VERSION ""

NS_ :

BS_:

BU_: FC

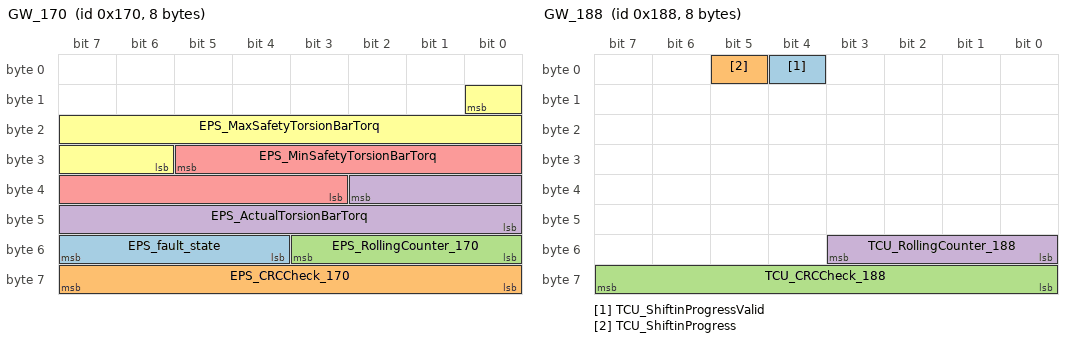
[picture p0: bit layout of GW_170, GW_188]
BO_ 368 GW_170: 8 Vector__XXX
 SG_ EPS_fault_state : 55|4@0+ (1,0) [0|15] ""  FC
 SG_ EPS_CRCCheck_170 : 63|8@0+ (1,0) [0|255] ""  FC
 SG_ EPS_RollingCounter_170 : 51|4@0+ (1,0) [0|15] ""  FC
 SG_ EPS_ActualTorsionBarTorq : 34|11@0+ (0.02,-20.48) [-20.48|20.44] "Nm"  FC
 SG_ EPS_MinSafetyTorsionBarTorq : 29|11@0+ (0.02,-20.48) [-20.48|20.44] "Nm"  FC
 SG_ EPS_MaxSafetyTorsionBarTorq : 8|11@0+ (0.02,-20.48) [-20.48|20.44] "Nm"  FC

BO_ 392 GW_188: 8 Vector__XXX
 SG_ TCU_ShiftinProgressValid : 4|1@0+ (1,0) [0|1] ""  FC
 SG_ TCU_ShiftinProgress : 5|1@0+ (1,0) [0|1] ""  FC
 SG_ TCU_CRCCheck_188 : 63|8@0+ (1,0) [0|255] ""  FC
 SG_ TCU_RollingCounter_188 : 51|4@0+ (1,0) [0|15] ""  FC

BO_ 580 FC_244: 64 FC
 SG_ ADS__RollingCounter_244 : 427|4@0+ (1,0) [0|15] "" Vector__XXX
 SG_ ADS_CRCCheck_244 : 439|16@0+ (1,0) [0|65535] "" Vector__XXX
 SG_ ADS_EOMTOReq : 155|2@0+ (1,0) [0|3] "" Vector__XXX
 SG_ ACC_HandsOnReq : 158|3@0+ (1,0) [0|7] "" Vector__XXX
 SG_ ACC_DynamicWarningLevel : 145|3@0+ (1,0) [0|7] "" Vector__XXX
 SG_ ACC_SafetyNotice : 136|7@0+ (1,0) [0|127] "" Vector__XXX
 SG_ ACC_LatTakeoverReq : 138|2@0+ (1,0) [0|3] "" Vector__XXX
 SG_ ACC_LngTakeOverReq : 140|2@0+ (1,0) [0|3] "" Vector__XXX
 SG_ ACC_TakeOverReq : 142|2@0+ (1,0) [0|3] "" Vector__XXX
 SG_ ACC_ADCNotice : 135|9@0+ (1,0) [0|511] "" Vector__XXX
 SG_ ACC_RWU_Parking_Request_Valid : 36|1@0+ (1,0) [0|1] "" Vector__XXX
 SG_ ACC_RWU_Parking_Request : 35|1@0+ (1,0) [0|1] "" Vector__XXX
 SG_ ACC_CDP_Parking_Request_Valid : 34|1@0+ (1,0) [0|1] "" Vector__XXX
 SG_ ACC_CDP_Parking_Request : 33|1@0+ (1,0) [0|1] "" Vector__XXX
 SG_ ACC_LDWShakeLevStatus : 21|2@0+ (1,0) [0|3] "" Vector__XXX
 SG_ ACC_TextInfoForDriver : 30|6@0+ (1,0) [0|63] "" Vector__XXX
 SG_ ADS_Authernticator_244 : 463|56@0+ (1,0) [0|0] "" Vector__XXX
 SG_ ADS_ResetFlag_244 : 449|2@0+ (1,0) [0|3] "" Vector__XXX
 SG_ ADS_MesssageCounter_244 : 455|6@0+ (1,0) [0|63] "" Vector__XXX
 SG_ ACC_CRCCheck_25E : 127|8@0+ (1,0) [0|255] "" Vector__XXX
 SG_ ACC_RollingCounter_25E : 115|4@0+ (1,0) [0|15] "" Vector__XXX
 SG_ ACC_AEBCtrlType : 104|4@0+ (1,0) [0|15] "" Vector__XXX
 SG_ ACC_FuelCutOffPrevention : 116|1@0+ (1,0) [0|1] "" Vector__XXX
 SG_ ACC_AccTrqReqActive : 106|1@0+ (1,0) [0|1] "" Vector__XXX
 SG_ ACC_AccTrqReq : 100|10@0+ (0.097847,0) [0|99.999634] "%" Vector__XXX
 SG_ ACC_AEBVehilceHoldReq : 90|1@0+ (1,0) [0|1] "" Vector__XXX
 SG_ ACC_FCWPreWarning : 91|1@0+ (1,0) [0|1] "" Vector__XXX
 SG_ ACC_FCWLatentWarning : 92|1@0+ (1,0) [0|1] "" Vector__XXX
 SG_ ACC_FCWActive : 93|1@0+ (1,0) [0|1] "" Vector__XXX
 SG_ ACC_PrefillActive : 94|1@0+ (1,0) [0|1] "" Vector__XXX
 SG_ ACC_AWBActive : 95|1@0+ (1,0) [0|1] "" Vector__XXX
 SG_ ACC_AWBlevel : 83|4@0+ (1,0) [0|15] "" Vector__XXX
 SG_ ACC_ABAActive : 84|1@0+ (1,0) [0|1] "" Vector__XXX
 SG_ ACC_ABAlevel : 86|2@0+ (1,0) [0|3] "" Vector__XXX
 SG_ ACC_AEBActive : 87|1@0+ (1,0) [0|1] "" Vector__XXX
 SG_ ACC_AEBTargetDeceleration : 71|16@0+ (0.0005,-16) [-16|16] "m/s2" Vector__XXX
 SG_ ACC_EmergencyDataRrdReq : 23|2@0+ (1,0) [0|3] "" Vector__XXX
 SG_ ACC_CRCCheck_24E : 63|8@0+ (1,0) [0|255] "" Vector__XXX
 SG_ ACC_RollingCounter_24E : 51|4@0+ (1,0) [0|15] "" Vector__XXX
 SG_ ACC_Driveoff_Request : 55|1@0+ (1,0) [0|1] "" Vector__XXX
 SG_ ACC_ACCMode : 54|3@0+ (1,0) [0|7] "" Vector__XXX
 SG_ ACC_CCMode : 47|3@0+ (1,0) [0|7] "" Vector__XXX
 SG_ ACC_CDDActive : 44|1@0+ (1,0) [0|1] "" Vector__XXX
 SG_ ACC_LimitSwitchArbitration : 43|2@0+ (1,0) [0|3] "" Vector__XXX
 SG_ ACC_EngineStartStopRequest : 41|2@0+ (1,0) [0|3] "" Vector__XXX
 SG_ ACC_DecToStop : 31|1@0+ (1,0) [0|1] "" Vector__XXX
 SG_ ACC_TCUCreepProhibition : 32|1@0+ (1,0) [0|1] "" Vector__XXX
 SG_ ACC_LKAStatus : 13|2@0+ (1,0) [0|3] "" Vector__XXX
 SG_ ACC_LDWVibrationWarningReq : 11|2@0+ (1,0) [0|3] "" Vector__XXX
 SG_ ACC_LDWStatus : 9|2@0+ (1,0) [0|3] "" Vector__XXX
 SG_ ACC_ACCTargetAcceleration : 7|8@0+ (0.05,-5) [-5|7.75] "m/s2" Vector__XXX

BO_ 583 APA_247: 32 Vector__XXX
 SG_ APA_APAOnOff : 6|1@0+ (1,0) [0|1] ""  FC

BO_ 664 GW_298: 8 Vector__XXX
 SG_ BCM_DriverDoorLockStatus : 44|2@0+ (1,0) [0|3] ""  FC
 SG_ BCM_LeftRearDoorStatus : 40|1@0+ (1,0) [0|1] ""  FC

BO_ 775 FC_307: 64 FC
 SG_ AD_LatDeviationDis : 55|3@0+ (1,0) [0|7] "" Vector__XXX
 SG_ AD_LatDeviationReason : 34|3@0+ (1,0) [0|7] "" Vector__XXX
 SG_ AD_IACCSuspendReason : 39|3@0+ (1,0) [0|7] "" Vector__XXX
 SG_ ACC_IACCProhibitionTime : 226|7@0+ (1,0) [0|127] "s" Vector__XXX
 SG_ ACC_Line_RR_Id : 479|8@0+ (1,0) [0|255] "" Vector__XXX
 SG_ ACC_Line_R_Id : 471|8@0+ (1,0) [0|255] "" Vector__XXX
 SG_ ACC_Line_LL_Id : 463|8@0+ (1,0) [0|255] "" Vector__XXX
 SG_ ACC_Line_L_Id : 455|8@0+ (1,0) [0|255] "" Vector__XXX
 SG_ ACC_RRLanecolor : 494|3@0+ (1,0) [0|7] "" Vector__XXX
 SG_ ACC_RLanecolor : 481|3@0+ (1,0) [0|7] "" Vector__XXX
 SG_ ACC_LLLanecolor : 484|3@0+ (1,0) [0|7] "" Vector__XXX
 SG_ ACC_LLanecolor : 487|3@0+ (1,0) [0|7] "" Vector__XXX
 SG_ ACC_VehicleStartRemindSts : 220|2@0+ (1,0) [0|3] "" Vector__XXX
 SG_ ADS_ResetSts : 218|3@0+ (1,0) [0|7] "" Vector__XXX
 SG_ ADS_IRLCEnable : 25|2@0+ (1,0) [0|3] "" Vector__XXX
 SG_ ADS_AutoDriveState : 10|3@0+ (1,0) [0|7] "-" Vector__XXX
 SG_ ACC_CRCCheck_35F : 255|8@0+ (1,0) [0|255] "" Vector__XXX
 SG_ ACC_RollingCounter_35F : 243|4@0+ (1,0) [0|15] "" Vector__XXX
 SG_ ACC_CSLAEnableStatus : 245|2@0+ (1,0) [0|3] "" Vector__XXX
 SG_ ACC_CSLSetReq : 227|1@0+ (1,0) [0|1] "" Vector__XXX
 SG_ ACC_HostPotentialTargetDirection : 231|3@0+ (1,0) [0|7] "" Vector__XXX
 SG_ ACC_HostPotentialTargetType : 199|4@0+ (1,0) [0|15] "" Vector__XXX
 SG_ ACC_HostPotentialTargetLatRange : 214|10@0+ (0.1,-50) [-50|50] "m" Vector__XXX
 SG_ ACC_HostPotentialTargetLngRange : 207|9@0+ (0.5,-70) [-70|180] "m" Vector__XXX
 SG_ ACC_HostPotentialTargetDetection : 194|3@0+ (1,0) [0|7] "" Vector__XXX
 SG_ ACC_CRCCheck_344 : 191|8@0+ (1,0) [0|255] "" Vector__XXX
 SG_ ACC_RollingCounter_344 : 179|4@0+ (1,0) [0|15] "" Vector__XXX
 SG_ ACC_FLTarget2Type : 183|4@0+ (1,0) [0|15] "" Vector__XXX
 SG_ ACC_FLTarget2LngRange : 160|9@0+ (0.5,-70) [-70|180] "m" Vector__XXX
 SG_ ACC_FLTarget2Detection : 164|3@0+ (1,0) [0|7] "" Vector__XXX
 SG_ ACC_FLTarget2Direction : 167|3@0+ (1,0) [0|7] "" Vector__XXX
 SG_ ACC_FLTarget1Direction : 158|3@0+ (1,0) [0|7] "" Vector__XXX
 SG_ ACC_FLTarget1Type : 146|4@0+ (1,0) [0|15] "" Vector__XXX
 SG_ ACC_FLTarget1LatRange : 140|10@0+ (0.1,-50) [-50|50] "m" Vector__XXX
 SG_ ACC_FLTarget1LngRange : 133|9@0+ (0.5,-70) [-70|180] "m" Vector__XXX
 SG_ ACC_FLTarget1Detection : 155|3@0+ (1,0) [0|7] "" Vector__XXX
 SG_ ACC_CRCCheck_322 : 127|8@0+ (1,0) [0|255] "" Vector__XXX
 SG_ ACC_RollingCounter_322 : 115|4@0+ (1,0) [0|15] "" Vector__XXX
 SG_ ACC_HostTargetDetection : 87|3@0+ (1,0) [0|7] "" Vector__XXX
 SG_ ACC_ACCTargetDirection : 104|3@0+ (1,0) [0|7] "" Vector__XXX
 SG_ ACC_ACCTargetLatRange : 99|10@0+ (0.1,-50) [-50|50] "m" Vector__XXX
 SG_ ACC_ACCTargetRelSpd : 92|9@0+ (1,-250) [-250|250] "km/h" Vector__XXX
 SG_ ACC_DistanceAlertLevel : 74|3@0+ (1,0) [0|7] "" Vector__XXX
 SG_ ACC_ACCTargetType : 78|4@0+ (1,0) [0|15] "" Vector__XXX
 SG_ ACC_FRadarCalibrationStatus : 94|2@0+ (1,0) [0|3] "" Vector__XXX
 SG_ ACC_ACCTargetLngRange : 71|9@0+ (0.5,-70) [-70|180] "m" Vector__XXX
 SG_ ACC_CRCCheck_35E : 63|8@0+ (1,0) [0|255] "" Vector__XXX
 SG_ ACC_RollingCounter_35E : 51|4@0+ (1,0) [0|15] "" Vector__XXX
 SG_ ACC_SaftyBeltVibrationReq : 42|1@0+ (1,0) [0|1] "" Vector__XXX
 SG_ ACC_SaftyBelt_Tightened : 41|2@0+ (1,0) [0|3] "" Vector__XXX
 SG_ ACC_CruiseSetStatus : 46|3@0+ (1,0) [0|7] "" Vector__XXX
 SG_ ACC_ACCObjSoundEnable : 36|2@0+ (1,0) [0|3] "" Vector__XXX
 SG_ ACC_FCWSettingStatus : 30|3@0+ (1,0) [0|7] "" Vector__XXX
 SG_ ACC_AEBEnable : 26|1@0+ (1,0) [0|1] "" Vector__XXX
 SG_ ACC_ACCEPBrequest : 23|1@0+ (1,0) [0|1] "" Vector__XXX
 SG_ ACC_ObjValid : 13|1@0+ (1,0) [0|1] "" Vector__XXX
 SG_ ACC_TimeGapSet : 18|3@0+ (1,0) [0|7] "" Vector__XXX
 SG_ ACC_DistanceLevel : 22|3@0+ (1,0) [0|7] "" Vector__XXX
 SG_ ACC_SetSpeed : 6|8@0+ (1,0) [0|254] "Km/h" Vector__XXX

BO_ 786 FC_312: 64 FC
 SG_ ACC_Selflearning_status : 13|2@0+ (1,0) [0|3] "" Vector__XXX
 SG_ ACC_Selflearning_angle : 238|11@0+ (0.01,-10.25) [-10.25|10.22] "degree" Vector__XXX
 SG_ ADS_ADSVoiceRequest : 102|9@0+ (1,0) [0|511] "" Vector__XXX
 SG_ ADS_ADSRoadVoiceEnableSts : 89|1@0+ (1,0) [0|1] "" Vector__XXX
 SG_ ADS_ADSLaneChangeVoiceEnableSts : 88|1@0+ (1,0) [0|1] "" Vector__XXX
 SG_ ADS_ADSSafeVoiceEnableSts : 103|1@0+ (1,0) [0|1] "" Vector__XXX
 SG_ ADS_NDANavEnableStatus : 108|1@0+ (1,0) [0|1] "" Vector__XXX
 SG_ ADS_NDAAudioWarEnableStatus : 107|1@0+ (1,0) [0|1] "" Vector__XXX
 SG_ ADS_NDAEnableStatus : 106|1@0+ (1,0) [0|1] "" Vector__XXX
 SG_ ADS_ALCDirection : 105|2@0+ (1,0) [0|3] "" Vector__XXX
 SG_ ADS_ALCTextInfoForDriver : 119|4@0+ (1,0) [0|15] "" Vector__XXX
 SG_ ADS_LaneChangeStyle : 90|1@0+ (1,0) [0|1] "" Vector__XXX
 SG_ ADS_UDLCVoiceRecStatus : 93|3@0+ (1,0) [0|7] "" Vector__XXX
 SG_ ADS_EOMStatus : 74|3@0+ (1,0) [0|7] "" Vector__XXX
 SG_ ADS_EOMSeatSteeringAdjustReq : 94|1@0+ (1,0) [0|1] "" Vector__XXX
 SG_ ADS_EOMDriverHeadPos : 77|3@0+ (1,0) [0|7] "" Vector__XXX
 SG_ ADS_EOMActiveReq : 95|1@0+ (1,0) [0|1] "" Vector__XXX
 SG_ ADS_SpdLimitedStatus : 79|2@0+ (1,0) [0|3] "" Vector__XXX
 SG_ ADS_CRCCheck_3D7 : 255|8@0+ (1,0) [0|255] "" Vector__XXX
 SG_ ADS_RollingCounter_3D7 : 243|4@0+ (1,0) [0|15] "" Vector__XXX
 SG_ ACC_SunroofControl : 231|8@0+ (1,0) [0|255] "" Vector__XXX
 SG_ ACC_RightRearWindowControl : 222|7@0+ (1,0) [0|100] "%" Vector__XXX
 SG_ ACC_LeftRearWindowControl : 214|7@0+ (1,0) [0|100] "%" Vector__XXX
 SG_ ACC_PassengerWindowControl : 206|7@0+ (1,0) [0|100] "%" Vector__XXX
 SG_ ACC_DriverWindowControl : 198|7@0+ (1,0) [0|100] "%" Vector__XXX
 SG_ ADS_UDLCTextInfoForDriver : 183|4@0+ (1,0) [0|15] "" Vector__XXX
 SG_ ADS_ToTargetLatDistance : 87|8@0+ (0.1,-10) [-10|10] "m" Vector__XXX
 SG_ ADS_AutoWiperShift_Rqe : 155|1@0+ (1,0) [0|1] "" Vector__XXX
 SG_ ACC_HornCommand : 159|2@0+ (1,0) [0|3] "" Vector__XXX
 SG_ ADS_AutoHeadlightshift_Req : 163|1@0+ (1,0) [0|1] "" Vector__XXX
 SG_ ADS_HighBeamLampOnRequest : 174|2@0+ (1,0) [0|3] "" Vector__XXX
 SG_ ADS_LowBeamLampOnRequest : 132|2@0+ (1,0) [0|3] "" Vector__XXX
 SG_ ADS_LightFrequencyRequest : 150|3@0+ (1,0) [0|7] "" Vector__XXX
 SG_ ADS_LightBrightRequest : 137|3@0+ (1,0) [0|7] "" Vector__XXX
 SG_ ADS_LightFlashRequest : 171|1@0+ (1,0) [0|1] "" Vector__XXX
 SG_ ADS_LightColorRequest : 170|3@0+ (1,0) [0|7] "" Vector__XXX
 SG_ ADS_LightingReq : 175|1@0+ (1,0) [0|1] "" Vector__XXX
 SG_ ADS_rescueReq : 65|2@0+ (1,0) [0|1] "" Vector__XXX
 SG_ ADS_SafeStopSts : 67|2@0+ (1,0) [0|3] "" Vector__XXX
 SG_ ADS_EyesOffWarningInhi : 68|1@0+ (1,0) [0|1] "" Vector__XXX
 SG_ ADS_EOMWarnning : 71|3@0+ (1,0) [0|7] "" Vector__XXX
 SG_ ADS_ESSEnable : 157|1@0+ (1,0) [0|1] "" Vector__XXX
 SG_ ADS_CRCCheck_358 : 191|8@0+ (1,0) [0|255] "" Vector__XXX
 SG_ ADS_RollingCounter_358 : 179|4@0+ (1,0) [0|15] "" Vector__XXX
 SG_ ADS_RLaneColor : 162|3@0+ (1,0) [0|7] "" Vector__XXX
 SG_ ADS_LLaneColor : 166|3@0+ (1,0) [0|7] "" Vector__XXX
 SG_ ADS_UDLCTurnRightRequest : 156|1@0+ (1,0) [0|1] "" Vector__XXX
 SG_ ADS_UDLCRightStatus : 147|4@0+ (1,0) [0|15] "" Vector__XXX
 SG_ ADS_UDLCTurnLeftRequest : 167|1@0+ (1,0) [0|1] "" Vector__XXX
 SG_ ADS_UDLCTurnLightReq : 154|3@0+ (1,0) [0|7] "" Vector__XXX
 SG_ ADS_UDLCLeftStatus : 141|4@0+ (1,0) [0|15] "" Vector__XXX
 SG_ ADS_UDLCStatus : 129|4@0+ (1,0) [0|15] "" Vector__XXX
 SG_ ADS_UDLCEnableStatus : 130|1@0+ (1,0) [0|1] "" Vector__XXX
 SG_ ADS_ESSMode : 135|3@0+ (1,0) [0|7] "" Vector__XXX
 SG_ ADS_CRCCheck_342 : 127|8@0+ (1,0) [0|255] "" Vector__XXX
 SG_ ADS_RollingCounter_342 : 115|4@0+ (1,0) [0|15] "" Vector__XXX
 SG_ ACC_CRCCheck_3E4 : 63|8@0+ (1,0) [0|255] "" Vector__XXX
 SG_ ACC_RollingCounter_3E4 : 51|4@0+ (1,0) [0|15] "" Vector__XXX
 SG_ ACC_AEBTargetDirection : 47|3@0+ (1,0) [0|7] "" Vector__XXX
 SG_ ACC_AEBTargetDetection : 44|1@0+ (1,0) [0|1] "" Vector__XXX
 SG_ ACC_AEBTargetType : 43|4@0+ (1,0) [0|15] "" Vector__XXX
 SG_ ACC_RLaneDistanceFusion : 38|7@0+ (0.05,-1) [-1|5] "m" Vector__XXX
 SG_ ACC_LLaneDistanceFusion : 30|7@0+ (0.05,-1) [-1|5] "m" Vector__XXX
 SG_ ACC_HostPotentialTargetID : 19|4@0+ (1,0) [0|15] "" Vector__XXX
 SG_ ACC_FRTarget2ID : 55|4@0+ (1,0) [0|15] "" Vector__XXX
 SG_ ACC_FRTarget1ID : 11|4@0+ (1,0) [0|15] "" Vector__XXX
 SG_ ACC_FLTarget2ID : 23|4@0+ (1,0) [0|15] "" Vector__XXX
 SG_ ACC_FLTarget1ID : 1|4@0+ (1,0) [0|15] "" Vector__XXX
 SG_ ACC_ACCTargetID : 6|4@0+ (1,0) [0|15] "" Vector__XXX

BO_ 832 IBCMR_340: 8 Vector__XXX
 SG_ AC_FrBlowType : 2|3@0+ (1,0) [0|7] ""  FC

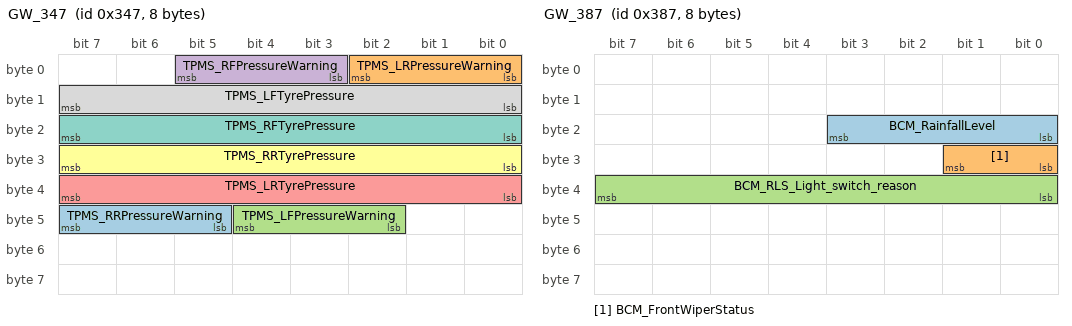
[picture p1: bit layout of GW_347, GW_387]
BO_ 839 GW_347: 8 Vector__XXX
 SG_ TPMS_RRPressureWarning : 47|3@0+ (1,0) [0|7] ""  FC
 SG_ TPMS_LRPressureWarning : 2|3@0+ (1,0) [0|7] ""  FC
 SG_ TPMS_LFPressureWarning : 44|3@0+ (1,0) [0|7] ""  FC
 SG_ TPMS_RFPressureWarning : 5|3@0+ (1,0) [0|7] ""  FC
 SG_ TPMS_LRTyrePressure : 39|8@0+ (1.373,0) [0|350] "KPa"  FC
 SG_ TPMS_RRTyrePressure : 31|8@0+ (1.373,0) [0|350] "KPa"  FC
 SG_ TPMS_RFTyrePressure : 23|8@0+ (1.373,0) [0|350] "KPa"  FC
 SG_ TPMS_LFTyrePressure : 15|8@0+ (1.373,0) [0|350] "KPa"  FC

BO_ 869 GW_365: 32 Vector__XXX
 SG_ IMS_RollingCounter_3A7 : 179|4@0+ (1,0) [0|15] ""  FC
 SG_ IMS_CRCCheck_3A7 : 191|8@0+ (1,0) [0|255] ""  FC
 SG_ IMS_RollingCounter_360 : 115|4@0+ (1,0) [0|15] ""  FC
 SG_ IMS_CRCCheck_360 : 127|8@0+ (1,0) [0|255] ""  FC
 SG_ IMS_HeadDetectSts_Yaw : 87|8@0+ (1,-75) [-75|75] "度"  FC
 SG_ IMS_HeadDetectSts_Roll : 79|8@0+ (1,-45) [-45|45] "度"  FC
 SG_ IMS_HeadDetectSts_Pitch : 71|8@0+ (1,-25) [-25|45] "度"  FC
 SG_ IMS_RollingCounter_356 : 51|4@0+ (1,0) [0|15] ""  FC
 SG_ IMS_CRCCheck_356 : 63|8@0+ (1,0) [0|255] ""  FC
 SG_ IMS_IMSStatus : 0|3@0+ (1,0) [0|7] ""  FC
 SG_ IMS_EyeGazeStatus : 21|8@0+ (1,-75) [-75|75] "度"  FC
 SG_ IMS_EyeDetectSatus : 13|8@0+ (1,0) [0|100] "%"  FC
 SG_ IMS_DrowsinessStatus : 3|3@0+ (1,0) [0|7] ""  FC
 SG_ IMS_DriverHeadDetect : 5|2@0+ (1,0) [0|3] ""  FC
 SG_ IMS_DistractionStatus : 7|2@0+ (1,0) [0|3] ""  FC

BO_ 870 IBCMR_366: 8 Vector__XXX
 SG_ AC_EnvironmentalTemp : 23|8@0+ (0.5,-40) [-40|87] "degreeC"  FC
 SG_ AC_EnvironmentalTempVD : 8|1@0+ (1,0) [0|1] ""  FC

BO_ 903 GW_387: 8 Vector__XXX
 SG_ BCM_RainfallLevel : 19|4@0+ (1,0) [0|15] ""  FC
 SG_ BCM_FrontWiperStatus : 25|2@0+ (1,0) [0|3] ""  FC
 SG_ BCM_RLS_Light_switch_reason : 39|8@0+ (1,0) [0|255] ""  FC

BO_ 912 GW_390: 8 Vector__XXX
 SG_ BCM_SOH_LifePercent : 15|8@0+ (1,0) [0|100] "%"  FC
 SG_ BCM_PMSLevel : 5|3@0+ (1,0) [0|7] ""  FC

BO_ 918 GW_396: 8 Vector__XXX
 SG_ BCM_SunroofStatus : 0|1@0+ (1,0) [0|1] ""  FC

BO_ 1287 GW_507: 64 Vector__XXX
 SG_ HU_NDAAudioWarEnable : 169|2@0+ (1,0) [0|3] ""  FC
 SG_ HU_TJPEnable : 49|2@0+ (1,0) [0|3] ""  FC
 SG_ HU_VC_CruiseSetSpeed : 151|8@0+ (1,0) [0|255] ""  FC
 SG_ HU_VC_CruiseSetDistance : 142|3@0+ (1,0) [0|7] ""  FC
 SG_ HU_VC_CruiseControl : 138|3@0+ (1,0) [0|7] ""  FC
 SG_ HU_FCWSetting : 165|3@0+ (1,0) [0|7] ""  FC
 SG_ HU_ACCObjEnable : 128|2@0+ (1,0) [0|3] ""  FC
 SG_ HU_CruiseControlSet : 135|3@0+ (1,0) [0|7] ""  FC
 SG_ HU_AutoBrakeEnable : 131|1@0+ (1,0) [0|1] ""  FC
 SG_ HU_IACCEnable : 29|2@0+ (1,0) [0|3] ""  FC
 SG_ HU_LDWShakeLev : 23|2@0+ (1,0) [0|3] ""  FC
 SG_ HU_RCTAEnable : 0|2@0+ (1,0) [0|3] ""  FC
 SG_ HU_HMAEnable : 12|1@0+ (1,0) [0|1] ""  FC
 SG_ HU_TSRSwitch : 11|1@0+ (1,0) [0|1] ""  FC
 SG_ HU_LASWarningModeSelection : 10|3@0+ (1,0) [0|7] ""  FC
 SG_ HU_LASModeSelection : 5|3@0+ (1,0) [0|7] ""  FC
 SG_ HU_OverspeedWarningOffset : 38|5@0+ (1,-10) [-10|10] ""  FC
 SG_ HU_OverspeedWarningEnable : 33|2@0+ (1,0) [0|3] ""  FC
 SG_ HU_OverspeedSoundWarEnable : 31|2@0+ (1,0) [0|3] ""  FC

BO_ 1302 GW_516: 32 Vector__XXX
 SG_ HU_LocalTimeSystem : 111|2@0+ (1,0) [0|3] ""  FC
 SG_ HU_LocalTimeSecond : 109|6@0+ (1,0) [0|59] "second"  FC
 SG_ HU_LocalTimeMinute : 101|6@0+ (1,0) [0|59] "minute"  FC
 SG_ HU_LocalTimeHour : 92|5@0+ (1,0) [0|23] "hour"  FC
 SG_ HU_LocalTimeDate : 84|5@0+ (1,0) [1|31] "day"  FC
 SG_ HU_LocalTimeYear : 119|8@0+ (1,2013) [2013|2268] "year"  FC
 SG_ HU_LocalTimeMonth : 75|4@0+ (1,0) [1|12] "month"  FC
 SG_ HU_LocalTimeValid : 71|1@0+ (1,0) [0|1] ""  FC
 SG_ HU_CurrentLocationLatitude : 35|28@0+ (1E-006,-134.217727) [-90|90] "degree"  FC
 SG_ HU_CurrentLocationLongitude : 4|29@0+ (1E-006,-268.435455) [-180|180] "degree"  FC
 SG_ HU_CurrentLocationValid : 7|1@0+ (1,0) [0|1] ""  FC

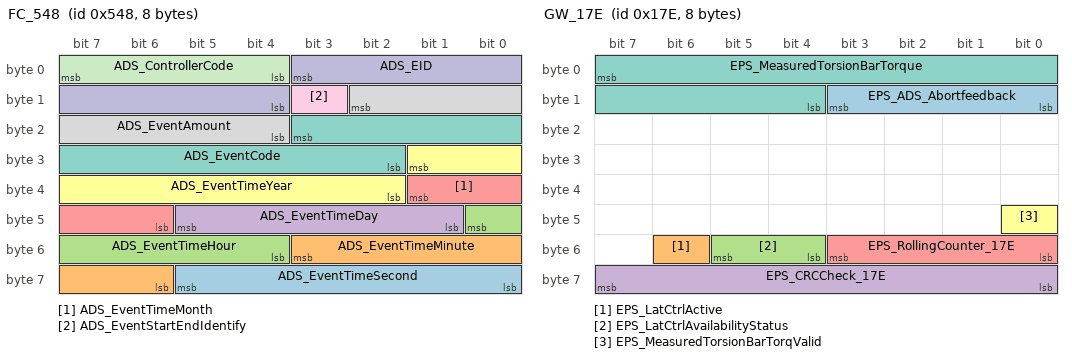
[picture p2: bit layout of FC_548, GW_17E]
BO_ 1352 FC_548: 8 FC
 SG_ ADS_EventTimeSecond : 61|6@0+ (1,0) [0|59] "秒" Vector__XXX
 SG_ ADS_EventTimeMinute : 51|6@0+ (1,0) [0|59] "分" Vector__XXX
 SG_ ADS_EventTimeHour : 40|5@0+ (1,0) [0|23] "时" Vector__XXX
 SG_ ADS_EventTimeDay : 45|5@0+ (1,0) [0|31] "日" Vector__XXX
 SG_ ADS_EventTimeMonth : 33|4@0+ (1,0) [0|15] "月" Vector__XXX
 SG_ ADS_EventTimeYear : 25|8@0+ (1,2013) [2013|2268] "年" Vector__XXX
 SG_ ADS_EventCode : 19|10@0+ (1,0) [0|1023] "" Vector__XXX
 SG_ ADS_EventAmount : 10|7@0+ (1,0) [0|127] "" Vector__XXX
 SG_ ADS_EventStartEndIdentify : 11|1@0+ (1,0) [0|1] "" Vector__XXX
 SG_ ADS_EID : 3|8@0+ (1,0) [0|255] "" Vector__XXX
 SG_ ADS_ControllerCode : 7|4@0+ (1,0) [0|15] "" Vector__XXX

BO_ 1554 APA_612: 8 Vector__XXX
 SG_ DVR_EmergencyRecordStatus : 29|2@0+ (1,0) [0|3] ""  FC
 SG_ DVR_Error : 15|1@0+ (1,0) [0|1] ""  FC

BO_ 382 GW_17E: 8 Vector__XXX
 SG_ EPS_ADS_Abortfeedback : 11|4@0+ (1,0) [0|15] ""  FC
 SG_ EPS_LatCtrlActive : 54|1@0+ (1,0) [0|1] ""  FC
 SG_ EPS_LatCtrlAvailabilityStatus : 53|2@0+ (1,0) [0|3] ""  FC
 SG_ EPS_CRCCheck_17E : 63|8@0+ (1,0) [0|255] ""  FC
 SG_ EPS_RollingCounter_17E : 51|4@0+ (1,0) [0|15] ""  FC
 SG_ EPS_MeasuredTorsionBarTorqValid : 40|1@0+ (1,0) [0|1] ""  FC
 SG_ EPS_MeasuredTorsionBarTorque : 7|12@0+ (0.01,-20.48) [-20.48|20.46] "Nm"  FC

BO_ 398 GW_18E: 32 Vector__XXX
 SG_ EMS_RollingCounter_18E : 235|4@0+ (1,0) [0|15] ""  FC
 SG_ EMS_CRCCheck_18E : 247|16@0+ (1,0) [0|65535] ""  FC
 SG_ EMS_CRCCheck_1A6 : 191|8@0+ (1,0) [0|255] ""  FC
 SG_ EMS_RollingCounter_1A6 : 179|4@0+ (1,0) [0|15] ""  FC
 SG_ EMS_EngineStatus : 183|2@0+ (1,0) [0|3] ""  FC
 SG_ EMS_MinIndicatedTorq : 167|8@0+ (0.392,0) [0|99.568] "%"  FC
 SG_ EMS_MaxIndicatedTorq : 159|8@0+ (0.392,0) [0|99.568] "%"  FC
 SG_ EMS_TorqueConstant : 151|8@0+ (10,0) [0|2540] "NM"  FC
 SG_ EMS_RollingCounter_196 : 115|4@0+ (1,0) [0|15] ""  FC
 SG_ EMS_CRCCheck_196 : 127|8@0+ (1,0) [0|255] ""  FC
 SG_ EMS_AccPedal : 111|8@0+ (0.392,0) [0|99.568] "%"  FC
 SG_ EMS_EngineSpeed : 87|16@0+ (0.25,0) [0|16383.5] "Rpm"  FC
 SG_ EMS_AccpedelError : 74|1@0+ (1,0) [0|1] ""  FC
 SG_ EMS_EngineSpeedError : 76|1@0+ (1,0) [0|1] ""  FC
 SG_ EMS_EngineFuelCutOff : 78|1@0+ (1,0) [0|1] ""  FC
 SG_ EMS_BrakePedalStatus : 119|2@0+ (1,0) [0|3] ""  FC
 SG_ EMS_RealAccPedal : 71|8@0+ (0.392,0) [0|99.568] "%"  FC
 SG_ EMS_RollingCounter_184 : 51|4@0+ (1,0) [0|15] ""  FC
 SG_ EMS_CRCCheck_184 : 63|8@0+ (1,0) [0|255] ""  FC
 SG_ EMS_IndicatedRealEngTorq : 39|16@0+ (0.001526,0) [0|99.99878] "%"  FC
 SG_ EMS_FrictionalTorq : 23|16@0+ (0.001526,0) [0|99.99878] "%"  FC
 SG_ EMS_IndicatedDriverReqTorq : 7|16@0+ (0.001526,0) [0|99.99878] "%"  FC
 SG_ EMS_TorqFailure : 53|1@0+ (1,0) [0|1] ""  FC

BO_ 442 FC_1BA: 32 FC
 SG_ ACC_LatAngReqActive : 35|1@0+ (1,0) [0|1] "" Vector__XXX
 SG_ ACC_LatAngReq : 17|14@0+ (0.1,-720) [-720|720] "degree" Vector__XXX
 SG_ ADS_Authernticator_1BA : 207|56@0+ (1,0) [0|0] "" Vector__XXX
 SG_ ADS_ResetFlag_1BA : 193|2@0+ (1,0) [0|3] "" Vector__XXX
 SG_ ADS_MesssageCounter_1BA : 199|6@0+ (1,0) [0|63] "" Vector__XXX
 SG_ ACC_CRCCheck_1BA_0 : 63|8@0+ (1,0) [0|255] "" Vector__XXX
 SG_ ACC_RollingCounter_1BA_0 : 51|4@0+ (1,0) [0|15] "" Vector__XXX
 SG_ ADS_ESSActive : 34|1@0+ (1,0) [0|1] "" Vector__XXX
 SG_ ACC_MotorTorqueMinLimitRequest : 12|11@0+ (0.02,-20.48) [-20.48|20.44] "Nm" Vector__XXX
 SG_ ACC_MotorTorqueMaxLimitRequest : 7|11@0+ (0.02,-20.48) [-20.48|20.44] "Nm" Vector__XXX

BO_ 588 GW_24C: 8 Vector__XXX
 SG_ TCU_RollingCounter_24C : 51|4@0+ (1,0) [0|15] ""  FC

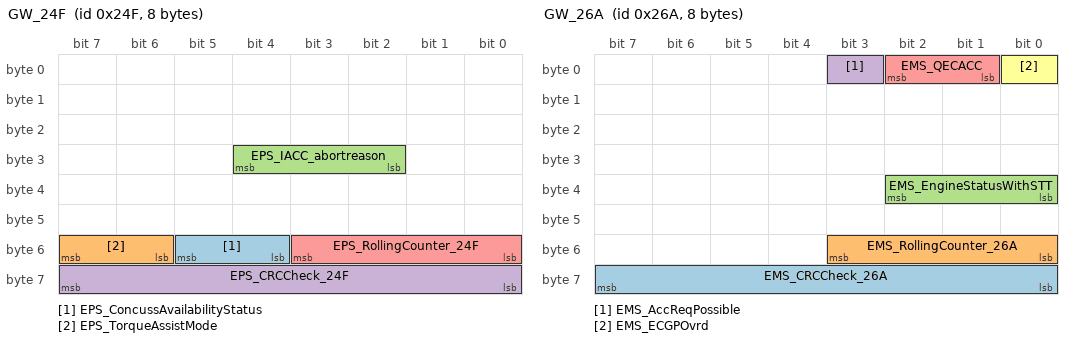
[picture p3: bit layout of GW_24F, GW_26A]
BO_ 591 GW_24F: 8 Vector__XXX
 SG_ EPS_ConcussAvailabilityStatus : 53|2@0+ (1,0) [0|3] ""  FC
 SG_ EPS_TorqueAssistMode : 55|2@0+ (1,0) [0|3] ""  FC
 SG_ EPS_IACC_abortreason : 28|3@0+ (1,0) [0|7] ""  FC
 SG_ EPS_CRCCheck_24F : 63|8@0+ (1,0) [0|255] ""  FC
 SG_ EPS_RollingCounter_24F : 51|4@0+ (1,0) [0|15] ""  FC

BO_ 618 GW_26A: 8 Vector__XXX
 SG_ EMS_CRCCheck_26A : 63|8@0+ (1,0) [0|255] ""  FC
 SG_ EMS_RollingCounter_26A : 51|4@0+ (1,0) [0|15] ""  FC
 SG_ EMS_EngineStatusWithSTT : 34|3@0+ (1,0) [0|7] ""  FC
 SG_ EMS_AccReqPossible : 3|1@0+ (1,0) [0|1] ""  FC
 SG_ EMS_QECACC : 2|2@0+ (1,0) [0|3] ""  FC
 SG_ EMS_ECGPOvrd : 0|1@0+ (1,0) [0|1] ""  FC

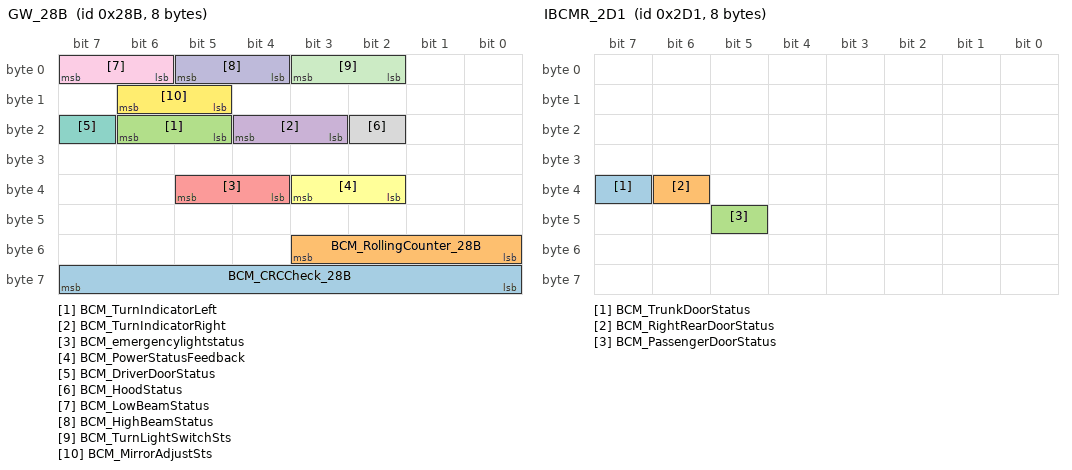
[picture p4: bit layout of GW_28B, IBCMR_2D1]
BO_ 651 GW_28B: 8 Vector__XXX
 SG_ BCM_CRCCheck_28B : 63|8@0+ (1,0) [0|255] ""  FC
 SG_ BCM_RollingCounter_28B : 51|4@0+ (1,0) [0|15] ""  FC
 SG_ BCM_TurnIndicatorLeft : 22|2@0+ (1,0) [0|3] ""  FC
 SG_ BCM_TurnIndicatorRight : 20|2@0+ (1,0) [0|3] ""  FC
 SG_ BCM_emergencylightstatus : 37|2@0+ (1,0) [0|3] ""  FC
 SG_ BCM_PowerStatusFeedback : 35|2@0+ (1,0) [0|3] ""  FC
 SG_ BCM_DriverDoorStatus : 23|1@0+ (1,0) [0|1] ""  FC
 SG_ BCM_HoodStatus : 18|1@0+ (1,0) [0|1] ""  FC
 SG_ BCM_LowBeamStatus : 7|2@0+ (1,0) [0|3] ""  FC
 SG_ BCM_HighBeamStatus : 5|2@0+ (1,0) [0|3] ""  FC
 SG_ BCM_TurnLightSwitchSts : 3|2@0+ (1,0) [0|3] ""  FC
 SG_ BCM_MirrorAdjustSts : 14|2@0+ (1,0) [0|3] ""  FC

BO_ 676 GW_2A4: 64 Vector__XXX
 SG_ RRC_RollingCounter_2A4 : 491|4@0+ (1,0) [0|15] ""  FC
 SG_ RRC_CRCCheck_2A4 : 503|16@0+ (1,0) [0|65535] ""  FC
 SG_ LCDAR_RCTBStatus : 17|2@0+ (1,0) [0|3] ""  FC
 SG_ LCDAR_CRCCheck_2AF : 63|8@0+ (1,0) [0|255] ""  FC
 SG_ LCDAR_RollingCounter_2AF : 51|4@0+ (1,0) [0|15] ""  FC
 SG_ LCDAR_ELK_oAlert : 25|2@0+ (1,0) [0|3] ""  FC
 SG_ LCDAR_ELK_oStatus : 27|2@0+ (1,0) [0|3] ""  FC
 SG_ LCDAR_Left_ELK_oAlert : 29|2@0+ (1,0) [0|3] ""  FC
 SG_ LCDAR_RCTBActive : 19|1@0+ (1,0) [0|1] ""  FC
 SG_ LCDAR_RCTBTargetDecel : 39|16@0+ (0.0005,-16) [-16|16] "m/s2"  FC
 SG_ LCDAR_RCTBEnable : 18|1@0+ (1,0) [0|1] ""  FC
 SG_ LCDAR_SystemStatus : 12|3@0+ (1,0) [0|7] ""  FC

BO_ 710 APA_2C6: 64 Vector__XXX
 SG_ APA_vehicleFrontdetect : 99|2@0+ (1,0) [0|3] ""  FC

BO_ 721 IBCMR_2D1: 8 Vector__XXX
 SG_ BCM_TrunkDoorStatus : 39|1@0+ (1,0) [0|1] ""  FC
 SG_ BCM_RightRearDoorStatus : 38|1@0+ (1,0) [0|1] ""  FC
 SG_ BCM_PassengerDoorStatus : 45|1@0+ (1,0) [0|1] ""  FC

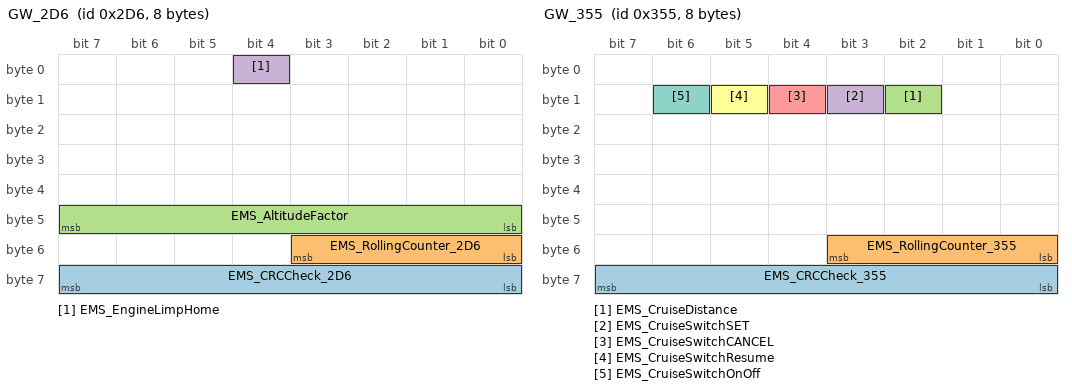
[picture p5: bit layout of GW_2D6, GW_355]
BO_ 726 GW_2D6: 8 Vector__XXX
 SG_ EMS_CRCCheck_2D6 : 63|8@0+ (1,0) [0|255] ""  FC
 SG_ EMS_RollingCounter_2D6 : 51|4@0+ (1,0) [0|15] ""  FC
 SG_ EMS_AltitudeFactor : 47|8@0+ (0.01575,0) [0|4] ""  FC
 SG_ EMS_EngineLimpHome : 4|1@0+ (1,0) [0|1] ""  FC

BO_ 794 FC_31A: 64 FC
 SG_ AD_HandsoffWarningExitReason : 42|3@0+ (1,0) [0|7] "" Vector__XXX
 SG_ ACC_LngTakeOverReqReason : 232|5@0+ (1,0) [0|31] "" Vector__XXX
 SG_ ACC_ELKAlert : 25|2@0+ (1,0) [0|3] "" Vector__XXX
 SG_ ADS_HWAEnableStatus : 180|1@0+ (1,0) [0|1] "" Vector__XXX
 SG_ ADS_IsInFence : 208|2@0+ (1,0) [0|3] "" Vector__XXX
 SG_ ADS_TJPEnableStatus : 67|1@0+ (1,0) [0|1] "" Vector__XXX
 SG_ ACC_CRCCheck_367 : 255|8@0+ (1,0) [0|255] "" Vector__XXX
 SG_ ACC_RollingCounter_367 : 243|4@0+ (1,0) [0|15] "" Vector__XXX
 SG_ ACC_LatPathHeadingAngle : 227|11@0- (0.1,0) [-90|90] "degree" Vector__XXX
 SG_ ACC_LatPathDY : 221|10@0- (0.01,0) [-5|5] "m" Vector__XXX
 SG_ ACC_ELKEnableStatus : 222|1@0+ (1,0) [0|1] "" Vector__XXX
 SG_ ACC_ELKInterventionMode : 210|2@0+ (1,0) [0|3] "" Vector__XXX
 SG_ ACC_ELKMode : 213|3@0+ (1,0) [0|7] "" Vector__XXX
 SG_ ACC_HostPedLatRange_1 : 205|8@0+ (0.2,-25) [-25|25] "m" Vector__XXX
 SG_ ACC_HostPedLngRange_1 : 195|6@0+ (1,0) [0|62] "m" Vector__XXX
 SG_ ACC_HostPedDetection_1 : 198|2@0+ (1,0) [0|3] "" Vector__XXX
 SG_ ACC_CRCCheck_30D : 191|8@0+ (1,0) [0|255] "" Vector__XXX
 SG_ ACC_RollingCounter_30D : 179|4@0+ (1,0) [0|15] "" Vector__XXX
 SG_ ACC_RRLaneDistance : 172|6@0+ (0.2,0) [0|12] "m" Vector__XXX
 SG_ ACC_RRLaneDetection : 174|2@0+ (1,0) [0|3] "" Vector__XXX
 SG_ ACC_LLLaneDistance : 165|6@0+ (0.2,0) [0|12] "m" Vector__XXX
 SG_ ACC_LLLaneDetection : 167|2@0+ (1,0) [0|3] "" Vector__XXX
 SG_ ACC_DoorCtrlReq : 145|2@0+ (1,0) [0|3] "" Vector__XXX
 SG_ ACC_HighBeamControl : 182|2@0+ (1,0) [0|3] "" Vector__XXX
 SG_ ACC_TargetBasedLateralControl : 150|2@0+ (1,0) [0|3] "" Vector__XXX
 SG_ ACC_IACCHWATextInfoForDriver : 143|5@0+ (1,0) [0|31] "" Vector__XXX
 SG_ ACC_EmergencyLightingRequest : 148|2@0+ (1,0) [0|3] "" Vector__XXX
 SG_ ACC_HandsoffFuncTextinfo : 158|4@0+ (1,0) [0|15] "" Vector__XXX
 SG_ ACC_HandsoffFuncStatus : 154|3@0+ (1,0) [0|7] "" Vector__XXX
 SG_ ACC_DriverHandsOffStatus : 137|2@0+ (1,0) [0|3] "" Vector__XXX
 SG_ ACC_IACCHWAMode : 135|3@0+ (1,0) [0|7] "" Vector__XXX
 SG_ ACC_CRCCheck_30A : 127|8@0+ (1,0) [0|255] "" Vector__XXX
 SG_ ACC_RollingCounter_30A : 115|4@0+ (1,0) [0|15] "" Vector__XXX
 SG_ ACC_LaneChangeStatus : 117|2@0+ (1,0) [0|3] "" Vector__XXX
 SG_ ACC_RoadCurvatureFar : 109|7@0+ (0.0005,-0.03) [-0.03|0.03] "1/m" Vector__XXX
 SG_ ACC_RoadCurvatureNear : 100|7@0+ (0.0005,-0.03) [-0.03|0.03] "1/m" Vector__XXX
 SG_ ACC_RoadCurvature : 91|7@0+ (0.0005,-0.03) [-0.03|0.03] "1/m" Vector__XXX
 SG_ ACC_IACCHWAEnable : 78|1@0+ (1,0) [0|1] "" Vector__XXX
 SG_ ACC_RLaneMarkerType : 70|3@0+ (1,0) [0|7] "" Vector__XXX
 SG_ ACC_LLaneMarkerType : 94|3@0+ (1,0) [0|7] "" Vector__XXX
 SG_ ACC_HostLaneRightStatus : 87|4@0+ (1,0) [0|15] "" Vector__XXX
 SG_ ACC_HostLaneLeftStatus : 83|4@0+ (1,0) [0|15] "" Vector__XXX
 SG_ ACC_LASWarningModeSelectionSts : 74|3@0+ (1,0) [0|7] "" Vector__XXX
 SG_ ACC_LASModeSelectionStatus : 66|3@0+ (1,0) [0|7] "" Vector__XXX
 SG_ ACC_CRCCheck_36D : 63|8@0+ (1,0) [0|255] "" Vector__XXX
 SG_ ACC_RollingCounter_36D : 51|4@0+ (1,0) [0|15] "" Vector__XXX
 SG_ ACC_FRadarFailureStatus : 53|2@0+ (1,0) [0|3] "" Vector__XXX
 SG_ ACC_AEBTargetLatRange : 21|10@0+ (0.1,-50) [-50|50] "m" Vector__XXX
 SG_ ACC_AEBTargetRelSpeed : 14|9@0+ (1,-250) [-250|250] "km/h" Vector__XXX
 SG_ ACC_AEBTargetLngRange : 7|9@0+ (0.5,-70) [-70|180] "m" Vector__XXX
 SG_ ACC_Voiceinfo : 47|5@0+ (1,0) [0|31] "" Vector__XXX
 SG_ ACC_AEBTargetmode : 33|2@0+ (1,0) [0|3] "" Vector__XXX
 SG_ ACC_AEBTextInfo : 37|4@0+ (1,0) [0|15] "" Vector__XXX
 SG_ ACC_AEBStatus : 39|2@0+ (1,0) [0|3] "" Vector__XXX

BO_ 879 FC_36F: 64 FC
 SG_ ACC_RollingCounter_36F : 491|4@0+ (1,0) [0|15] "" Vector__XXX
 SG_ ACC_CRCCheck_36F : 503|16@0+ (1,0) [0|65535] "" Vector__XXX
 SG_ ADS_PathShow_Sts : 292|3@0+ (1,0) [0|7] "" Vector__XXX
 SG_ ADS_NDAFenceTerminalDis : 289|10@0+ (10,0) [0|3000] "m" Vector__XXX
 SG_ ADS_NDATextInfo : 286|5@0+ (1,0) [0|31] "" Vector__XXX
 SG_ ADS_NDAStatus : 311|4@0+ (1,0) [0|15] "" Vector__XXX
 SG_ ACC_CRCCheck_3CD : 319|8@0+ (1,0) [0|255] "" Vector__XXX
 SG_ ACC_RollingCounter_3CD : 307|4@0+ (1,0) [0|15] "" Vector__XXX
 SG_ ACC_CRCCheck_3CB : 255|8@0+ (1,0) [0|255] "" Vector__XXX
 SG_ ACC_RollingCounter_3CB : 243|4@0+ (1,0) [0|15] "" Vector__XXX
 SG_ ACC_CRCCheck_3CA : 191|8@0+ (1,0) [0|255] "" Vector__XXX
 SG_ ACC_RollingCounter_3CA : 179|4@0+ (1,0) [0|15] "" Vector__XXX
 SG_ ACC_CRCCheck_3C8 : 127|8@0+ (1,0) [0|255] "" Vector__XXX
 SG_ ACC_RollingCounter_3C8 : 115|4@0+ (1,0) [0|15] "" Vector__XXX
 SG_ ACC_CRCCheck_374 : 63|8@0+ (1,0) [0|255] "" Vector__XXX
 SG_ ACC_RollingCounter_374 : 51|4@0+ (1,0) [0|15] "" Vector__XXX
 SG_ ADS_TunnelStatus : 265|2@0+ (1,0) [0|3] "" Vector__XXX
 SG_ ADS_TunnelDis : 279|9@0+ (1,0) [0|400] "m" Vector__XXX
 SG_ ADS_RampStatus : 268|3@0+ (1,0) [0|3] "" Vector__XXX
 SG_ ADS_PathThroughRamp : 270|2@0+ (1,0) [0|3] "" Vector__XXX
 SG_ ADS_RampSide : 246|2@0+ (1,0) [0|3] "" Vector__XXX
 SG_ ADS_DisToRamp : 263|9@0+ (1,0) [0|400] "m" Vector__XXX
 SG_ ADS_PathShowLngRange : 238|8@0+ (1,0) [0|200] "m" Vector__XXX
 SG_ ADS_RoadMergeLatRange : 218|12@0+ (0.01,-16) [-16|16] "m" Vector__XXX
 SG_ ADS_EOMNotice : 223|5@0+ (1,0) [0|31] "" Vector__XXX
 SG_ ADS_SeatPostureRectifyReq : 212|3@0+ (1,0) [0|7] "" Vector__XXX
 SG_ ADS_PromptCountDown : 205|7@0+ (1,0) [0|100] "s" Vector__XXX
 SG_ ADS_EOMDwgradingnotice : 192|3@0+ (1,0) [0|7] "" Vector__XXX
 SG_ ADS_AutoDriveStateDisplay : 196|4@0+ (1,0) [0|15] "" Vector__XXX
 SG_ ADS_PathShow_Status : 183|3@0+ (1,0) [0|7] "" Vector__XXX
 SG_ ADS_PathShow_C3 : 163|12@0+ (4.768E-007,-0.0009760857) [-0.0009760857|0.0009760857] "" Vector__XXX
 SG_ ADS_PathShow_C2 : 159|12@0+ (1.52588E-005,-0.0312347412) [-0.0312347412|0.0312347412] "" Vector__XXX
 SG_ ADS_PathShow_C1 : 139|12@0+ (0.0004882813,-1) [-1|0.9990234375] "" Vector__XXX
 SG_ ADS_RoadSlopeFlag : 72|1@0+ (1,0) [0|1] "-" Vector__XXX
 SG_ ADS_RoadSlopeShapeC3 : 135|12@0+ (4.768E-007,-0.0009760857) [-0.0009760857|0.0009760857] "" Vector__XXX
 SG_ ADS_RoadSlopeShapeC2 : 99|12@0+ (1.52588E-005,-0.0312347412) [-0.0312347412|0.0312347412] "" Vector__XXX
 SG_ ADS_RoadSlopeShapeC1 : 95|12@0+ (0.0004882813,-1) [-1|0.9990234375] "rad" Vector__XXX
 SG_ ADS_RoadMergeFlag : 73|1@0+ (1,0) [0|1] "-" Vector__XXX
 SG_ ADS_RoadLngRange : 87|8@0+ (1,0) [0|255] "m" Vector__XXX
 SG_ ADS_RemoteRoadShapeC3 : 69|12@0+ (4.768E-007,-0.0009760857) [-0.0009760857|0.0009760857] "" Vector__XXX
 SG_ ADS_RemoteRoadShapeC2 : 32|12@0+ (1.52588E-005,-0.0312347412) [-0.0312347412|0.0312347412] "" Vector__XXX
 SG_ ADS_RemoteRoadShapeC1 : 28|12@0+ (0.0004882813,-1) [-1|0.9990234375] "rad" Vector__XXX
 SG_ ACC_TakeoverReqAtIPFail : 71|2@0+ (1,0) [0|3] "" Vector__XXX
 SG_ ADS_TSRHostNextSpdLimitDist : 23|9@0+ (1,0) [0|400] "" Vector__XXX
 SG_ ADS_TSRHostNextSpdLimit : 15|8@0+ (1,0) [0|255] "" Vector__XXX
 SG_ ADS_RightPedWarnLevel : 30|2@0+ (1,0) [0|7] "" Vector__XXX
 SG_ ADS_RightPedDetection : 1|2@0+ (1,0) [0|3] "" Vector__XXX
 SG_ ADS_LeftPedWarnLevel : 3|2@0+ (1,0) [0|7] "" Vector__XXX
 SG_ ADS_LeftPedDetection : 5|2@0+ (1,0) [0|3] "" Vector__XXX
 SG_ ADS_HostPedWarnLevel_1 : 7|2@0+ (1,0) [0|7] "" Vector__XXX

BO_ 922 FC_39A: 64 FC
 SG_ LAS_TSRSpeedLimitType : 7|2@0+ (1,0) [0|3] "" Vector__XXX
 SG_ ACC_RollingCounter_39A : 491|4@0+ (1,0) [0|15] "" Vector__XXX
 SG_ ACC_CRCCheck_39A : 503|16@0+ (1,0) [0|65535] "" Vector__XXX
 SG_ LAS_TSRRightLaneStatus : 55|3@0+ (1,0) [0|7] "" Vector__XXX
 SG_ LAS_TSRLeftLaneStatus : 47|3@0+ (1,0) [0|7] "" Vector__XXX
 SG_ LAS_CRCCheck_3C0 : 191|8@0+ (1,0) [0|255] "" Vector__XXX
 SG_ LAS_RollingCounter_3C0 : 179|4@0+ (1,0) [0|15] "" Vector__XXX
 SG_ LAS_TSRRightLaneSpdLimit : 143|8@0+ (1,0) [0|255] "" Vector__XXX
 SG_ LAS_TSRLeftLaneSpdLimit : 135|8@0+ (1,0) [0|255] "" Vector__XXX
 SG_ LAS_CRCCheck_3D4 : 127|8@0+ (1,0) [0|255] "" Vector__XXX
 SG_ LAS_RollingCounter_3D4 : 115|4@0+ (1,0) [0|15] "" Vector__XXX
 SG_ LAS_TLAStopLine_HostLane : 111|8@0+ (1,0) [0|255] "" Vector__XXX
 SG_ LAS_TLADistance_HostLane : 103|8@0+ (1,0) [0|255] "" Vector__XXX
 SG_ LAS_TLACountDownTime_HostLane : 94|7@0+ (1,0) [0|127] "" Vector__XXX
 SG_ LAS_TSRMandatorySign : 70|4@0+ (1,0) [0|15] "" Vector__XXX
 SG_ LAS_TSRWarningSign : 83|4@0+ (1,0) [0|15] "" Vector__XXX
 SG_ LAS_TSRProhibitionSign : 66|5@0+ (1,0) [0|31] "" Vector__XXX
 SG_ LAS_CRCCheck_332 : 63|8@0+ (1,0) [0|255] "" Vector__XXX
 SG_ LAS_RollingCounter_332 : 51|4@0+ (1,0) [0|15] "" Vector__XXX
 SG_ LAS_OverspeedSoundWarningEnSt : 27|1@0+ (1,0) [0|1] "" Vector__XXX
 SG_ LAS_TSREnable : 30|1@0+ (1,0) [0|1] "" Vector__XXX
 SG_ LAS_HMAEnableStatus : 22|1@0+ (1,0) [0|1] "" Vector__XXX
 SG_ LAS_HMALightDistribution : 8|1@0+ (1,0) [0|1] "" Vector__XXX
 SG_ LAS_HMAStatus : 44|2@0+ (1,0) [0|3] "" Vector__XXX
 SG_ LAS_TSRHostSpdLimitUnits : 41|2@0+ (1,0) [0|3] "" Vector__XXX
 SG_ LAS_TSRHostSpdLimit : 39|8@0+ (1,0) [0|255] "" Vector__XXX
 SG_ LAS_TSRStatus : 26|3@0+ (1,0) [0|7] "" Vector__XXX
 SG_ LAS_FrontCameraCalibrationStatus : 20|2@0+ (1,0) [0|3] "" Vector__XXX
 SG_ LAS_FrontCameraFailureStatus : 17|2@0+ (1,0) [0|3] "" Vector__XXX
 SG_ LAS_OverspeedWarningOffset : 14|5@0+ (1,-10) [-10|10] "km/h" Vector__XXX
 SG_ LAS_OverspeedWarningEnableStatus : 15|1@0+ (1,0) [0|1] "" Vector__XXX
 SG_ LAS_OverspeedSoundWarning : 2|1@0+ (1,0) [0|1] "" Vector__XXX
 SG_ LAS_OverspeedVisualWarning : 5|1@0+ (1,0) [0|1] "" Vector__XXX
 SG_ LAS_RoadSignCenterLatRange_Rlane : 306|9@0+ (0.05,-8) [-8|17.55] "m" Vector__XXX
 SG_ LAS_RoadSignCenterLngRange_RLane : 299|9@0+ (0.1,0) [0|51.1] "m" Vector__XXX
 SG_ LAS_RoadSignCenterLatRange_LLane : 292|9@0+ (0.05,-8) [-8|17.55] "m" Vector__XXX
 SG_ LAS_RoadSignCenterLngRange_LLane : 285|9@0+ (0.1,0) [0|51.1] "m" Vector__XXX
 SG_ LAS_RoadSignCenterLatRange_HLane : 278|9@0+ (0.05,-8) [-8|17.55] "m" Vector__XXX
 SG_ LAS_RoadSignCenterLngRange_HLane : 271|9@0+ (0.1,0) [0|51.1] "m" Vector__XXX
 SG_ LAS_CrosswalkLngRange_HLane : 263|8@0+ (1,0) [0|255] "" Vector__XXX
 SG_ LAS_RoadSignType_RLane : 157|5@0+ (1,0) [0|15] "" Vector__XXX
 SG_ LAS_RoadSignType_LLane : 146|5@0+ (1,0) [0|15] "" Vector__XXX
 SG_ LAS_RoadSignType_HLane : 151|5@0+ (1,0) [0|15] "" Vector__XXX
 SG_ LAS_CRCCheck_37D : 255|8@0+ (1,0) [0|255] "" Vector__XXX
 SG_ LAS_RollingCounter_37D : 243|4@0+ (1,0) [0|15] "" Vector__XXX
 SG_ LAS_TLAArrowDirection_RightLane : 236|3@0+ (1,0) [0|7] "" Vector__XXX
 SG_ LAS_TLAObjectType_RightLane : 239|3@0+ (1,0) [0|7] "" Vector__XXX
 SG_ LAS_TLAObjectStatus_RightLane : 247|2@0+ (1,0) [0|3] "" Vector__XXX
 SG_ LAS_TLAObjectColour_RightLane : 225|2@0+ (1,0) [0|3] "" Vector__XXX
 SG_ LAS_TLAObjectDetection_RightLane : 227|1@0+ (1,0) [0|1] "" Vector__XXX
 SG_ LAS_TLAArrowDirection_LeftLane : 216|3@0+ (1,0) [0|7] "" Vector__XXX
 SG_ LAS_TLAObjectType_LeftLane : 219|3@0+ (1,0) [0|7] "" Vector__XXX
 SG_ LAS_TLAObjectStatus_LeftLane : 245|2@0+ (1,0) [0|3] "" Vector__XXX
 SG_ LAS_TLAObjectColour_LeftLane : 221|2@0+ (1,0) [0|3] "" Vector__XXX
 SG_ LAS_TLAObjectDetection_LeftLane : 223|1@0+ (1,0) [0|1] "" Vector__XXX
 SG_ LAS_TLAArrowDirection_HostLane : 215|3@0+ (1,0) [0|7] "" Vector__XXX
 SG_ LAS_TLAObjectStatus_HostLane : 199|2@0+ (1,0) [0|3] "" Vector__XXX
 SG_ LAS_TLAObjectType_HostLane : 212|3@0+ (1,0) [0|7] "" Vector__XXX
 SG_ LAS_TLAObjectColour_HostLane : 204|2@0+ (1,0) [0|3] "" Vector__XXX
 SG_ LAS_TLAObjectDetection_HostLane : 200|1@0+ (1,0) [0|1] "" Vector__XXX
 SG_ LAS_TLAWarninglevel : 197|2@0+ (1,0) [0|3] "" Vector__XXX
 SG_ LAS_TLAStatus : 193|2@0+ (1,0) [0|3] "" Vector__XXX
 SG_ LAS_TLAEnable : 194|1@0+ (1,0) [0|1] "" Vector__XXX

BO_ 853 GW_355: 8 Vector__XXX
 SG_ EMS_CRCCheck_355 : 63|8@0+ (1,0) [0|255] ""  FC
 SG_ EMS_RollingCounter_355 : 51|4@0+ (1,0) [0|15] ""  FC
 SG_ EMS_CruiseDistance : 10|1@0+ (1,0) [0|1] ""  FC
 SG_ EMS_CruiseSwitchSET : 11|1@0+ (1,0) [0|1] ""  FC
 SG_ EMS_CruiseSwitchCANCEL : 12|1@0+ (1,0) [0|1] ""  FC
 SG_ EMS_CruiseSwitchResume : 13|1@0+ (1,0) [0|1] ""  FC
 SG_ EMS_CruiseSwitchOnOff : 14|1@0+ (1,0) [0|1] ""  FC

BO_ 941 APA_3AD: 8 Vector__XXX
 SG_ DVR_SdcardErrorStatus : 7|3@0+ (1,0) [0|7] ""  FC

BO_ 943 GW_3AF: 64 Vector__XXX
 SG_ HU_LaneConfluenceDis : 155|6@0+ (10,0) [0|600] "m"  FC
 SG_ HU_LaneConfluence : 157|2@0+ (1,0) [0|3] ""  FC
 SG_ HU_CRCCheck_3AF : 255|8@0+ (1,0) [0|255] ""  FC
 SG_ HU_RollingCounter_3AF : 243|4@0+ (1,0) [0|15] ""  FC
 SG_ HU_RampDistance : 239|10@0+ (10,0) [0|3000] "m"  FC
 SG_ HU_NavSpeedLimitType : 231|2@0+ (1,0) [0|3] ""  FC
 SG_ HU_CurveDistance : 229|6@0+ (10,0) [0|600] "m"  FC
 SG_ HU_EnterCurveInfo : 220|2@0+ (1,0) [0|3] ""  FC
 SG_ HU_NavCurrentRoadType : 218|3@0+ (1,0) [0|7] ""  FC
 SG_ HU_EnterRampInfo : 215|2@0+ (1,0) [0|3] ""  FC
 SG_ HU_RampInfo : 209|2@0+ (1,0) [0|3] ""  FC
 SG_ HU_NavCountryCode : 199|8@0+ (1,0) [0|255] ""  FC
 SG_ HU_NavStatus : 223|1@0+ (1,0) [0|1] ""  FC
 SG_ HU_NavSpeedLimitUnits : 213|2@0+ (1,0) [0|3] ""  FC
 SG_ HU_NavSpeedLimitStatus : 211|2@0+ (1,0) [0|3] ""  FC
 SG_ HU_NavSpeedLimit : 207|8@0+ (1,0) [0|255] ""  FC
 SG_ HU_CRCCheck_3BB : 319|8@0+ (1,0) [0|255] ""  FC
 SG_ HU_RollingCounter_3BB : 307|4@0+ (1,0) [0|15] ""  FC
 SG_ HU_SlopeGradientFar : 281|10@0+ (0.1,-51.1) [-51.1|51.1] "%"  FC
 SG_ HU_SlopeGradient : 265|10@0+ (0.1,-51.1) [-51.1|51.1] "%"  FC
 SG_ HU_SpeedLimitDistance : 261|6@0+ (10,0) [0|600] "m"  FC

BO_ 957 GW_3BD: 64 Vector__XXX
 SG_ HU_CSLAEnable : 7|2@0+ (1,0) [0|3] ""  FC
 SG_ HU_ELKEnable : 1|2@0+ (1,0) [0|3] ""  FC
 SG_ HU_TLAEnable : 9|2@0+ (1,0) [0|3] ""  FC

BO_ 964 GW_3C4: 64 Vector__XXX
 SG_ HU_CRCCheck_3C7 : 319|8@0+ (1,0) [0|255] ""  FC
 SG_ HU_RollingCounter_3C7 : 307|4@0+ (1,0) [0|15] ""  FC
 SG_ HU_CRCCheck_3C6 : 255|8@0+ (1,0) [0|255] ""  FC
 SG_ HU_RollingCounter_3C6 : 243|4@0+ (1,0) [0|15] ""  FC
 SG_ HU_CRCCheck_3C4 : 191|8@0+ (1,0) [0|255] ""  FC
 SG_ HU_RollingCounter_3C4 : 179|4@0+ (1,0) [0|15] ""  FC
 SG_ HU_CRCCheck_3C2 : 127|8@0+ (1,0) [0|255] ""  FC
 SG_ HU_RollingCounter_3C2 : 115|4@0+ (1,0) [0|15] ""  FC
 SG_ HU_MapMatchStatus : 309|2@0+ (1,0) [0|3] ""  FC
 SG_ HU_MapDataUpdateStatus : 118|3@0+ (1,0) [0|7] ""  FC
 SG_ HU_SlopeGradient_300m : 303|10@0+ (0.1,-51.1) [-51.1|51.1] "%"  FC
 SG_ HU_RoadCurvature_600m : 281|10@0+ (1,0) [0|1023] "1/m"  FC
 SG_ HU_RoadCurvature_400m : 275|10@0+ (1,0) [0|1023] "1/m"  FC
 SG_ HU_RoadCurvature_300m : 269|10@0+ (1,0) [0|1023] "1/m"  FC
 SG_ HU_RoadCurvature_100m : 263|10@0+ (1,0) [0|1023] "1/m"  FC
 SG_ HU_RoadCurvature_90m : 239|10@0+ (1,0) [0|1023] "1/m"  FC
 SG_ HU_RoadCurvature_80m : 217|10@0+ (1,0) [0|1023] "1/m"  FC
 SG_ HU_RoadCurvature_70m : 211|10@0+ (1,0) [0|1023] "1/m"  FC
 SG_ HU_RoadCurvature_60m : 205|10@0+ (1,0) [0|1023] "1/m"  FC
 SG_ HU_RoadCurvature_50m : 199|10@0+ (1,0) [0|1023] "1/m"  FC
 SG_ HU_RoadCurvature_40m : 161|10@0+ (1,0) [0|1023] "1/m"  FC
 SG_ HU_RoadCurvature_30m : 155|10@0+ (1,0) [0|1023] "1/m"  FC
 SG_ HU_RoadCurvature_20m : 149|10@0+ (1,0) [0|1023] "1/m"  FC
 SG_ HU_RoadCurvature_10m : 143|10@0+ (1,0) [0|1023] "1/m"  FC
 SG_ HU_Road_TrafficFlow : 105|3@0+ (1,0) [0|7] ""  FC
 SG_ HU_Lane_Changtype : 129|2@0+ (1,0) [0|3] ""  FC
 SG_ HU_To_NumchangeOfLanes_Dist : 135|6@0+ (10,0) [0|600] "m"  FC
 SG_ HU_To_Branch_Dis : 111|6@0+ (10,0) [0|600] "m"  FC
 SG_ HU_BranchInfo : 245|2@0+ (1,0) [0|3] ""  FC
 SG_ HU_To_TrafficAccident_Dis : 101|6@0+ (10,0) [0|600] "m"  FC
 SG_ HU_TrafficAccident_Info : 103|2@0+ (1,0) [0|3] ""  FC
 SG_ HU_To_Construction_Dis : 93|6@0+ (10,0) [0|600] "m"  FC
 SG_ HU_Construction_Info : 95|2@0+ (1,0) [0|3] ""  FC
 SG_ HU_TollDis : 85|6@0+ (10,0) [0|600] "m"  FC
 SG_ HU_TollInfo : 87|2@0+ (1,0) [0|3] ""  FC
 SG_ HU_FallingRockDi : 77|6@0+ (10,0) [0|600] "m"  FC
 SG_ HU_FallingRockInfo : 79|2@0+ (1,0) [0|3] ""  FC
 SG_ HU_LaneCnt : 66|3@0+ (1,0) [0|7] ""  FC
 SG_ HU_ForwardRoadType : 69|3@0+ (1,0) [0|7] ""  FC
 SG_ HU_RampSide : 71|2@0+ (1,0) [0|3] ""  FC
 SG_ HU_CRCCheck_3B8 : 63|8@0+ (1,0) [0|255] ""  FC
 SG_ HU_RollingCounter_3B8 : 51|4@0+ (1,0) [0|15] ""  FC
 SG_ HU_NavGuiganceStatus : 47|2@0+ (1,0) [0|3] ""  FC
 SG_ HU_SlopeDistance : 45|6@0+ (10,0) [0|600] "m"  FC
 SG_ HU_Byroad : 39|2@0+ (1,0) [0|3] ""  FC
 SG_ HU_TunnelLength : 37|6@0+ (1,0) [0|63] "m"  FC
 SG_ HU_RoadCurvatureFar : 17|10@0+ (1,0) [0|1023] ""  FC
 SG_ HU_TunnelDistance : 23|6@0+ (10,0) [0|600] "m"  FC
 SG_ HU_RoadCurvature : 1|10@0+ (1,0) [0|1023] ""  FC
 SG_ HU_EnterSlopeInfo : 5|2@0+ (1,0) [0|3] ""  FC
 SG_ HU_EnterTunnelInfo : 3|2@0+ (1,0) [0|3] ""  FC

CM_ BO_ 368 " ";
CM_ SG_ 368 EPS_fault_state " ";
CM_ SG_ 368 EPS_CRCCheck_170 "平台为10ms，CD569特例为8ms ";
CM_ SG_ 368 EPS_RollingCounter_170 "平台为10ms，CD569特例为8ms ";
CM_ SG_ 368 EPS_ActualTorsionBarTorq "平台为10ms，CD569特例为8ms ";
CM_ SG_ 368 EPS_MinSafetyTorsionBarTorq "平台为10ms，CD569特例为8ms ";
CM_ SG_ 368 EPS_MaxSafetyTorsionBarTorq "平台为10ms，CD569特例为8ms ";
CM_ BO_ 392 " ";
CM_ SG_ 392 TCU_ShiftinProgressValid "AT/DCT ";
CM_ SG_ 392 TCU_ShiftinProgress "AT/DCT ";
CM_ SG_ 392 TCU_CRCCheck_188 " ";
CM_ SG_ 392 TCU_RollingCounter_188 "AT/DCT
rollingcounter ";
CM_ BO_ 580 " ";
CM_ SG_ 580 ACC_RWU_Parking_Request_Valid " ";
CM_ SG_ 580 ACC_RWU_Parking_Request " ";
CM_ SG_ 580 ACC_CDP_Parking_Request_Valid " ";
CM_ SG_ 580 ACC_CDP_Parking_Request " ";
CM_ SG_ 580 ADS_Authernticator_244 " ";
CM_ SG_ 580 ADS_ResetFlag_244 " ";
CM_ SG_ 580 ADS_MesssageCounter_244 " ";
CM_ SG_ 580 ACC_AEBCtrlType " ";
CM_ SG_ 580 ACC_EmergencyDataRrdReq " ";
CM_ SG_ 580 ACC_CRCCheck_24E " ";
CM_ SG_ 580 ACC_RollingCounter_24E "rolling counter ";
CM_ SG_ 580 ACC_EngineStartStopRequest "0x1: EngineAutoStopRequest (请求发动机进入STOP状态)；
0x2:EngineAutoStartRequest(请求发动机进入到START状态)； ";
CM_ SG_ 580 ACC_LKAStatus "GW报文转发 ";
CM_ SG_ 580 ACC_LDWVibrationWarningReq "有ACC、LAS时由ACC发送，其余由APA或AVM发送 ";
CM_ SG_ 580 ACC_LDWStatus "有ACC、LAS时由ACC发送，其余由APA或AVM发送 ";
CM_ SG_ 580 ACC_ACCTargetAcceleration "ACC target acceleration for transmission. ";
CM_ BO_ 583 " ";
CM_ BO_ 664 " ";
CM_ BO_ 775 " ";
CM_ SG_ 775 ACC_Line_RR_Id "同一条车线未打断车线ID不变，一定距离内车线ID不重复 ";
CM_ SG_ 775 ACC_Line_R_Id "同一条车线未打断车线ID不变，一定距离内车线ID不重复 ";
CM_ SG_ 775 ACC_Line_LL_Id "同一条车线未打断车线ID不变，一定距离内车线ID不重复 ";
CM_ SG_ 775 ACC_Line_L_Id "同一条车线未打断车线ID不变，一定距离内车线ID不重复 ";
CM_ SG_ 775 ADS_IRLCEnable " ";
CM_ SG_ 775 ADS_AutoDriveState "IACC配置车型无此信号 ";
CM_ SG_ 775 ACC_CRCCheck_35F " ";
CM_ SG_ 775 ACC_RollingCounter_35F "rolling counter ";
CM_ SG_ 775 ACC_CSLAEnableStatus " ";
CM_ SG_ 775 ACC_HostPotentialTargetDirection " ";
CM_ SG_ 775 ACC_HostPotentialTargetLngRange "负数代表向后，正数代表向前，原点为前雷达波束发射面 ";
CM_ SG_ 775 ACC_CRCCheck_344 " ";
CM_ SG_ 775 ACC_RollingCounter_344 "rolling counter ";
CM_ SG_ 775 ACC_FLTarget2LngRange "负数代表向后，正数代表向前，原点为前雷达波束发射面 ";
CM_ SG_ 775 ACC_FLTarget2Direction " ";
CM_ SG_ 775 ACC_FLTarget1Direction " ";
CM_ SG_ 775 ACC_FLTarget1LngRange "负数代表向后，正数代表向前，原点为前雷达波束发射面 ";
CM_ SG_ 775 ACC_CRCCheck_322 " ";
CM_ SG_ 775 ACC_RollingCounter_322 "rolling counter ";
CM_ SG_ 775 ACC_ACCTargetDirection " ";
CM_ SG_ 775 ACC_ACCTargetLatRange " ";
CM_ SG_ 775 ACC_ACCTargetRelSpd " ";
CM_ SG_ 775 ACC_ACCTargetLngRange "负数代表向后，正数代表向前，原点为前雷达波束发射面 ";
CM_ SG_ 775 ACC_SaftyBeltVibrationReq " ";
CM_ SG_ 775 ACC_SaftyBelt_Tightened " ";
CM_ BO_ 786 " ";
CM_ SG_ 786 ACC_Selflearning_status " ";
CM_ SG_ 786 ACC_Selflearning_angle " ";
CM_ SG_ 786 ADS_ADSRoadVoiceEnableSts " ";
CM_ SG_ 786 ADS_ADSLaneChangeVoiceEnableSts " ";
CM_ SG_ 786 ADS_ADSSafeVoiceEnableSts " ";
CM_ SG_ 786 ADS_NDANavEnableStatus " ";
CM_ SG_ 786 ADS_NDAAudioWarEnableStatus " ";
CM_ SG_ 786 ADS_NDAEnableStatus " ";
CM_ SG_ 786 ADS_ALCDirection " ";
CM_ SG_ 786 ADS_ALCTextInfoForDriver " ";
CM_ SG_ 786 ADS_LaneChangeStyle " ";
CM_ SG_ 786 ADS_UDLCVoiceRecStatus " ";
CM_ SG_ 786 ADS_EOMStatus " ";
CM_ SG_ 786 ADS_EOMSeatSteeringAdjustReq " ";
CM_ SG_ 786 ADS_EOMDriverHeadPos " ";
CM_ SG_ 786 ADS_EOMActiveReq " ";
CM_ SG_ 786 ADS_SpdLimitedStatus "IACC配置车型无此信号 ";
CM_ SG_ 786 ADS_CRCCheck_3D7 " ";
CM_ SG_ 786 ADS_RollingCounter_3D7 "rolling counter ";
CM_ SG_ 786 ACC_SunroofControl " ";
CM_ SG_ 786 ACC_RightRearWindowControl " ";
CM_ SG_ 786 ACC_LeftRearWindowControl " ";
CM_ SG_ 786 ACC_PassengerWindowControl " ";
CM_ SG_ 786 ACC_DriverWindowControl " ";
CM_ SG_ 786 ADS_AutoWiperShift_Rqe " ";
CM_ SG_ 786 ACC_HornCommand " ";
CM_ SG_ 786 ADS_AutoHeadlightshift_Req " ";
CM_ SG_ 786 ADS_HighBeamLampOnRequest " ";
CM_ SG_ 786 ADS_LowBeamLampOnRequest " ";
CM_ SG_ 786 ADS_LightFrequencyRequest " ";
CM_ SG_ 786 ADS_LightBrightRequest " ";
CM_ SG_ 786 ADS_LightFlashRequest " ";
CM_ SG_ 786 ADS_LightColorRequest " ";
CM_ SG_ 786 ADS_LightingReq " ";
CM_ SG_ 786 ADS_ESSEnable " ";
CM_ SG_ 786 ADS_CRCCheck_358 " ";
CM_ SG_ 786 ADS_RollingCounter_358 "rolling counter ";
CM_ SG_ 786 ADS_RLaneColor " ";
CM_ SG_ 786 ADS_LLaneColor " ";
CM_ SG_ 786 ADS_UDLCTurnRightRequest " ";
CM_ SG_ 786 ADS_UDLCRightStatus " ";
CM_ SG_ 786 ADS_UDLCTurnLeftRequest " ";
CM_ SG_ 786 ADS_UDLCTurnLightReq " ";
CM_ SG_ 786 ADS_UDLCLeftStatus " ";
CM_ SG_ 786 ADS_UDLCStatus " ";
CM_ SG_ 786 ADS_UDLCEnableStatus " ";
CM_ SG_ 786 ADS_ESSMode " ";
CM_ SG_ 786 ADS_CRCCheck_342 " ";
CM_ SG_ 786 ADS_RollingCounter_342 "rolling counter ";
CM_ SG_ 786 ACC_CRCCheck_3E4 " ";
CM_ SG_ 786 ACC_RollingCounter_3E4 "rolling counter ";
CM_ BO_ 832 " ";
CM_ BO_ 839 " ";
CM_ SG_ 839 TPMS_RRPressureWarning "无效值是为转DBC ";
CM_ SG_ 839 TPMS_LRPressureWarning "无效值是为转DBC ";
CM_ SG_ 839 TPMS_LFPressureWarning "无效值是为转DBC ";
CM_ SG_ 839 TPMS_RFPressureWarning "无效值是为转DBC ";
CM_ BO_ 869 " ";
CM_ SG_ 869 IMS_HeadDetectSts_Yaw " ";
CM_ SG_ 869 IMS_HeadDetectSts_Roll " ";
CM_ SG_ 869 IMS_HeadDetectSts_Pitch " ";
CM_ SG_ 869 IMS_IMSStatus " ";
CM_ SG_ 869 IMS_EyeGazeStatus " ";
CM_ SG_ 869 IMS_EyeDetectSatus "10以下认为闭眼 ";
CM_ SG_ 869 IMS_DrowsinessStatus " ";
CM_ SG_ 869 IMS_DriverHeadDetect " ";
CM_ SG_ 869 IMS_DistractionStatus " ";
CM_ BO_ 870 " ";
CM_ BO_ 903 " ";
CM_ BO_ 912 " ";
CM_ SG_ 912 BCM_PMSLevel "无效值是为转DBC ";
CM_ BO_ 918 " ";
CM_ BO_ 1287 " ";
CM_ SG_ 1287 HU_NDAAudioWarEnable " ";
CM_ SG_ 1287 HU_FCWSetting " ";
CM_ SG_ 1287 HU_IACCEnable "513(周期)和514(事件)，当前多数项目使用514(事件)报文。 ";
CM_ SG_ 1287 HU_LDWShakeLev "513(周期)和514(事件)，当前多数项目使用514(事件)报文。 ";
CM_ SG_ 1287 HU_RCTAEnable "513(周期)和514(事件)，当前多数项目使用514(事件)报文。 ";
CM_ SG_ 1287 HU_HMAEnable "513(周期)和514(事件)，当前多数项目使用514(事件)报文。 ";
CM_ SG_ 1287 HU_TSRSwitch "513(周期)和514(事件)，当前多数项目使用514(事件)报文。 ";
CM_ SG_ 1287 HU_LASWarningModeSelection "513(周期)和514(事件)，当前多数项目使用514(事件)报文。 ";
CM_ SG_ 1287 HU_LASModeSelection "513(周期)和514(事件)，当前多数项目使用514(事件)报文。 ";
CM_ SG_ 1287 HU_OverspeedWarningOffset "513(周期)和514(事件)，当前多数项目使用514(事件)报文。 ";
CM_ SG_ 1287 HU_OverspeedWarningEnable "513(周期)和514(事件)，当前多数项目使用514(事件)报文。 ";
CM_ SG_ 1287 HU_OverspeedSoundWarEnable "513(周期)和514(事件)，当前多数项目使用514(事件)报文。 ";
CM_ BO_ 1302 " ";
CM_ BO_ 1352 " ";
CM_ SG_ 1352 ADS_EventTimeSecond " ";
CM_ SG_ 1352 ADS_EventTimeMinute " ";
CM_ SG_ 1352 ADS_EventTimeHour " ";
CM_ SG_ 1352 ADS_EventTimeDay " ";
CM_ SG_ 1352 ADS_EventTimeMonth " ";
CM_ SG_ 1352 ADS_EventTimeYear " ";
CM_ SG_ 1352 ADS_EventCode " ";
CM_ SG_ 1352 ADS_EventAmount " ";
CM_ SG_ 1352 ADS_EventStartEndIdentify " ";
CM_ SG_ 1352 ADS_EID " ";
CM_ SG_ 1352 ADS_ControllerCode " ";
CM_ BO_ 1554 " ";
CM_ SG_ 1554 DVR_EmergencyRecordStatus "GW报文转发
APA5.0的车型由SCAN转发 ";
CM_ SG_ 1554 DVR_Error "GW报文转发
APA5.0的车型由SCAN转发 ";
CM_ BO_ 382 " ";
CM_ SG_ 382 EPS_ADS_Abortfeedback "平台为10ms，CD569特例为8ms ";
CM_ SG_ 382 EPS_LatCtrlActive "平台为10ms，CD569特例为8ms ";
CM_ SG_ 382 EPS_LatCtrlAvailabilityStatus "平台为10ms，CD569特例为8ms ";
CM_ SG_ 382 EPS_CRCCheck_17E "平台为10ms，CD569特例为8ms ";
CM_ SG_ 382 EPS_RollingCounter_17E "1.rolling counter
2.平台为10ms，CD569特例为8ms ";
CM_ SG_ 382 EPS_MeasuredTorsionBarTorqValid "平台为10ms，CD569特例为8ms ";
CM_ SG_ 382 EPS_MeasuredTorsionBarTorque "平台为10ms，CD569特例为8ms ";
CM_ BO_ 398 " ";
CM_ SG_ 398 EMS_CRCCheck_1A6 "ACM接收为AT/DCT专用 ";
CM_ SG_ 398 EMS_RollingCounter_1A6 "ACM接收为AT/DCT专用 ";
CM_ SG_ 398 EMS_EngineStatus "ACM接收为AT/DCT专用 ";
CM_ SG_ 398 EMS_MinIndicatedTorq "TCU接收为DCT专用 ";
CM_ SG_ 398 EMS_MaxIndicatedTorq "TCU接收为DCT专用 ";
CM_ SG_ 398 EMS_RollingCounter_196 "ACM接收为AT专用 ";
CM_ SG_ 398 EMS_CRCCheck_196 "ACM接收为AT专用 ";
CM_ SG_ 398 EMS_AccPedal "ACM接收为AT专用 ";
CM_ SG_ 398 EMS_EngineFuelCutOff "TCU接收为DCT专用 ";
CM_ SG_ 398 EMS_BrakePedalStatus "表示驾驶员踩下制动踏板的真实状态
ACM接收为AT专用 ";
CM_ SG_ 398 EMS_CRCCheck_184 " ";
CM_ SG_ 398 EMS_IndicatedDriverReqTorq "TCU接收为AT/DCT专用 ";
CM_ BO_ 442 " ";
CM_ SG_ 442 ACC_LatAngReqActive " ";
CM_ SG_ 442 ACC_LatAngReq " ";
CM_ SG_ 442 ADS_Authernticator_1BA " ";
CM_ SG_ 442 ADS_ResetFlag_1BA " ";
CM_ SG_ 442 ADS_MesssageCounter_1BA " ";
CM_ SG_ 442 ACC_CRCCheck_1BA_0 " ";
CM_ SG_ 442 ACC_RollingCounter_1BA_0 "GW报文转发
rolling counter ";
CM_ SG_ 442 ADS_ESSActive " ";
CM_ SG_ 442 ACC_MotorTorqueMinLimitRequest " ";
CM_ SG_ 442 ACC_MotorTorqueMaxLimitRequest " ";
CM_ BO_ 588 " ";
CM_ SG_ 588 TCU_RollingCounter_24C "AT/DCT ";
CM_ BO_ 591 " ";
CM_ BO_ 618 " ";
CM_ SG_ 618 EMS_CRCCheck_26A "AT/DCT ";
CM_ SG_ 618 EMS_RollingCounter_26A "AT/DCT ";
CM_ SG_ 618 EMS_AccReqPossible "无相关配置时保留信号默认发0； ";
CM_ SG_ 618 EMS_QECACC "无相关配置时保留信号默认发0； ";
CM_ SG_ 618 EMS_ECGPOvrd "无相关配置时保留信号默认发0； ";
CM_ BO_ 651 " ";
CM_ BO_ 676 " ";
CM_ SG_ 676 LCDAR_RCTBStatus "IACC配置车型无此信号 ";
CM_ SG_ 676 LCDAR_CRCCheck_2AF " ";
CM_ SG_ 676 LCDAR_RollingCounter_2AF "rolling counter ";
CM_ SG_ 676 LCDAR_ELK_oAlert " ";
CM_ SG_ 676 LCDAR_ELK_oStatus " ";
CM_ SG_ 676 LCDAR_Left_ELK_oAlert " ";
CM_ SG_ 676 LCDAR_RCTBActive " ";
CM_ SG_ 676 LCDAR_RCTBTargetDecel " ";
CM_ SG_ 676 LCDAR_RCTBEnable " ";
CM_ BO_ 710 " ";
CM_ BO_ 721 " ";
CM_ BO_ 726 " ";
CM_ SG_ 726 EMS_CRCCheck_2D6 " ";
CM_ SG_ 726 EMS_EngineLimpHome "TCU接收为DCT专用 ";
CM_ BO_ 794 " ";
CM_ SG_ 794 ADS_IsInFence " ";
CM_ SG_ 794 ACC_CRCCheck_367 " ";
CM_ SG_ 794 ACC_RollingCounter_367 "rolling counter ";
CM_ SG_ 794 ACC_LatPathHeadingAngle " ";
CM_ SG_ 794 ACC_LatPathDY " ";
CM_ SG_ 794 ACC_ELKEnableStatus " ";
CM_ SG_ 794 ACC_ELKInterventionMode " ";
CM_ SG_ 794 ACC_ELKMode " ";
CM_ SG_ 794 ACC_HostPedLatRange_1 "0x0-0xFA=-25-25m；0xFB-0xFE=reserved; ";
CM_ SG_ 794 ACC_CRCCheck_30D " ";
CM_ SG_ 794 ACC_RollingCounter_30D "rolling counter ";
CM_ SG_ 794 ACC_DoorCtrlReq " ";
CM_ SG_ 794 ACC_EmergencyLightingRequest " ";
CM_ SG_ 794 ACC_HandsoffFuncTextinfo " ";
CM_ SG_ 794 ACC_HandsoffFuncStatus " ";
CM_ SG_ 794 ACC_CRCCheck_30A " ";
CM_ SG_ 794 ACC_RollingCounter_30A "rolling counter ";
CM_ SG_ 794 ACC_RoadCurvatureFar "向左为正，向右为负 ";
CM_ SG_ 794 ACC_RoadCurvatureNear "向左为正，向右为负 ";
CM_ SG_ 794 ACC_RLaneMarkerType "有ACC、LAS时由ACC发送，其余由APA或AVM发送 ";
CM_ SG_ 794 ACC_LLaneMarkerType "有ACC、LAS时由ACC发送，其余由APA或AVM发送 ";
CM_ SG_ 794 ACC_HostLaneRightStatus "有ACC、LAS时由ACC发送，其余由APA或AVM发送 ";
CM_ SG_ 794 ACC_HostLaneLeftStatus "有ACC、LAS时由ACC发送，其余由APA或AVM发送 ";
CM_ SG_ 794 ACC_CRCCheck_36D " ";
CM_ SG_ 794 ACC_RollingCounter_36D "rolling counter ";
CM_ SG_ 794 ACC_FRadarFailureStatus " ";
CM_ SG_ 794 ACC_AEBTargetLatRange " ";
CM_ SG_ 794 ACC_AEBTargetRelSpeed " ";
CM_ SG_ 794 ACC_AEBTargetLngRange "负数代表向后，正数代表向前，原点为前雷达波束发射面 ";
CM_ SG_ 794 ACC_Voiceinfo " ";
CM_ SG_ 794 ACC_AEBTargetmode " ";
CM_ SG_ 794 ACC_AEBTextInfo " ";
CM_ SG_ 794 ACC_AEBStatus " ";
CM_ BO_ 879 " ";
CM_ SG_ 879 ADS_PathShow_Sts " ";
CM_ SG_ 879 ADS_NDAFenceTerminalDis " ";
CM_ SG_ 879 ADS_NDATextInfo " ";
CM_ SG_ 879 ADS_NDAStatus " ";
CM_ SG_ 879 ACC_CRCCheck_3CD " ";
CM_ SG_ 879 ACC_RollingCounter_3CD "rolling counter ";
CM_ SG_ 879 ACC_CRCCheck_3CB " ";
CM_ SG_ 879 ACC_RollingCounter_3CB "rolling counter ";
CM_ SG_ 879 ACC_CRCCheck_3CA " ";
CM_ SG_ 879 ACC_RollingCounter_3CA "rolling counter ";
CM_ SG_ 879 ACC_CRCCheck_3C8 " ";
CM_ SG_ 879 ACC_RollingCounter_3C8 "rolling counter ";
CM_ SG_ 879 ACC_CRCCheck_374 "IACC配置车型无此信号 ";
CM_ SG_ 879 ACC_RollingCounter_374 "IACC配置车型无此信号 ";
CM_ SG_ 879 ADS_PathShowLngRange " ";
CM_ SG_ 879 ADS_RoadMergeLatRange " ";
CM_ SG_ 879 ADS_EOMNotice " ";
CM_ SG_ 879 ADS_PathShow_C3 "与ACC_LaneEquationC3定义一致 ";
CM_ SG_ 879 ADS_PathShow_C2 "与ACC_LaneEquationC2定义一致 ";
CM_ SG_ 879 ADS_PathShow_C1 "与ACC_LaneEquationC1定义一致 ";
CM_ SG_ 879 ADS_RoadSlopeFlag " ";
CM_ SG_ 879 ADS_RoadSlopeShapeC3 "与ACC_LaneEquationC3定义一致 ";
CM_ SG_ 879 ADS_RoadSlopeShapeC2 "与ACC_LaneEquationC2定义一致 ";
CM_ SG_ 879 ADS_RoadSlopeShapeC1 "与ACC_LaneEquationC1定义一致 ";
CM_ SG_ 879 ADS_RoadMergeFlag " ";
CM_ SG_ 879 ADS_RoadLngRange " ";
CM_ SG_ 879 ADS_RemoteRoadShapeC3 "与ACC_LaneEquationC3定义一致 ";
CM_ SG_ 879 ADS_RemoteRoadShapeC2 "与ACC_LaneEquationC2定义一致 ";
CM_ SG_ 879 ADS_RemoteRoadShapeC1 "与ACC_LaneEquationC1定义一致 ";
CM_ SG_ 879 ADS_RightPedWarnLevel "IACC配置车型无此信号 ";
CM_ SG_ 879 ADS_RightPedDetection "IACC配置车型无此信号 ";
CM_ SG_ 879 ADS_LeftPedWarnLevel "IACC配置车型无此信号 ";
CM_ SG_ 879 ADS_LeftPedDetection "IACC配置车型无此信号 ";
CM_ SG_ 879 ADS_HostPedWarnLevel_1 "IACC配置车型无此信号 ";
CM_ BO_ 922 " ";
CM_ SG_ 922 LAS_TSRRightLaneStatus "GW报文转发 ";
CM_ SG_ 922 LAS_TSRLeftLaneStatus "GW报文转发 ";
CM_ SG_ 922 LAS_CRCCheck_3C0 "
 ";
CM_ SG_ 922 LAS_RollingCounter_3C0 "rolling counter ";
CM_ SG_ 922 LAS_TSRRightLaneSpdLimit "GW报文转发
0x0=no speed limit detected;
0x1=SL5;
0x2=SL10;
…
0x32=SL160;
0x33~0x253= Reserved;
0x254=Unknown;
0x255=SLEND ";
CM_ SG_ 922 LAS_TSRLeftLaneSpdLimit "GW报文转发
0x0=no speed limit detected;
0x1=SL5;
0x2=SL10;
…
0x32=SL160;
0x33~0x253= Reserved;
0x254=Unknown;
0x255=SLEND ";
CM_ SG_ 922 LAS_CRCCheck_3D4 "
 ";
CM_ SG_ 922 LAS_RollingCounter_3D4 "rolling counter ";
CM_ SG_ 922 LAS_TLAStopLine_HostLane " ";
CM_ SG_ 922 LAS_TLADistance_HostLane " ";
CM_ SG_ 922 LAS_TLACountDownTime_HostLane " ";
CM_ SG_ 922 LAS_TSRMandatorySign " ";
CM_ SG_ 922 LAS_TSRWarningSign " ";
CM_ SG_ 922 LAS_TSRProhibitionSign " ";
CM_ SG_ 922 LAS_CRCCheck_332 "
 ";
CM_ SG_ 922 LAS_RollingCounter_332 "rolling counter ";
CM_ SG_ 922 LAS_HMALightDistribution "GW报文转发 ";
CM_ SG_ 922 LAS_HMAStatus "GW报文转发 ";
CM_ SG_ 922 LAS_TSRHostSpdLimitUnits "GW报文转发 ";
CM_ SG_ 922 LAS_TSRStatus "GW报文转发 ";
CM_ SG_ 922 LAS_FrontCameraCalibrationStatus "有LAS时由LAS发送，其余由APA或AVM发送 ";
CM_ SG_ 922 LAS_FrontCameraFailureStatus "有LAS时由LAS发送，其余由APA或AVM发送 ";
CM_ SG_ 922 LAS_CRCCheck_37D " ";
CM_ SG_ 922 LAS_RollingCounter_37D "rolling counter ";
CM_ SG_ 922 LAS_TLAArrowDirection_RightLane " ";
CM_ SG_ 922 LAS_TLAObjectType_RightLane " ";
CM_ SG_ 922 LAS_TLAObjectStatus_RightLane " ";
CM_ SG_ 922 LAS_TLAObjectColour_RightLane " ";
CM_ SG_ 922 LAS_TLAObjectDetection_RightLane " ";
CM_ SG_ 922 LAS_TLAArrowDirection_LeftLane " ";
CM_ SG_ 922 LAS_TLAObjectType_LeftLane " ";
CM_ SG_ 922 LAS_TLAObjectStatus_LeftLane " ";
CM_ SG_ 922 LAS_TLAObjectColour_LeftLane " ";
CM_ SG_ 922 LAS_TLAObjectDetection_LeftLane " ";
CM_ SG_ 922 LAS_TLAArrowDirection_HostLane " ";
CM_ SG_ 922 LAS_TLAObjectStatus_HostLane " ";
CM_ SG_ 922 LAS_TLAObjectType_HostLane " ";
CM_ SG_ 922 LAS_TLAObjectColour_HostLane " ";
CM_ SG_ 922 LAS_TLAObjectDetection_HostLane " ";
CM_ SG_ 922 LAS_TLAWarninglevel " ";
CM_ SG_ 922 LAS_TLAStatus " ";
CM_ SG_ 922 LAS_TLAEnable " ";
CM_ BO_ 853 " ";
CM_ SG_ 853 EMS_CRCCheck_355 " ";
CM_ SG_ 853 EMS_CruiseDistance "无相关配置时保留信号默认发0； ";
CM_ SG_ 853 EMS_CruiseSwitchSET "无相关配置时保留信号默认发0； ";
CM_ SG_ 853 EMS_CruiseSwitchCANCEL "无相关配置时保留信号默认发0； ";
CM_ SG_ 853 EMS_CruiseSwitchResume "无相关配置时保留信号默认发0； ";
CM_ SG_ 853 EMS_CruiseSwitchOnOff "无相关配置时保留信号默认发0 ";
CM_ BO_ 941 " ";
CM_ SG_ 941 DVR_SdcardErrorStatus "GW报文转发
有APA5.0的车型从ADASCAN转发 ";
CM_ BO_ 943 " ";
CM_ SG_ 943 HU_LaneConfluenceDis " ";
CM_ SG_ 943 HU_LaneConfluence " ";
CM_ BO_ 957 " ";
CM_ SG_ 957 HU_CSLAEnable " ";
CM_ SG_ 957 HU_ELKEnable " ";
CM_ SG_ 957 HU_TLAEnable " ";
CM_ BO_ 964 " ";
CM_ SG_ 964 HU_CRCCheck_3C7 " ";
CM_ SG_ 964 HU_RollingCounter_3C7 " ";
CM_ SG_ 964 HU_CRCCheck_3C6 " ";
CM_ SG_ 964 HU_RollingCounter_3C6 " ";
CM_ SG_ 964 HU_CRCCheck_3C4 " ";
CM_ SG_ 964 HU_RollingCounter_3C4 " ";
CM_ SG_ 964 HU_CRCCheck_3C2 " ";
CM_ SG_ 964 HU_RollingCounter_3C2 " ";
CM_ SG_ 964 HU_MapMatchStatus " ";
CM_ SG_ 964 HU_MapDataUpdateStatus " ";
CM_ SG_ 964 HU_SlopeGradient_300m " ";
CM_ SG_ 964 HU_RoadCurvature_600m " ";
CM_ SG_ 964 HU_RoadCurvature_400m " ";
CM_ SG_ 964 HU_RoadCurvature_300m " ";
CM_ SG_ 964 HU_RoadCurvature_100m " ";
CM_ SG_ 964 HU_RoadCurvature_90m " ";
CM_ SG_ 964 HU_RoadCurvature_80m " ";
CM_ SG_ 964 HU_RoadCurvature_70m " ";
CM_ SG_ 964 HU_RoadCurvature_60m " ";
CM_ SG_ 964 HU_RoadCurvature_50m " ";
CM_ SG_ 964 HU_RoadCurvature_40m " ";
CM_ SG_ 964 HU_RoadCurvature_30m " ";
CM_ SG_ 964 HU_RoadCurvature_20m " ";
CM_ SG_ 964 HU_RoadCurvature_10m " ";
CM_ SG_ 964 HU_Road_TrafficFlow " ";
CM_ SG_ 964 HU_Lane_Changtype " ";
CM_ SG_ 964 HU_To_NumchangeOfLanes_Dist " ";
CM_ SG_ 964 HU_To_Branch_Dis " ";
CM_ SG_ 964 HU_BranchInfo " ";
CM_ SG_ 964 HU_To_TrafficAccident_Dis " ";
CM_ SG_ 964 HU_TrafficAccident_Info " ";
CM_ SG_ 964 HU_To_Construction_Dis " ";
CM_ SG_ 964 HU_Construction_Info " ";
CM_ SG_ 964 HU_TollDis " ";
CM_ SG_ 964 HU_TollInfo " ";
CM_ SG_ 964 HU_FallingRockDi " ";
CM_ SG_ 964 HU_FallingRockInfo " ";
CM_ SG_ 964 HU_LaneCnt " ";
CM_ SG_ 964 HU_ForwardRoadType " ";
CM_ SG_ 964 HU_RampSide " ";
BA_DEF_  "BusType" STRING ;
BA_DEF_ SG_  "GenSigSendType" ENUM  "Cyclic","OnWrite","OnWriteWithRepetition","OnChange","OnChangeWithRepetition","IfActive","IfActiveWithRepetition","NoSigSendType","NotUsed","NotUsed","NotUsed","NotUsed","NotUsed";
BA_DEF_ SG_  "GenSigCycleTime" INT 0 0;
BA_DEF_ SG_  "GenSigInvalidValue" STRING ;
BA_DEF_ SG_  "GenSigStartValue" INT 0 0;
BA_DEF_ BO_  "VFrameFormat" ENUM  "StandardCAN","ExtendedCAN","reserved","reserved","reserved","reserved","reserved","reserved","reserved","reserved","reserved","reserved","reserved","reserved","StandardCAN_FD","ExtendedCAN_FD";
BA_DEF_ BO_  "CANFD_BRS" ENUM  "0","1";
BA_DEF_ BO_  "GenMsgCycleTime" INT 0 65535;
BA_DEF_ BO_  "GenMsgILSupport" ENUM  "No","Yes";
BA_DEF_ BO_  "GenMsgSendType" ENUM  "Cyclic","Event","NotUsed","NotUsed","NotUsed","Cyclic","NotUsed","IfActive","NoMsgSendType","NotUsed";
BA_DEF_ BU_  "ILUsed" ENUM  "No","Yes";
BA_DEF_ BU_  "NodeLayerModules" STRING ;
BA_DEF_DEF_  "BusType" "";
BA_DEF_DEF_  "GenSigSendType" "Cyclic";
BA_DEF_DEF_  "GenSigCycleTime" 0;
BA_DEF_DEF_  "GenSigInvalidValue" "/";
BA_DEF_DEF_  "GenSigStartValue" 0;
BA_DEF_DEF_  "VFrameFormat" "StandardCAN";
BA_DEF_DEF_  "CANFD_BRS" "1";
BA_DEF_DEF_  "GenMsgCycleTime" 0;
BA_DEF_DEF_  "GenMsgILSupport" "Yes";
BA_DEF_DEF_  "GenMsgSendType" "NoMsgSendType";
BA_DEF_DEF_  "ILUsed" "Yes";
BA_DEF_DEF_  "NodeLayerModules" "OSEKNM01.dll,CANoeILNLVector.dll";
BA_ "BusType" "CAN";
BA_ "GenMsgCycleTime" BO_ 368 10;
BA_ "GenMsgSendType" BO_ 368 0;
BA_ "VFrameFormat" BO_ 368 14;
BA_ "GenMsgCycleTime" BO_ 392 10;
BA_ "GenMsgSendType" BO_ 392 0;
BA_ "VFrameFormat" BO_ 392 14;
BA_ "GenMsgCycleTime" BO_ 580 20;
BA_ "GenMsgSendType" BO_ 580 0;
BA_ "VFrameFormat" BO_ 580 14;
BA_ "GenMsgCycleTime" BO_ 583 20;
BA_ "GenMsgSendType" BO_ 583 0;
BA_ "VFrameFormat" BO_ 583 14;
BA_ "GenMsgCycleTime" BO_ 664 40;
BA_ "GenMsgSendType" BO_ 664 0;
BA_ "VFrameFormat" BO_ 664 14;
BA_ "GenMsgCycleTime" BO_ 775 100;
BA_ "GenMsgSendType" BO_ 775 0;
BA_ "VFrameFormat" BO_ 775 14;
BA_ "GenMsgCycleTime" BO_ 786 100;
BA_ "GenMsgSendType" BO_ 786 0;
BA_ "VFrameFormat" BO_ 786 14;
BA_ "GenMsgCycleTime" BO_ 832 100;
BA_ "GenMsgSendType" BO_ 832 0;
BA_ "VFrameFormat" BO_ 832 14;
BA_ "GenMsgCycleTime" BO_ 839 500;
BA_ "GenMsgSendType" BO_ 839 0;
BA_ "VFrameFormat" BO_ 839 14;
BA_ "GenMsgCycleTime" BO_ 869 100;
BA_ "GenMsgSendType" BO_ 869 0;
BA_ "VFrameFormat" BO_ 869 14;
BA_ "GenMsgCycleTime" BO_ 870 100;
BA_ "GenMsgSendType" BO_ 870 0;
BA_ "VFrameFormat" BO_ 870 14;
BA_ "GenMsgCycleTime" BO_ 903 100;
BA_ "GenMsgSendType" BO_ 903 0;
BA_ "VFrameFormat" BO_ 903 14;
BA_ "GenMsgCycleTime" BO_ 912 500;
BA_ "GenMsgSendType" BO_ 912 0;
BA_ "VFrameFormat" BO_ 912 14;
BA_ "GenMsgCycleTime" BO_ 918 100;
BA_ "GenMsgSendType" BO_ 918 0;
BA_ "VFrameFormat" BO_ 918 14;
BA_ "GenMsgSendType" BO_ 1287 1;
BA_ "VFrameFormat" BO_ 1287 14;
BA_ "GenMsgCycleTime" BO_ 1302 1000;
BA_ "GenMsgSendType" BO_ 1302 0;
BA_ "VFrameFormat" BO_ 1302 14;
BA_ "GenMsgCycleTime" BO_ 1352 500;
BA_ "GenMsgSendType" BO_ 1352 0;
BA_ "VFrameFormat" BO_ 1352 14;
BA_ "GenMsgCycleTime" BO_ 1554 100;
BA_ "GenMsgSendType" BO_ 1554 0;
BA_ "VFrameFormat" BO_ 1554 14;
BA_ "GenMsgCycleTime" BO_ 382 10;
BA_ "GenMsgSendType" BO_ 382 0;
BA_ "VFrameFormat" BO_ 382 14;
BA_ "GenMsgCycleTime" BO_ 398 10;
BA_ "GenMsgSendType" BO_ 398 0;
BA_ "VFrameFormat" BO_ 398 14;
BA_ "GenMsgCycleTime" BO_ 442 10;
BA_ "GenMsgSendType" BO_ 442 0;
BA_ "VFrameFormat" BO_ 442 14;
BA_ "GenMsgCycleTime" BO_ 588 20;
BA_ "GenMsgSendType" BO_ 588 0;
BA_ "VFrameFormat" BO_ 588 14;
BA_ "GenMsgCycleTime" BO_ 591 20;
BA_ "GenMsgSendType" BO_ 591 0;
BA_ "VFrameFormat" BO_ 591 14;
BA_ "GenMsgCycleTime" BO_ 618 20;
BA_ "GenMsgSendType" BO_ 618 0;
BA_ "VFrameFormat" BO_ 618 14;
BA_ "GenMsgCycleTime" BO_ 651 40;
BA_ "GenMsgSendType" BO_ 651 0;
BA_ "VFrameFormat" BO_ 651 14;
BA_ "GenMsgCycleTime" BO_ 676 50;
BA_ "GenMsgSendType" BO_ 676 0;
BA_ "VFrameFormat" BO_ 676 14;
BA_ "GenMsgCycleTime" BO_ 710 40;
BA_ "GenMsgSendType" BO_ 710 0;
BA_ "VFrameFormat" BO_ 710 14;
BA_ "GenMsgCycleTime" BO_ 721 40;
BA_ "GenMsgSendType" BO_ 721 0;
BA_ "VFrameFormat" BO_ 721 14;
BA_ "GenMsgCycleTime" BO_ 726 50;
BA_ "GenMsgSendType" BO_ 726 0;
BA_ "VFrameFormat" BO_ 726 14;
BA_ "GenMsgCycleTime" BO_ 794 100;
BA_ "GenMsgSendType" BO_ 794 0;
BA_ "VFrameFormat" BO_ 794 14;
BA_ "GenMsgCycleTime" BO_ 879 100;
BA_ "GenMsgSendType" BO_ 879 0;
BA_ "VFrameFormat" BO_ 879 14;
BA_ "GenMsgCycleTime" BO_ 922 100;
BA_ "GenMsgSendType" BO_ 922 0;
BA_ "VFrameFormat" BO_ 922 14;
BA_ "GenMsgCycleTime" BO_ 853 100;
BA_ "GenMsgSendType" BO_ 853 0;
BA_ "VFrameFormat" BO_ 853 14;
BA_ "GenMsgCycleTime" BO_ 941 100;
BA_ "GenMsgSendType" BO_ 941 0;
BA_ "VFrameFormat" BO_ 941 14;
BA_ "GenMsgCycleTime" BO_ 943 100;
BA_ "GenMsgSendType" BO_ 943 0;
BA_ "VFrameFormat" BO_ 943 14;
BA_ "GenMsgCycleTime" BO_ 957 100;
BA_ "GenMsgSendType" BO_ 957 0;
BA_ "VFrameFormat" BO_ 957 14;
BA_ "GenMsgCycleTime" BO_ 964 100;
BA_ "GenMsgSendType" BO_ 964 0;
BA_ "VFrameFormat" BO_ 964 14;
BA_ "GenSigCycleTime" SG_ 368 EPS_fault_state 10;
BA_ "GenSigCycleTime" SG_ 368 EPS_CRCCheck_170 10;
BA_ "GenSigCycleTime" SG_ 368 EPS_RollingCounter_170 10;
BA_ "GenSigCycleTime" SG_ 368 EPS_ActualTorsionBarTorq 10;
BA_ "GenSigInvalidValue" SG_ 368 EPS_ActualTorsionBarTorq "2047";
BA_ "GenSigStartValue" SG_ 368 EPS_ActualTorsionBarTorq 1024;
BA_ "GenSigCycleTime" SG_ 368 EPS_MinSafetyTorsionBarTorq 10;
BA_ "GenSigInvalidValue" SG_ 368 EPS_MinSafetyTorsionBarTorq "2047";
BA_ "GenSigStartValue" SG_ 368 EPS_MinSafetyTorsionBarTorq 1024;
BA_ "GenSigCycleTime" SG_ 368 EPS_MaxSafetyTorsionBarTorq 10;
BA_ "GenSigInvalidValue" SG_ 368 EPS_MaxSafetyTorsionBarTorq "2047";
BA_ "GenSigStartValue" SG_ 368 EPS_MaxSafetyTorsionBarTorq 1024;
BA_ "GenSigCycleTime" SG_ 392 TCU_ShiftinProgressValid 10;
BA_ "GenSigInvalidValue" SG_ 392 TCU_ShiftinProgressValid "1";
BA_ "GenSigCycleTime" SG_ 392 TCU_ShiftinProgress 10;
BA_ "GenSigCycleTime" SG_ 392 TCU_CRCCheck_188 10;
BA_ "GenSigCycleTime" SG_ 392 TCU_RollingCounter_188 10;
BA_ "GenSigCycleTime" SG_ 580 ADS__RollingCounter_244 20;
BA_ "GenSigCycleTime" SG_ 580 ADS_CRCCheck_244 20;
BA_ "GenSigCycleTime" SG_ 580 ADS_EOMTOReq 20;
BA_ "GenSigCycleTime" SG_ 580 ACC_HandsOnReq 20;
BA_ "GenSigCycleTime" SG_ 580 ACC_DynamicWarningLevel 20;
BA_ "GenSigCycleTime" SG_ 580 ACC_SafetyNotice 20;
BA_ "GenSigCycleTime" SG_ 580 ACC_LatTakeoverReq 20;
BA_ "GenSigCycleTime" SG_ 580 ACC_LngTakeOverReq 20;
BA_ "GenSigCycleTime" SG_ 580 ACC_TakeOverReq 20;
BA_ "GenSigCycleTime" SG_ 580 ACC_ADCNotice 20;
BA_ "GenSigCycleTime" SG_ 580 ACC_RWU_Parking_Request_Valid 20;
BA_ "GenSigInvalidValue" SG_ 580 ACC_RWU_Parking_Request_Valid "1";
BA_ "GenSigCycleTime" SG_ 580 ACC_RWU_Parking_Request 20;
BA_ "GenSigCycleTime" SG_ 580 ACC_CDP_Parking_Request_Valid 20;
BA_ "GenSigInvalidValue" SG_ 580 ACC_CDP_Parking_Request_Valid "1";
BA_ "GenSigCycleTime" SG_ 580 ACC_CDP_Parking_Request 20;
BA_ "GenSigCycleTime" SG_ 580 ACC_LDWShakeLevStatus 20;
BA_ "GenSigStartValue" SG_ 580 ACC_LDWShakeLevStatus 2;
BA_ "GenSigCycleTime" SG_ 580 ACC_TextInfoForDriver 20;
BA_ "GenSigCycleTime" SG_ 580 ADS_Authernticator_244 20;
BA_ "GenSigCycleTime" SG_ 580 ADS_ResetFlag_244 20;
BA_ "GenSigCycleTime" SG_ 580 ADS_MesssageCounter_244 20;
BA_ "GenSigCycleTime" SG_ 580 ACC_CRCCheck_25E 20;
BA_ "GenSigCycleTime" SG_ 580 ACC_RollingCounter_25E 20;
BA_ "GenSigCycleTime" SG_ 580 ACC_AEBCtrlType 20;
BA_ "GenSigCycleTime" SG_ 580 ACC_FuelCutOffPrevention 20;
BA_ "GenSigCycleTime" SG_ 580 ACC_AccTrqReqActive 20;
BA_ "GenSigCycleTime" SG_ 580 ACC_AccTrqReq 20;
BA_ "GenSigCycleTime" SG_ 580 ACC_AEBVehilceHoldReq 20;
BA_ "GenSigCycleTime" SG_ 580 ACC_FCWPreWarning 20;
BA_ "GenSigCycleTime" SG_ 580 ACC_FCWLatentWarning 20;
BA_ "GenSigCycleTime" SG_ 580 ACC_FCWActive 20;
BA_ "GenSigCycleTime" SG_ 580 ACC_PrefillActive 20;
BA_ "GenSigCycleTime" SG_ 580 ACC_AWBActive 20;
BA_ "GenSigCycleTime" SG_ 580 ACC_AWBlevel 20;
BA_ "GenSigCycleTime" SG_ 580 ACC_ABAActive 20;
BA_ "GenSigCycleTime" SG_ 580 ACC_ABAlevel 20;
BA_ "GenSigStartValue" SG_ 580 ACC_ABAlevel 3;
BA_ "GenSigCycleTime" SG_ 580 ACC_AEBActive 20;
BA_ "GenSigCycleTime" SG_ 580 ACC_AEBTargetDeceleration 20;
BA_ "GenSigStartValue" SG_ 580 ACC_AEBTargetDeceleration 32000;
BA_ "GenSigCycleTime" SG_ 580 ACC_EmergencyDataRrdReq 20;
BA_ "GenSigCycleTime" SG_ 580 ACC_CRCCheck_24E 20;
BA_ "GenSigCycleTime" SG_ 580 ACC_RollingCounter_24E 20;
BA_ "GenSigCycleTime" SG_ 580 ACC_Driveoff_Request 20;
BA_ "GenSigCycleTime" SG_ 580 ACC_ACCMode 20;
BA_ "GenSigInvalidValue" SG_ 580 ACC_ACCMode "7";
BA_ "GenSigCycleTime" SG_ 580 ACC_CCMode 20;
BA_ "GenSigInvalidValue" SG_ 580 ACC_CCMode "7";
BA_ "GenSigCycleTime" SG_ 580 ACC_CDDActive 20;
BA_ "GenSigCycleTime" SG_ 580 ACC_LimitSwitchArbitration 20;
BA_ "GenSigInvalidValue" SG_ 580 ACC_LimitSwitchArbitration "0";
BA_ "GenSigStartValue" SG_ 580 ACC_LimitSwitchArbitration 1;
BA_ "GenSigCycleTime" SG_ 580 ACC_EngineStartStopRequest 20;
BA_ "GenSigCycleTime" SG_ 580 ACC_DecToStop 20;
BA_ "GenSigCycleTime" SG_ 580 ACC_TCUCreepProhibition 20;
BA_ "GenSigCycleTime" SG_ 580 ACC_LKAStatus 20;
BA_ "GenSigInvalidValue" SG_ 580 ACC_LKAStatus "3";
BA_ "GenSigCycleTime" SG_ 580 ACC_LDWVibrationWarningReq 20;
BA_ "GenSigCycleTime" SG_ 580 ACC_LDWStatus 20;
BA_ "GenSigInvalidValue" SG_ 580 ACC_LDWStatus "3";
BA_ "GenSigCycleTime" SG_ 580 ACC_ACCTargetAcceleration 20;
BA_ "GenSigStartValue" SG_ 580 ACC_ACCTargetAcceleration 100;
BA_ "GenSigCycleTime" SG_ 583 APA_APAOnOff 20;
BA_ "GenSigCycleTime" SG_ 664 BCM_DriverDoorLockStatus 40;
BA_ "GenSigStartValue" SG_ 664 BCM_DriverDoorLockStatus 3;
BA_ "GenSigCycleTime" SG_ 664 BCM_LeftRearDoorStatus 40;
BA_ "GenSigCycleTime" SG_ 775 AD_LatDeviationDis 100;
BA_ "GenSigInvalidValue" SG_ 775 AD_LatDeviationDis "0";
BA_ "GenSigCycleTime" SG_ 775 AD_LatDeviationReason 100;
BA_ "GenSigInvalidValue" SG_ 775 AD_LatDeviationReason "0";
BA_ "GenSigCycleTime" SG_ 775 AD_IACCSuspendReason 100;
BA_ "GenSigInvalidValue" SG_ 775 AD_IACCSuspendReason "0";
BA_ "GenSigCycleTime" SG_ 775 ACC_IACCProhibitionTime 100;
BA_ "GenSigCycleTime" SG_ 775 ACC_Line_RR_Id 100;
BA_ "GenSigCycleTime" SG_ 775 ACC_Line_R_Id 100;
BA_ "GenSigCycleTime" SG_ 775 ACC_Line_LL_Id 100;
BA_ "GenSigCycleTime" SG_ 775 ACC_Line_L_Id 100;
BA_ "GenSigCycleTime" SG_ 775 ACC_RRLanecolor 100;
BA_ "GenSigCycleTime" SG_ 775 ACC_RLanecolor 100;
BA_ "GenSigCycleTime" SG_ 775 ACC_LLLanecolor 100;
BA_ "GenSigCycleTime" SG_ 775 ACC_LLanecolor 100;
BA_ "GenSigCycleTime" SG_ 775 ACC_VehicleStartRemindSts 100;
BA_ "GenSigCycleTime" SG_ 775 ADS_ResetSts 100;
BA_ "GenSigInvalidValue" SG_ 775 ADS_ResetSts "7";
BA_ "GenSigCycleTime" SG_ 775 ADS_IRLCEnable 100;
BA_ "GenSigCycleTime" SG_ 775 ADS_AutoDriveState 100;
BA_ "GenSigCycleTime" SG_ 775 ACC_CRCCheck_35F 100;
BA_ "GenSigCycleTime" SG_ 775 ACC_RollingCounter_35F 100;
BA_ "GenSigCycleTime" SG_ 775 ACC_CSLAEnableStatus 100;
BA_ "GenSigInvalidValue" SG_ 775 ACC_CSLAEnableStatus "3";
BA_ "GenSigCycleTime" SG_ 775 ACC_CSLSetReq 100;
BA_ "GenSigCycleTime" SG_ 775 ACC_HostPotentialTargetDirection 100;
BA_ "GenSigStartValue" SG_ 775 ACC_HostPotentialTargetDirection 5;
BA_ "GenSigCycleTime" SG_ 775 ACC_HostPotentialTargetType 100;
BA_ "GenSigCycleTime" SG_ 775 ACC_HostPotentialTargetLatRange 100;
BA_ "GenSigStartValue" SG_ 775 ACC_HostPotentialTargetLatRange 500;
BA_ "GenSigCycleTime" SG_ 775 ACC_HostPotentialTargetLngRange 100;
BA_ "GenSigStartValue" SG_ 775 ACC_HostPotentialTargetLngRange 500;
BA_ "GenSigCycleTime" SG_ 775 ACC_HostPotentialTargetDetection 100;
BA_ "GenSigCycleTime" SG_ 775 ACC_CRCCheck_344 100;
BA_ "GenSigCycleTime" SG_ 775 ACC_RollingCounter_344 100;
BA_ "GenSigCycleTime" SG_ 775 ACC_FLTarget2Type 100;
BA_ "GenSigCycleTime" SG_ 775 ACC_FLTarget2LngRange 100;
BA_ "GenSigStartValue" SG_ 775 ACC_FLTarget2LngRange 500;
BA_ "GenSigCycleTime" SG_ 775 ACC_FLTarget2Detection 100;
BA_ "GenSigCycleTime" SG_ 775 ACC_FLTarget2Direction 100;
BA_ "GenSigStartValue" SG_ 775 ACC_FLTarget2Direction 5;
BA_ "GenSigCycleTime" SG_ 775 ACC_FLTarget1Direction 100;
BA_ "GenSigStartValue" SG_ 775 ACC_FLTarget1Direction 5;
BA_ "GenSigCycleTime" SG_ 775 ACC_FLTarget1Type 100;
BA_ "GenSigCycleTime" SG_ 775 ACC_FLTarget1LatRange 100;
BA_ "GenSigStartValue" SG_ 775 ACC_FLTarget1LatRange 500;
BA_ "GenSigCycleTime" SG_ 775 ACC_FLTarget1LngRange 100;
BA_ "GenSigStartValue" SG_ 775 ACC_FLTarget1LngRange 500;
BA_ "GenSigCycleTime" SG_ 775 ACC_FLTarget1Detection 100;
BA_ "GenSigCycleTime" SG_ 775 ACC_CRCCheck_322 100;
BA_ "GenSigCycleTime" SG_ 775 ACC_RollingCounter_322 100;
BA_ "GenSigCycleTime" SG_ 775 ACC_HostTargetDetection 100;
BA_ "GenSigCycleTime" SG_ 775 ACC_ACCTargetDirection 100;
BA_ "GenSigStartValue" SG_ 775 ACC_ACCTargetDirection 5;
BA_ "GenSigCycleTime" SG_ 775 ACC_ACCTargetLatRange 100;
BA_ "GenSigStartValue" SG_ 775 ACC_ACCTargetLatRange 500;
BA_ "GenSigCycleTime" SG_ 775 ACC_ACCTargetRelSpd 100;
BA_ "GenSigStartValue" SG_ 775 ACC_ACCTargetRelSpd 250;
BA_ "GenSigCycleTime" SG_ 775 ACC_DistanceAlertLevel 100;
BA_ "GenSigCycleTime" SG_ 775 ACC_ACCTargetType 100;
BA_ "GenSigCycleTime" SG_ 775 ACC_FRadarCalibrationStatus 100;
BA_ "GenSigInvalidValue" SG_ 775 ACC_FRadarCalibrationStatus "3";
BA_ "GenSigCycleTime" SG_ 775 ACC_ACCTargetLngRange 100;
BA_ "GenSigStartValue" SG_ 775 ACC_ACCTargetLngRange 511;
BA_ "GenSigCycleTime" SG_ 775 ACC_CRCCheck_35E 100;
BA_ "GenSigCycleTime" SG_ 775 ACC_RollingCounter_35E 100;
BA_ "GenSigCycleTime" SG_ 775 ACC_SaftyBeltVibrationReq 100;
BA_ "GenSigCycleTime" SG_ 775 ACC_SaftyBelt_Tightened 100;
BA_ "GenSigCycleTime" SG_ 775 ACC_CruiseSetStatus 100;
BA_ "GenSigStartValue" SG_ 775 ACC_CruiseSetStatus 1;
BA_ "GenSigCycleTime" SG_ 775 ACC_ACCObjSoundEnable 100;
BA_ "GenSigCycleTime" SG_ 775 ACC_FCWSettingStatus 100;
BA_ "GenSigStartValue" SG_ 775 ACC_FCWSettingStatus 1;
BA_ "GenSigCycleTime" SG_ 775 ACC_AEBEnable 100;
BA_ "GenSigStartValue" SG_ 775 ACC_AEBEnable 1;
BA_ "GenSigCycleTime" SG_ 775 ACC_ACCEPBrequest 100;
BA_ "GenSigCycleTime" SG_ 775 ACC_ObjValid 100;
BA_ "GenSigCycleTime" SG_ 775 ACC_TimeGapSet 100;
BA_ "GenSigCycleTime" SG_ 775 ACC_DistanceLevel 100;
BA_ "GenSigCycleTime" SG_ 775 ACC_SetSpeed 100;
BA_ "GenSigCycleTime" SG_ 786 ACC_Selflearning_status 100;
BA_ "GenSigCycleTime" SG_ 786 ACC_Selflearning_angle 100;
BA_ "GenSigCycleTime" SG_ 786 ADS_ADSVoiceRequest 100;
BA_ "GenSigCycleTime" SG_ 786 ADS_ADSRoadVoiceEnableSts 100;
BA_ "GenSigCycleTime" SG_ 786 ADS_ADSLaneChangeVoiceEnableSts 100;
BA_ "GenSigCycleTime" SG_ 786 ADS_ADSSafeVoiceEnableSts 100;
BA_ "GenSigCycleTime" SG_ 786 ADS_NDANavEnableStatus 100;
BA_ "GenSigCycleTime" SG_ 786 ADS_NDAAudioWarEnableStatus 100;
BA_ "GenSigCycleTime" SG_ 786 ADS_NDAEnableStatus 100;
BA_ "GenSigCycleTime" SG_ 786 ADS_ALCDirection 100;
BA_ "GenSigCycleTime" SG_ 786 ADS_ALCTextInfoForDriver 100;
BA_ "GenSigCycleTime" SG_ 786 ADS_LaneChangeStyle 100;
BA_ "GenSigCycleTime" SG_ 786 ADS_UDLCVoiceRecStatus 100;
BA_ "GenSigInvalidValue" SG_ 786 ADS_UDLCVoiceRecStatus "7";
BA_ "GenSigCycleTime" SG_ 786 ADS_EOMStatus 100;
BA_ "GenSigCycleTime" SG_ 786 ADS_EOMSeatSteeringAdjustReq 100;
BA_ "GenSigCycleTime" SG_ 786 ADS_EOMDriverHeadPos 100;
BA_ "GenSigCycleTime" SG_ 786 ADS_EOMActiveReq 100;
BA_ "GenSigCycleTime" SG_ 786 ADS_SpdLimitedStatus 100;
BA_ "GenSigCycleTime" SG_ 786 ADS_CRCCheck_3D7 100;
BA_ "GenSigCycleTime" SG_ 786 ADS_RollingCounter_3D7 100;
BA_ "GenSigCycleTime" SG_ 786 ACC_SunroofControl 100;
BA_ "GenSigCycleTime" SG_ 786 ACC_RightRearWindowControl 100;
BA_ "GenSigCycleTime" SG_ 786 ACC_LeftRearWindowControl 100;
BA_ "GenSigCycleTime" SG_ 786 ACC_PassengerWindowControl 100;
BA_ "GenSigCycleTime" SG_ 786 ACC_DriverWindowControl 100;
BA_ "GenSigCycleTime" SG_ 786 ADS_UDLCTextInfoForDriver 100;
BA_ "GenSigCycleTime" SG_ 786 ADS_ToTargetLatDistance 100;
BA_ "GenSigCycleTime" SG_ 786 ADS_AutoWiperShift_Rqe 100;
BA_ "GenSigCycleTime" SG_ 786 ACC_HornCommand 100;
BA_ "GenSigCycleTime" SG_ 786 ADS_AutoHeadlightshift_Req 100;
BA_ "GenSigCycleTime" SG_ 786 ADS_HighBeamLampOnRequest 100;
BA_ "GenSigCycleTime" SG_ 786 ADS_LowBeamLampOnRequest 100;
BA_ "GenSigCycleTime" SG_ 786 ADS_LightFrequencyRequest 100;
BA_ "GenSigCycleTime" SG_ 786 ADS_LightBrightRequest 100;
BA_ "GenSigInvalidValue" SG_ 786 ADS_LightBrightRequest "7";
BA_ "GenSigCycleTime" SG_ 786 ADS_LightFlashRequest 100;
BA_ "GenSigCycleTime" SG_ 786 ADS_LightColorRequest 100;
BA_ "GenSigInvalidValue" SG_ 786 ADS_LightColorRequest "7";
BA_ "GenSigCycleTime" SG_ 786 ADS_LightingReq 100;
BA_ "GenSigInvalidValue" SG_ 786 ADS_LightingReq "0";
BA_ "GenSigCycleTime" SG_ 786 ADS_rescueReq 100;
BA_ "GenSigCycleTime" SG_ 786 ADS_SafeStopSts 100;
BA_ "GenSigInvalidValue" SG_ 786 ADS_SafeStopSts "3";
BA_ "GenSigCycleTime" SG_ 786 ADS_EyesOffWarningInhi 100;
BA_ "GenSigCycleTime" SG_ 786 ADS_EOMWarnning 100;
BA_ "GenSigCycleTime" SG_ 786 ADS_ESSEnable 100;
BA_ "GenSigCycleTime" SG_ 786 ADS_CRCCheck_358 100;
BA_ "GenSigCycleTime" SG_ 786 ADS_RollingCounter_358 100;
BA_ "GenSigCycleTime" SG_ 786 ADS_RLaneColor 100;
BA_ "GenSigCycleTime" SG_ 786 ADS_LLaneColor 100;
BA_ "GenSigCycleTime" SG_ 786 ADS_UDLCTurnRightRequest 100;
BA_ "GenSigCycleTime" SG_ 786 ADS_UDLCRightStatus 100;
BA_ "GenSigInvalidValue" SG_ 786 ADS_UDLCRightStatus "15";
BA_ "GenSigCycleTime" SG_ 786 ADS_UDLCTurnLeftRequest 100;
BA_ "GenSigCycleTime" SG_ 786 ADS_UDLCTurnLightReq 100;
BA_ "GenSigInvalidValue" SG_ 786 ADS_UDLCTurnLightReq "7";
BA_ "GenSigCycleTime" SG_ 786 ADS_UDLCLeftStatus 100;
BA_ "GenSigInvalidValue" SG_ 786 ADS_UDLCLeftStatus "15";
BA_ "GenSigCycleTime" SG_ 786 ADS_UDLCStatus 100;
BA_ "GenSigInvalidValue" SG_ 786 ADS_UDLCStatus "6";
BA_ "GenSigCycleTime" SG_ 786 ADS_UDLCEnableStatus 100;
BA_ "GenSigCycleTime" SG_ 786 ADS_ESSMode 100;
BA_ "GenSigInvalidValue" SG_ 786 ADS_ESSMode "3";
BA_ "GenSigCycleTime" SG_ 786 ADS_CRCCheck_342 100;
BA_ "GenSigCycleTime" SG_ 786 ADS_RollingCounter_342 100;
BA_ "GenSigCycleTime" SG_ 786 ACC_CRCCheck_3E4 100;
BA_ "GenSigCycleTime" SG_ 786 ACC_RollingCounter_3E4 100;
BA_ "GenSigCycleTime" SG_ 786 ACC_AEBTargetDirection 100;
BA_ "GenSigStartValue" SG_ 786 ACC_AEBTargetDirection 5;
BA_ "GenSigCycleTime" SG_ 786 ACC_AEBTargetDetection 100;
BA_ "GenSigCycleTime" SG_ 786 ACC_AEBTargetType 100;
BA_ "GenSigStartValue" SG_ 786 ACC_AEBTargetType 15;
BA_ "GenSigCycleTime" SG_ 786 ACC_RLaneDistanceFusion 100;
BA_ "GenSigStartValue" SG_ 786 ACC_RLaneDistanceFusion 36;
BA_ "GenSigCycleTime" SG_ 786 ACC_LLaneDistanceFusion 100;
BA_ "GenSigStartValue" SG_ 786 ACC_LLaneDistanceFusion 36;
BA_ "GenSigCycleTime" SG_ 786 ACC_HostPotentialTargetID 100;
BA_ "GenSigStartValue" SG_ 786 ACC_HostPotentialTargetID 15;
BA_ "GenSigCycleTime" SG_ 786 ACC_FRTarget2ID 100;
BA_ "GenSigStartValue" SG_ 786 ACC_FRTarget2ID 15;
BA_ "GenSigCycleTime" SG_ 786 ACC_FRTarget1ID 100;
BA_ "GenSigStartValue" SG_ 786 ACC_FRTarget1ID 15;
BA_ "GenSigCycleTime" SG_ 786 ACC_FLTarget2ID 100;
BA_ "GenSigStartValue" SG_ 786 ACC_FLTarget2ID 15;
BA_ "GenSigCycleTime" SG_ 786 ACC_FLTarget1ID 100;
BA_ "GenSigStartValue" SG_ 786 ACC_FLTarget1ID 15;
BA_ "GenSigCycleTime" SG_ 786 ACC_ACCTargetID 100;
BA_ "GenSigStartValue" SG_ 786 ACC_ACCTargetID 15;
BA_ "GenSigCycleTime" SG_ 832 AC_FrBlowType 100;
BA_ "GenSigInvalidValue" SG_ 832 AC_FrBlowType "7";
BA_ "GenSigCycleTime" SG_ 839 TPMS_RRPressureWarning 500;
BA_ "GenSigCycleTime" SG_ 839 TPMS_LRPressureWarning 500;
BA_ "GenSigCycleTime" SG_ 839 TPMS_LFPressureWarning 500;
BA_ "GenSigInvalidValue" SG_ 839 TPMS_LFPressureWarning "0";
BA_ "GenSigCycleTime" SG_ 839 TPMS_RFPressureWarning 500;
BA_ "GenSigCycleTime" SG_ 839 TPMS_LRTyrePressure 500;
BA_ "GenSigInvalidValue" SG_ 839 TPMS_LRTyrePressure "255";
BA_ "GenSigCycleTime" SG_ 839 TPMS_RRTyrePressure 500;
BA_ "GenSigInvalidValue" SG_ 839 TPMS_RRTyrePressure "255";
BA_ "GenSigCycleTime" SG_ 839 TPMS_RFTyrePressure 500;
BA_ "GenSigInvalidValue" SG_ 839 TPMS_RFTyrePressure "255";
BA_ "GenSigCycleTime" SG_ 839 TPMS_LFTyrePressure 500;
BA_ "GenSigInvalidValue" SG_ 839 TPMS_LFTyrePressure "255";
BA_ "GenSigCycleTime" SG_ 869 IMS_RollingCounter_3A7 100;
BA_ "GenSigCycleTime" SG_ 869 IMS_CRCCheck_3A7 100;
BA_ "GenSigCycleTime" SG_ 869 IMS_RollingCounter_360 100;
BA_ "GenSigCycleTime" SG_ 869 IMS_CRCCheck_360 100;
BA_ "GenSigCycleTime" SG_ 869 IMS_HeadDetectSts_Yaw 100;
BA_ "GenSigInvalidValue" SG_ 869 IMS_HeadDetectSts_Yaw "255";
BA_ "GenSigStartValue" SG_ 869 IMS_HeadDetectSts_Yaw 255;
BA_ "GenSigCycleTime" SG_ 869 IMS_HeadDetectSts_Roll 100;
BA_ "GenSigInvalidValue" SG_ 869 IMS_HeadDetectSts_Roll "255";
BA_ "GenSigStartValue" SG_ 869 IMS_HeadDetectSts_Roll 255;
BA_ "GenSigCycleTime" SG_ 869 IMS_HeadDetectSts_Pitch 100;
BA_ "GenSigInvalidValue" SG_ 869 IMS_HeadDetectSts_Pitch "255";
BA_ "GenSigStartValue" SG_ 869 IMS_HeadDetectSts_Pitch 255;
BA_ "GenSigCycleTime" SG_ 869 IMS_RollingCounter_356 100;
BA_ "GenSigCycleTime" SG_ 869 IMS_CRCCheck_356 100;
BA_ "GenSigCycleTime" SG_ 869 IMS_IMSStatus 100;
BA_ "GenSigInvalidValue" SG_ 869 IMS_IMSStatus "7";
BA_ "GenSigStartValue" SG_ 869 IMS_IMSStatus 1;
BA_ "GenSigCycleTime" SG_ 869 IMS_EyeGazeStatus 100;
BA_ "GenSigInvalidValue" SG_ 869 IMS_EyeGazeStatus "255";
BA_ "GenSigStartValue" SG_ 869 IMS_EyeGazeStatus 255;
BA_ "GenSigCycleTime" SG_ 869 IMS_EyeDetectSatus 100;
BA_ "GenSigInvalidValue" SG_ 869 IMS_EyeDetectSatus "255";
BA_ "GenSigStartValue" SG_ 869 IMS_EyeDetectSatus 255;
BA_ "GenSigCycleTime" SG_ 869 IMS_DrowsinessStatus 100;
BA_ "GenSigInvalidValue" SG_ 869 IMS_DrowsinessStatus "7";
BA_ "GenSigCycleTime" SG_ 869 IMS_DriverHeadDetect 100;
BA_ "GenSigInvalidValue" SG_ 869 IMS_DriverHeadDetect "0";
BA_ "GenSigCycleTime" SG_ 869 IMS_DistractionStatus 100;
BA_ "GenSigInvalidValue" SG_ 869 IMS_DistractionStatus "3";
BA_ "GenSigCycleTime" SG_ 870 AC_EnvironmentalTemp 100;
BA_ "GenSigInvalidValue" SG_ 870 AC_EnvironmentalTemp "255";
BA_ "GenSigStartValue" SG_ 870 AC_EnvironmentalTemp 255;
BA_ "GenSigCycleTime" SG_ 870 AC_EnvironmentalTempVD 100;
BA_ "GenSigInvalidValue" SG_ 870 AC_EnvironmentalTempVD "1";
BA_ "GenSigCycleTime" SG_ 903 BCM_RainfallLevel 100;
BA_ "GenSigInvalidValue" SG_ 903 BCM_RainfallLevel "15";
BA_ "GenSigStartValue" SG_ 903 BCM_RainfallLevel 14;
BA_ "GenSigCycleTime" SG_ 903 BCM_FrontWiperStatus 100;
BA_ "GenSigInvalidValue" SG_ 903 BCM_FrontWiperStatus "3";
BA_ "GenSigCycleTime" SG_ 903 BCM_RLS_Light_switch_reason 100;
BA_ "GenSigInvalidValue" SG_ 903 BCM_RLS_Light_switch_reason "255";
BA_ "GenSigStartValue" SG_ 903 BCM_RLS_Light_switch_reason 255;
BA_ "GenSigCycleTime" SG_ 912 BCM_SOH_LifePercent 500;
BA_ "GenSigInvalidValue" SG_ 912 BCM_SOH_LifePercent "255";
BA_ "GenSigStartValue" SG_ 912 BCM_SOH_LifePercent 255;
BA_ "GenSigCycleTime" SG_ 912 BCM_PMSLevel 500;
BA_ "GenSigCycleTime" SG_ 918 BCM_SunroofStatus 100;
BA_ "GenSigCycleTime" SG_ 1302 HU_LocalTimeSystem 1000;
BA_ "GenSigCycleTime" SG_ 1302 HU_LocalTimeSecond 1000;
BA_ "GenSigInvalidValue" SG_ 1302 HU_LocalTimeSecond "0";
BA_ "GenSigCycleTime" SG_ 1302 HU_LocalTimeMinute 1000;
BA_ "GenSigInvalidValue" SG_ 1302 HU_LocalTimeMinute "0";
BA_ "GenSigCycleTime" SG_ 1302 HU_LocalTimeHour 1000;
BA_ "GenSigInvalidValue" SG_ 1302 HU_LocalTimeHour "0";
BA_ "GenSigCycleTime" SG_ 1302 HU_LocalTimeDate 1000;
BA_ "GenSigInvalidValue" SG_ 1302 HU_LocalTimeDate "1";
BA_ "GenSigStartValue" SG_ 1302 HU_LocalTimeDate 1;
BA_ "GenSigCycleTime" SG_ 1302 HU_LocalTimeYear 1000;
BA_ "GenSigInvalidValue" SG_ 1302 HU_LocalTimeYear "0";
BA_ "GenSigCycleTime" SG_ 1302 HU_LocalTimeMonth 1000;
BA_ "GenSigInvalidValue" SG_ 1302 HU_LocalTimeMonth "1";
BA_ "GenSigStartValue" SG_ 1302 HU_LocalTimeMonth 1;
BA_ "GenSigCycleTime" SG_ 1302 HU_LocalTimeValid 1000;
BA_ "GenSigInvalidValue" SG_ 1302 HU_LocalTimeValid "1";
BA_ "GenSigCycleTime" SG_ 1302 HU_CurrentLocationLatitude 1000;
BA_ "GenSigInvalidValue" SG_ 1302 HU_CurrentLocationLatitude "268435455";
BA_ "GenSigCycleTime" SG_ 1302 HU_CurrentLocationLongitude 1000;
BA_ "GenSigInvalidValue" SG_ 1302 HU_CurrentLocationLongitude "536870911";
BA_ "GenSigCycleTime" SG_ 1302 HU_CurrentLocationValid 1000;
BA_ "GenSigInvalidValue" SG_ 1302 HU_CurrentLocationValid "1";
BA_ "GenSigCycleTime" SG_ 1352 ADS_EventTimeSecond 500;
BA_ "GenSigCycleTime" SG_ 1352 ADS_EventTimeMinute 500;
BA_ "GenSigCycleTime" SG_ 1352 ADS_EventTimeHour 500;
BA_ "GenSigCycleTime" SG_ 1352 ADS_EventTimeDay 500;
BA_ "GenSigCycleTime" SG_ 1352 ADS_EventTimeMonth 500;
BA_ "GenSigCycleTime" SG_ 1352 ADS_EventTimeYear 500;
BA_ "GenSigCycleTime" SG_ 1352 ADS_EventCode 500;
BA_ "GenSigCycleTime" SG_ 1352 ADS_EventAmount 500;
BA_ "GenSigCycleTime" SG_ 1352 ADS_EventStartEndIdentify 500;
BA_ "GenSigCycleTime" SG_ 1352 ADS_EID 500;
BA_ "GenSigCycleTime" SG_ 1352 ADS_ControllerCode 500;
BA_ "GenSigCycleTime" SG_ 1554 DVR_EmergencyRecordStatus 100;
BA_ "GenSigInvalidValue" SG_ 1554 DVR_EmergencyRecordStatus "0";
BA_ "GenSigCycleTime" SG_ 1554 DVR_Error 100;
BA_ "GenSigInvalidValue" SG_ 1554 DVR_Error "1";
BA_ "GenSigCycleTime" SG_ 382 EPS_ADS_Abortfeedback 10;
BA_ "GenSigInvalidValue" SG_ 382 EPS_ADS_Abortfeedback "15";
BA_ "GenSigCycleTime" SG_ 382 EPS_LatCtrlActive 10;
BA_ "GenSigInvalidValue" SG_ 382 EPS_LatCtrlActive "0";
BA_ "GenSigCycleTime" SG_ 382 EPS_LatCtrlAvailabilityStatus 10;
BA_ "GenSigInvalidValue" SG_ 382 EPS_LatCtrlAvailabilityStatus "2";
BA_ "GenSigCycleTime" SG_ 382 EPS_CRCCheck_17E 10;
BA_ "GenSigCycleTime" SG_ 382 EPS_RollingCounter_17E 10;
BA_ "GenSigCycleTime" SG_ 382 EPS_MeasuredTorsionBarTorqValid 10;
BA_ "GenSigInvalidValue" SG_ 382 EPS_MeasuredTorsionBarTorqValid "1";
BA_ "GenSigCycleTime" SG_ 382 EPS_MeasuredTorsionBarTorque 10;
BA_ "GenSigInvalidValue" SG_ 382 EPS_MeasuredTorsionBarTorque "4095";
BA_ "GenSigStartValue" SG_ 382 EPS_MeasuredTorsionBarTorque 2048;
BA_ "GenSigCycleTime" SG_ 398 EMS_RollingCounter_18E 10;
BA_ "GenSigCycleTime" SG_ 398 EMS_CRCCheck_18E 10;
BA_ "GenSigCycleTime" SG_ 398 EMS_CRCCheck_1A6 10;
BA_ "GenSigCycleTime" SG_ 398 EMS_RollingCounter_1A6 10;
BA_ "GenSigCycleTime" SG_ 398 EMS_EngineStatus 10;
BA_ "GenSigCycleTime" SG_ 398 EMS_MinIndicatedTorq 10;
BA_ "GenSigInvalidValue" SG_ 398 EMS_MinIndicatedTorq "255";
BA_ "GenSigCycleTime" SG_ 398 EMS_MaxIndicatedTorq 10;
BA_ "GenSigInvalidValue" SG_ 398 EMS_MaxIndicatedTorq "255";
BA_ "GenSigCycleTime" SG_ 398 EMS_TorqueConstant 10;
BA_ "GenSigInvalidValue" SG_ 398 EMS_TorqueConstant "255";
BA_ "GenSigCycleTime" SG_ 398 EMS_RollingCounter_196 10;
BA_ "GenSigCycleTime" SG_ 398 EMS_CRCCheck_196 10;
BA_ "GenSigCycleTime" SG_ 398 EMS_AccPedal 10;
BA_ "GenSigInvalidValue" SG_ 398 EMS_AccPedal "255";
BA_ "GenSigCycleTime" SG_ 398 EMS_EngineSpeed 10;
BA_ "GenSigInvalidValue" SG_ 398 EMS_EngineSpeed "65535";
BA_ "GenSigCycleTime" SG_ 398 EMS_AccpedelError 10;
BA_ "GenSigInvalidValue" SG_ 398 EMS_AccpedelError "1";
BA_ "GenSigCycleTime" SG_ 398 EMS_EngineSpeedError 10;
BA_ "GenSigInvalidValue" SG_ 398 EMS_EngineSpeedError "1";
BA_ "GenSigCycleTime" SG_ 398 EMS_EngineFuelCutOff 10;
BA_ "GenSigCycleTime" SG_ 398 EMS_BrakePedalStatus 10;
BA_ "GenSigInvalidValue" SG_ 398 EMS_BrakePedalStatus "3";
BA_ "GenSigCycleTime" SG_ 398 EMS_RealAccPedal 10;
BA_ "GenSigInvalidValue" SG_ 398 EMS_RealAccPedal "255";
BA_ "GenSigCycleTime" SG_ 398 EMS_RollingCounter_184 10;
BA_ "GenSigCycleTime" SG_ 398 EMS_CRCCheck_184 10;
BA_ "GenSigCycleTime" SG_ 398 EMS_IndicatedRealEngTorq 10;
BA_ "GenSigInvalidValue" SG_ 398 EMS_IndicatedRealEngTorq "65535";
BA_ "GenSigCycleTime" SG_ 398 EMS_FrictionalTorq 10;
BA_ "GenSigInvalidValue" SG_ 398 EMS_FrictionalTorq "65535";
BA_ "GenSigCycleTime" SG_ 398 EMS_IndicatedDriverReqTorq 10;
BA_ "GenSigInvalidValue" SG_ 398 EMS_IndicatedDriverReqTorq "65535";
BA_ "GenSigCycleTime" SG_ 398 EMS_TorqFailure 10;
BA_ "GenSigInvalidValue" SG_ 398 EMS_TorqFailure "1";
BA_ "GenSigCycleTime" SG_ 442 ACC_LatAngReqActive 10;
BA_ "GenSigCycleTime" SG_ 442 ACC_LatAngReq 10;
BA_ "GenSigInvalidValue" SG_ 442 ACC_LatAngReq "14401";
BA_ "GenSigStartValue" SG_ 442 ACC_LatAngReq 7200;
BA_ "GenSigCycleTime" SG_ 442 ADS_Authernticator_1BA 10;
BA_ "GenSigCycleTime" SG_ 442 ADS_ResetFlag_1BA 10;
BA_ "GenSigCycleTime" SG_ 442 ADS_MesssageCounter_1BA 10;
BA_ "GenSigCycleTime" SG_ 442 ACC_CRCCheck_1BA_0 10;
BA_ "GenSigCycleTime" SG_ 442 ACC_RollingCounter_1BA_0 10;
BA_ "GenSigCycleTime" SG_ 442 ADS_ESSActive 10;
BA_ "GenSigCycleTime" SG_ 442 ACC_MotorTorqueMinLimitRequest 10;
BA_ "GenSigStartValue" SG_ 442 ACC_MotorTorqueMinLimitRequest 1024;
BA_ "GenSigCycleTime" SG_ 442 ACC_MotorTorqueMaxLimitRequest 10;
BA_ "GenSigStartValue" SG_ 442 ACC_MotorTorqueMaxLimitRequest 1024;
BA_ "GenSigCycleTime" SG_ 588 TCU_RollingCounter_24C 20;
BA_ "GenSigCycleTime" SG_ 591 EPS_ConcussAvailabilityStatus 20;
BA_ "GenSigInvalidValue" SG_ 591 EPS_ConcussAvailabilityStatus "2";
BA_ "GenSigCycleTime" SG_ 591 EPS_TorqueAssistMode 20;
BA_ "GenSigStartValue" SG_ 591 EPS_TorqueAssistMode 3;
BA_ "GenSigCycleTime" SG_ 591 EPS_IACC_abortreason 20;
BA_ "GenSigCycleTime" SG_ 591 EPS_CRCCheck_24F 20;
BA_ "GenSigCycleTime" SG_ 591 EPS_RollingCounter_24F 20;
BA_ "GenSigCycleTime" SG_ 618 EMS_CRCCheck_26A 20;
BA_ "GenSigCycleTime" SG_ 618 EMS_RollingCounter_26A 20;
BA_ "GenSigCycleTime" SG_ 618 EMS_EngineStatusWithSTT 20;
BA_ "GenSigInvalidValue" SG_ 618 EMS_EngineStatusWithSTT "7";
BA_ "GenSigCycleTime" SG_ 618 EMS_AccReqPossible 20;
BA_ "GenSigInvalidValue" SG_ 618 EMS_AccReqPossible "1";
BA_ "GenSigCycleTime" SG_ 618 EMS_QECACC 20;
BA_ "GenSigInvalidValue" SG_ 618 EMS_QECACC "3";
BA_ "GenSigCycleTime" SG_ 618 EMS_ECGPOvrd 20;
BA_ "GenSigInvalidValue" SG_ 618 EMS_ECGPOvrd "1";
BA_ "GenSigCycleTime" SG_ 651 BCM_CRCCheck_28B 40;
BA_ "GenSigCycleTime" SG_ 651 BCM_RollingCounter_28B 40;
BA_ "GenSigCycleTime" SG_ 651 BCM_TurnIndicatorLeft 40;
BA_ "GenSigInvalidValue" SG_ 651 BCM_TurnIndicatorLeft "3";
BA_ "GenSigCycleTime" SG_ 651 BCM_TurnIndicatorRight 40;
BA_ "GenSigInvalidValue" SG_ 651 BCM_TurnIndicatorRight "3";
BA_ "GenSigCycleTime" SG_ 651 BCM_emergencylightstatus 40;
BA_ "GenSigInvalidValue" SG_ 651 BCM_emergencylightstatus "3";
BA_ "GenSigCycleTime" SG_ 651 BCM_PowerStatusFeedback 40;
BA_ "GenSigCycleTime" SG_ 651 BCM_DriverDoorStatus 40;
BA_ "GenSigCycleTime" SG_ 651 BCM_HoodStatus 40;
BA_ "GenSigCycleTime" SG_ 651 BCM_LowBeamStatus 40;
BA_ "GenSigInvalidValue" SG_ 651 BCM_LowBeamStatus "3";
BA_ "GenSigCycleTime" SG_ 651 BCM_HighBeamStatus 40;
BA_ "GenSigInvalidValue" SG_ 651 BCM_HighBeamStatus "3";
BA_ "GenSigCycleTime" SG_ 651 BCM_TurnLightSwitchSts 40;
BA_ "GenSigInvalidValue" SG_ 651 BCM_TurnLightSwitchSts "3";
BA_ "GenSigCycleTime" SG_ 651 BCM_MirrorAdjustSts 40;
BA_ "GenSigCycleTime" SG_ 676 RRC_RollingCounter_2A4 50;
BA_ "GenSigCycleTime" SG_ 676 RRC_CRCCheck_2A4 50;
BA_ "GenSigCycleTime" SG_ 676 LCDAR_RCTBStatus 50;
BA_ "GenSigInvalidValue" SG_ 676 LCDAR_RCTBStatus "3";
BA_ "GenSigCycleTime" SG_ 676 LCDAR_CRCCheck_2AF 50;
BA_ "GenSigCycleTime" SG_ 676 LCDAR_RollingCounter_2AF 50;
BA_ "GenSigCycleTime" SG_ 676 LCDAR_ELK_oAlert 50;
BA_ "GenSigCycleTime" SG_ 676 LCDAR_ELK_oStatus 50;
BA_ "GenSigInvalidValue" SG_ 676 LCDAR_ELK_oStatus "3";
BA_ "GenSigCycleTime" SG_ 676 LCDAR_Left_ELK_oAlert 50;
BA_ "GenSigCycleTime" SG_ 676 LCDAR_RCTBActive 50;
BA_ "GenSigInvalidValue" SG_ 676 LCDAR_RCTBActive "0";
BA_ "GenSigCycleTime" SG_ 676 LCDAR_RCTBTargetDecel 50;
BA_ "GenSigStartValue" SG_ 676 LCDAR_RCTBTargetDecel 32000;
BA_ "GenSigCycleTime" SG_ 676 LCDAR_RCTBEnable 50;
BA_ "GenSigInvalidValue" SG_ 676 LCDAR_RCTBEnable "0";
BA_ "GenSigStartValue" SG_ 676 LCDAR_RCTBEnable 1;
BA_ "GenSigCycleTime" SG_ 676 LCDAR_SystemStatus 50;
BA_ "GenSigInvalidValue" SG_ 676 LCDAR_SystemStatus "7";
BA_ "GenSigStartValue" SG_ 676 LCDAR_SystemStatus 1;
BA_ "GenSigCycleTime" SG_ 710 APA_vehicleFrontdetect 40;
BA_ "GenSigInvalidValue" SG_ 710 APA_vehicleFrontdetect "3";
BA_ "GenSigCycleTime" SG_ 721 BCM_TrunkDoorStatus 40;
BA_ "GenSigCycleTime" SG_ 721 BCM_RightRearDoorStatus 40;
BA_ "GenSigCycleTime" SG_ 721 BCM_PassengerDoorStatus 40;
BA_ "GenSigCycleTime" SG_ 726 EMS_CRCCheck_2D6 50;
BA_ "GenSigCycleTime" SG_ 726 EMS_RollingCounter_2D6 50;
BA_ "GenSigCycleTime" SG_ 726 EMS_AltitudeFactor 50;
BA_ "GenSigInvalidValue" SG_ 726 EMS_AltitudeFactor "255";
BA_ "GenSigStartValue" SG_ 726 EMS_AltitudeFactor 64;
BA_ "GenSigCycleTime" SG_ 726 EMS_EngineLimpHome 50;
BA_ "GenSigInvalidValue" SG_ 726 EMS_EngineLimpHome "1";
BA_ "GenSigCycleTime" SG_ 794 AD_HandsoffWarningExitReason 100;
BA_ "GenSigInvalidValue" SG_ 794 AD_HandsoffWarningExitReason "0";
BA_ "GenSigCycleTime" SG_ 794 ACC_LngTakeOverReqReason 100;
BA_ "GenSigInvalidValue" SG_ 794 ACC_LngTakeOverReqReason "0";
BA_ "GenSigCycleTime" SG_ 794 ACC_ELKAlert 100;
BA_ "GenSigCycleTime" SG_ 794 ADS_HWAEnableStatus 100;
BA_ "GenSigCycleTime" SG_ 794 ADS_IsInFence 100;
BA_ "GenSigCycleTime" SG_ 794 ADS_TJPEnableStatus 100;
BA_ "GenSigCycleTime" SG_ 794 ACC_CRCCheck_367 100;
BA_ "GenSigCycleTime" SG_ 794 ACC_RollingCounter_367 100;
BA_ "GenSigCycleTime" SG_ 794 ACC_LatPathHeadingAngle 100;
BA_ "GenSigCycleTime" SG_ 794 ACC_LatPathDY 100;
BA_ "GenSigCycleTime" SG_ 794 ACC_ELKEnableStatus 100;
BA_ "GenSigCycleTime" SG_ 794 ACC_ELKInterventionMode 100;
BA_ "GenSigCycleTime" SG_ 794 ACC_ELKMode 100;
BA_ "GenSigInvalidValue" SG_ 794 ACC_ELKMode "3";
BA_ "GenSigCycleTime" SG_ 794 ACC_HostPedLatRange_1 100;
BA_ "GenSigStartValue" SG_ 794 ACC_HostPedLatRange_1 125;
BA_ "GenSigCycleTime" SG_ 794 ACC_HostPedLngRange_1 100;
BA_ "GenSigStartValue" SG_ 794 ACC_HostPedLngRange_1 63;
BA_ "GenSigCycleTime" SG_ 794 ACC_HostPedDetection_1 100;
BA_ "GenSigCycleTime" SG_ 794 ACC_CRCCheck_30D 100;
BA_ "GenSigCycleTime" SG_ 794 ACC_RollingCounter_30D 100;
BA_ "GenSigCycleTime" SG_ 794 ACC_RRLaneDistance 100;
BA_ "GenSigStartValue" SG_ 794 ACC_RRLaneDistance 28;
BA_ "GenSigCycleTime" SG_ 794 ACC_RRLaneDetection 100;
BA_ "GenSigCycleTime" SG_ 794 ACC_LLLaneDistance 100;
BA_ "GenSigStartValue" SG_ 794 ACC_LLLaneDistance 28;
BA_ "GenSigCycleTime" SG_ 794 ACC_LLLaneDetection 100;
BA_ "GenSigCycleTime" SG_ 794 ACC_DoorCtrlReq 100;
BA_ "GenSigCycleTime" SG_ 794 ACC_HighBeamControl 100;
BA_ "GenSigCycleTime" SG_ 794 ACC_TargetBasedLateralControl 100;
BA_ "GenSigCycleTime" SG_ 794 ACC_IACCHWATextInfoForDriver 100;
BA_ "GenSigCycleTime" SG_ 794 ACC_EmergencyLightingRequest 100;
BA_ "GenSigCycleTime" SG_ 794 ACC_HandsoffFuncTextinfo 100;
BA_ "GenSigCycleTime" SG_ 794 ACC_HandsoffFuncStatus 100;
BA_ "GenSigInvalidValue" SG_ 794 ACC_HandsoffFuncStatus "7";
BA_ "GenSigCycleTime" SG_ 794 ACC_DriverHandsOffStatus 100;
BA_ "GenSigInvalidValue" SG_ 794 ACC_DriverHandsOffStatus "3";
BA_ "GenSigCycleTime" SG_ 794 ACC_IACCHWAMode 100;
BA_ "GenSigInvalidValue" SG_ 794 ACC_IACCHWAMode "7";
BA_ "GenSigCycleTime" SG_ 794 ACC_CRCCheck_30A 100;
BA_ "GenSigCycleTime" SG_ 794 ACC_RollingCounter_30A 100;
BA_ "GenSigCycleTime" SG_ 794 ACC_LaneChangeStatus 100;
BA_ "GenSigCycleTime" SG_ 794 ACC_RoadCurvatureFar 100;
BA_ "GenSigStartValue" SG_ 794 ACC_RoadCurvatureFar 60;
BA_ "GenSigCycleTime" SG_ 794 ACC_RoadCurvatureNear 100;
BA_ "GenSigStartValue" SG_ 794 ACC_RoadCurvatureNear 60;
BA_ "GenSigCycleTime" SG_ 794 ACC_RoadCurvature 100;
BA_ "GenSigStartValue" SG_ 794 ACC_RoadCurvature 60;
BA_ "GenSigCycleTime" SG_ 794 ACC_IACCHWAEnable 100;
BA_ "GenSigCycleTime" SG_ 794 ACC_RLaneMarkerType 100;
BA_ "GenSigStartValue" SG_ 794 ACC_RLaneMarkerType 7;
BA_ "GenSigCycleTime" SG_ 794 ACC_LLaneMarkerType 100;
BA_ "GenSigStartValue" SG_ 794 ACC_LLaneMarkerType 7;
BA_ "GenSigCycleTime" SG_ 794 ACC_HostLaneRightStatus 100;
BA_ "GenSigCycleTime" SG_ 794 ACC_HostLaneLeftStatus 100;
BA_ "GenSigCycleTime" SG_ 794 ACC_LASWarningModeSelectionSts 100;
BA_ "GenSigStartValue" SG_ 794 ACC_LASWarningModeSelectionSts 2;
BA_ "GenSigCycleTime" SG_ 794 ACC_LASModeSelectionStatus 100;
BA_ "GenSigStartValue" SG_ 794 ACC_LASModeSelectionStatus 1;
BA_ "GenSigCycleTime" SG_ 794 ACC_CRCCheck_36D 100;
BA_ "GenSigCycleTime" SG_ 794 ACC_RollingCounter_36D 100;
BA_ "GenSigCycleTime" SG_ 794 ACC_FRadarFailureStatus 100;
BA_ "GenSigInvalidValue" SG_ 794 ACC_FRadarFailureStatus "3";
BA_ "GenSigCycleTime" SG_ 794 ACC_AEBTargetLatRange 100;
BA_ "GenSigStartValue" SG_ 794 ACC_AEBTargetLatRange 500;
BA_ "GenSigCycleTime" SG_ 794 ACC_AEBTargetRelSpeed 100;
BA_ "GenSigStartValue" SG_ 794 ACC_AEBTargetRelSpeed 250;
BA_ "GenSigCycleTime" SG_ 794 ACC_AEBTargetLngRange 100;
BA_ "GenSigStartValue" SG_ 794 ACC_AEBTargetLngRange 500;
BA_ "GenSigCycleTime" SG_ 794 ACC_Voiceinfo 100;
BA_ "GenSigCycleTime" SG_ 794 ACC_AEBTargetmode 100;
BA_ "GenSigCycleTime" SG_ 794 ACC_AEBTextInfo 100;
BA_ "GenSigCycleTime" SG_ 794 ACC_AEBStatus 100;
BA_ "GenSigInvalidValue" SG_ 794 ACC_AEBStatus "3";
BA_ "GenSigCycleTime" SG_ 879 ACC_RollingCounter_36F 100;
BA_ "GenSigCycleTime" SG_ 879 ACC_CRCCheck_36F 100;
BA_ "GenSigCycleTime" SG_ 879 ADS_PathShow_Sts 100;
BA_ "GenSigCycleTime" SG_ 879 ADS_NDAFenceTerminalDis 100;
BA_ "GenSigInvalidValue" SG_ 879 ADS_NDAFenceTerminalDis "1023";
BA_ "GenSigCycleTime" SG_ 879 ADS_NDATextInfo 100;
BA_ "GenSigCycleTime" SG_ 879 ADS_NDAStatus 100;
BA_ "GenSigInvalidValue" SG_ 879 ADS_NDAStatus "0";
BA_ "GenSigCycleTime" SG_ 879 ACC_CRCCheck_3CD 100;
BA_ "GenSigCycleTime" SG_ 879 ACC_RollingCounter_3CD 100;
BA_ "GenSigCycleTime" SG_ 879 ACC_CRCCheck_3CB 100;
BA_ "GenSigCycleTime" SG_ 879 ACC_RollingCounter_3CB 100;
BA_ "GenSigCycleTime" SG_ 879 ACC_CRCCheck_3CA 100;
BA_ "GenSigCycleTime" SG_ 879 ACC_RollingCounter_3CA 100;
BA_ "GenSigCycleTime" SG_ 879 ACC_CRCCheck_3C8 100;
BA_ "GenSigCycleTime" SG_ 879 ACC_RollingCounter_3C8 100;
BA_ "GenSigCycleTime" SG_ 879 ACC_CRCCheck_374 100;
BA_ "GenSigCycleTime" SG_ 879 ACC_RollingCounter_374 100;
BA_ "GenSigCycleTime" SG_ 879 ADS_TunnelStatus 100;
BA_ "GenSigCycleTime" SG_ 879 ADS_TunnelDis 100;
BA_ "GenSigCycleTime" SG_ 879 ADS_RampStatus 100;
BA_ "GenSigCycleTime" SG_ 879 ADS_PathThroughRamp 100;
BA_ "GenSigCycleTime" SG_ 879 ADS_RampSide 100;
BA_ "GenSigCycleTime" SG_ 879 ADS_DisToRamp 100;
BA_ "GenSigCycleTime" SG_ 879 ADS_PathShowLngRange 100;
BA_ "GenSigCycleTime" SG_ 879 ADS_RoadMergeLatRange 100;
BA_ "GenSigCycleTime" SG_ 879 ADS_EOMNotice 100;
BA_ "GenSigCycleTime" SG_ 879 ADS_SeatPostureRectifyReq 100;
BA_ "GenSigCycleTime" SG_ 879 ADS_PromptCountDown 100;
BA_ "GenSigCycleTime" SG_ 879 ADS_EOMDwgradingnotice 100;
BA_ "GenSigCycleTime" SG_ 879 ADS_AutoDriveStateDisplay 100;
BA_ "GenSigCycleTime" SG_ 879 ADS_PathShow_Status 100;
BA_ "GenSigCycleTime" SG_ 879 ADS_PathShow_C3 100;
BA_ "GenSigCycleTime" SG_ 879 ADS_PathShow_C2 100;
BA_ "GenSigCycleTime" SG_ 879 ADS_PathShow_C1 100;
BA_ "GenSigCycleTime" SG_ 879 ADS_RoadSlopeFlag 100;
BA_ "GenSigCycleTime" SG_ 879 ADS_RoadSlopeShapeC3 100;
BA_ "GenSigCycleTime" SG_ 879 ADS_RoadSlopeShapeC2 100;
BA_ "GenSigCycleTime" SG_ 879 ADS_RoadSlopeShapeC1 100;
BA_ "GenSigCycleTime" SG_ 879 ADS_RoadMergeFlag 100;
BA_ "GenSigCycleTime" SG_ 879 ADS_RoadLngRange 100;
BA_ "GenSigCycleTime" SG_ 879 ADS_RemoteRoadShapeC3 100;
BA_ "GenSigCycleTime" SG_ 879 ADS_RemoteRoadShapeC2 100;
BA_ "GenSigCycleTime" SG_ 879 ADS_RemoteRoadShapeC1 100;
BA_ "GenSigCycleTime" SG_ 879 ACC_TakeoverReqAtIPFail 100;
BA_ "GenSigCycleTime" SG_ 879 ADS_TSRHostNextSpdLimitDist 100;
BA_ "GenSigCycleTime" SG_ 879 ADS_TSRHostNextSpdLimit 100;
BA_ "GenSigCycleTime" SG_ 879 ADS_RightPedWarnLevel 100;
BA_ "GenSigCycleTime" SG_ 879 ADS_RightPedDetection 100;
BA_ "GenSigInvalidValue" SG_ 879 ADS_RightPedDetection "3";
BA_ "GenSigCycleTime" SG_ 879 ADS_LeftPedWarnLevel 100;
BA_ "GenSigCycleTime" SG_ 879 ADS_LeftPedDetection 100;
BA_ "GenSigInvalidValue" SG_ 879 ADS_LeftPedDetection "3";
BA_ "GenSigCycleTime" SG_ 879 ADS_HostPedWarnLevel_1 100;
BA_ "GenSigCycleTime" SG_ 922 LAS_TSRSpeedLimitType 100;
BA_ "GenSigInvalidValue" SG_ 922 LAS_TSRSpeedLimitType "0";
BA_ "GenSigCycleTime" SG_ 922 ACC_RollingCounter_39A 100;
BA_ "GenSigCycleTime" SG_ 922 ACC_CRCCheck_39A 100;
BA_ "GenSigCycleTime" SG_ 922 LAS_TSRRightLaneStatus 100;
BA_ "GenSigInvalidValue" SG_ 922 LAS_TSRRightLaneStatus "7";
BA_ "GenSigCycleTime" SG_ 922 LAS_TSRLeftLaneStatus 100;
BA_ "GenSigInvalidValue" SG_ 922 LAS_TSRLeftLaneStatus "7";
BA_ "GenSigCycleTime" SG_ 922 LAS_CRCCheck_3C0 100;
BA_ "GenSigCycleTime" SG_ 922 LAS_RollingCounter_3C0 100;
BA_ "GenSigCycleTime" SG_ 922 LAS_TSRRightLaneSpdLimit 100;
BA_ "GenSigInvalidValue" SG_ 922 LAS_TSRRightLaneSpdLimit "254";
BA_ "GenSigCycleTime" SG_ 922 LAS_TSRLeftLaneSpdLimit 100;
BA_ "GenSigInvalidValue" SG_ 922 LAS_TSRLeftLaneSpdLimit "254";
BA_ "GenSigCycleTime" SG_ 922 LAS_CRCCheck_3D4 100;
BA_ "GenSigCycleTime" SG_ 922 LAS_RollingCounter_3D4 100;
BA_ "GenSigCycleTime" SG_ 922 LAS_TLAStopLine_HostLane 100;
BA_ "GenSigStartValue" SG_ 922 LAS_TLAStopLine_HostLane 255;
BA_ "GenSigCycleTime" SG_ 922 LAS_TLADistance_HostLane 100;
BA_ "GenSigStartValue" SG_ 922 LAS_TLADistance_HostLane 255;
BA_ "GenSigCycleTime" SG_ 922 LAS_TLACountDownTime_HostLane 100;
BA_ "GenSigCycleTime" SG_ 922 LAS_TSRMandatorySign 100;
BA_ "GenSigCycleTime" SG_ 922 LAS_TSRWarningSign 100;
BA_ "GenSigCycleTime" SG_ 922 LAS_TSRProhibitionSign 100;
BA_ "GenSigCycleTime" SG_ 922 LAS_CRCCheck_332 100;
BA_ "GenSigCycleTime" SG_ 922 LAS_RollingCounter_332 100;
BA_ "GenSigCycleTime" SG_ 922 LAS_OverspeedSoundWarningEnSt 100;
BA_ "GenSigCycleTime" SG_ 922 LAS_TSREnable 100;
BA_ "GenSigCycleTime" SG_ 922 LAS_HMAEnableStatus 100;
BA_ "GenSigCycleTime" SG_ 922 LAS_HMALightDistribution 100;
BA_ "GenSigCycleTime" SG_ 922 LAS_HMAStatus 100;
BA_ "GenSigInvalidValue" SG_ 922 LAS_HMAStatus "3";
BA_ "GenSigCycleTime" SG_ 922 LAS_TSRHostSpdLimitUnits 100;
BA_ "GenSigInvalidValue" SG_ 922 LAS_TSRHostSpdLimitUnits "0";
BA_ "GenSigCycleTime" SG_ 922 LAS_TSRHostSpdLimit 100;
BA_ "GenSigInvalidValue" SG_ 922 LAS_TSRHostSpdLimit "254";
BA_ "GenSigCycleTime" SG_ 922 LAS_TSRStatus 100;
BA_ "GenSigInvalidValue" SG_ 922 LAS_TSRStatus "7";
BA_ "GenSigCycleTime" SG_ 922 LAS_FrontCameraCalibrationStatus 100;
BA_ "GenSigInvalidValue" SG_ 922 LAS_FrontCameraCalibrationStatus "3";
BA_ "GenSigCycleTime" SG_ 922 LAS_FrontCameraFailureStatus 100;
BA_ "GenSigInvalidValue" SG_ 922 LAS_FrontCameraFailureStatus "3";
BA_ "GenSigCycleTime" SG_ 922 LAS_OverspeedWarningOffset 100;
BA_ "GenSigStartValue" SG_ 922 LAS_OverspeedWarningOffset 10;
BA_ "GenSigCycleTime" SG_ 922 LAS_OverspeedWarningEnableStatus 100;
BA_ "GenSigCycleTime" SG_ 922 LAS_OverspeedSoundWarning 100;
BA_ "GenSigCycleTime" SG_ 922 LAS_OverspeedVisualWarning 100;
BA_ "GenSigCycleTime" SG_ 922 LAS_RoadSignCenterLatRange_Rlane 100;
BA_ "GenSigCycleTime" SG_ 922 LAS_RoadSignCenterLngRange_RLane 100;
BA_ "GenSigCycleTime" SG_ 922 LAS_RoadSignCenterLatRange_LLane 100;
BA_ "GenSigCycleTime" SG_ 922 LAS_RoadSignCenterLngRange_LLane 100;
BA_ "GenSigCycleTime" SG_ 922 LAS_RoadSignCenterLatRange_HLane 100;
BA_ "GenSigCycleTime" SG_ 922 LAS_RoadSignCenterLngRange_HLane 100;
BA_ "GenSigCycleTime" SG_ 922 LAS_CrosswalkLngRange_HLane 100;
BA_ "GenSigStartValue" SG_ 922 LAS_CrosswalkLngRange_HLane 255;
BA_ "GenSigCycleTime" SG_ 922 LAS_RoadSignType_RLane 100;
BA_ "GenSigCycleTime" SG_ 922 LAS_RoadSignType_LLane 100;
BA_ "GenSigCycleTime" SG_ 922 LAS_RoadSignType_HLane 100;
BA_ "GenSigCycleTime" SG_ 922 LAS_CRCCheck_37D 100;
BA_ "GenSigCycleTime" SG_ 922 LAS_RollingCounter_37D 100;
BA_ "GenSigCycleTime" SG_ 922 LAS_TLAArrowDirection_RightLane 100;
BA_ "GenSigCycleTime" SG_ 922 LAS_TLAObjectType_RightLane 100;
BA_ "GenSigCycleTime" SG_ 922 LAS_TLAObjectStatus_RightLane 100;
BA_ "GenSigCycleTime" SG_ 922 LAS_TLAObjectColour_RightLane 100;
BA_ "GenSigCycleTime" SG_ 922 LAS_TLAObjectDetection_RightLane 100;
BA_ "GenSigCycleTime" SG_ 922 LAS_TLAArrowDirection_LeftLane 100;
BA_ "GenSigCycleTime" SG_ 922 LAS_TLAObjectType_LeftLane 100;
BA_ "GenSigCycleTime" SG_ 922 LAS_TLAObjectStatus_LeftLane 100;
BA_ "GenSigCycleTime" SG_ 922 LAS_TLAObjectColour_LeftLane 100;
BA_ "GenSigCycleTime" SG_ 922 LAS_TLAObjectDetection_LeftLane 100;
BA_ "GenSigCycleTime" SG_ 922 LAS_TLAArrowDirection_HostLane 100;
BA_ "GenSigCycleTime" SG_ 922 LAS_TLAObjectStatus_HostLane 100;
BA_ "GenSigCycleTime" SG_ 922 LAS_TLAObjectType_HostLane 100;
BA_ "GenSigCycleTime" SG_ 922 LAS_TLAObjectColour_HostLane 100;
BA_ "GenSigCycleTime" SG_ 922 LAS_TLAObjectDetection_HostLane 100;
BA_ "GenSigCycleTime" SG_ 922 LAS_TLAWarninglevel 100;
BA_ "GenSigCycleTime" SG_ 922 LAS_TLAStatus 100;
BA_ "GenSigInvalidValue" SG_ 922 LAS_TLAStatus "3";
BA_ "GenSigCycleTime" SG_ 922 LAS_TLAEnable 100;
BA_ "GenSigCycleTime" SG_ 853 EMS_CRCCheck_355 100;
BA_ "GenSigCycleTime" SG_ 853 EMS_RollingCounter_355 100;
BA_ "GenSigCycleTime" SG_ 853 EMS_CruiseDistance 100;
BA_ "GenSigInvalidValue" SG_ 853 EMS_CruiseDistance "0";
BA_ "GenSigCycleTime" SG_ 853 EMS_CruiseSwitchSET 100;
BA_ "GenSigInvalidValue" SG_ 853 EMS_CruiseSwitchSET "0";
BA_ "GenSigCycleTime" SG_ 853 EMS_CruiseSwitchCANCEL 100;
BA_ "GenSigInvalidValue" SG_ 853 EMS_CruiseSwitchCANCEL "0";
BA_ "GenSigCycleTime" SG_ 853 EMS_CruiseSwitchResume 100;
BA_ "GenSigInvalidValue" SG_ 853 EMS_CruiseSwitchResume "0";
BA_ "GenSigCycleTime" SG_ 853 EMS_CruiseSwitchOnOff 100;
BA_ "GenSigInvalidValue" SG_ 853 EMS_CruiseSwitchOnOff "0";
BA_ "GenSigCycleTime" SG_ 941 DVR_SdcardErrorStatus 100;
BA_ "GenSigCycleTime" SG_ 943 HU_LaneConfluenceDis 100;
BA_ "GenSigInvalidValue" SG_ 943 HU_LaneConfluenceDis "63";
BA_ "GenSigStartValue" SG_ 943 HU_LaneConfluenceDis 63;
BA_ "GenSigCycleTime" SG_ 943 HU_LaneConfluence 100;
BA_ "GenSigInvalidValue" SG_ 943 HU_LaneConfluence "3";
BA_ "GenSigCycleTime" SG_ 943 HU_CRCCheck_3AF 100;
BA_ "GenSigCycleTime" SG_ 943 HU_RollingCounter_3AF 100;
BA_ "GenSigCycleTime" SG_ 943 HU_RampDistance 100;
BA_ "GenSigInvalidValue" SG_ 943 HU_RampDistance "1023";
BA_ "GenSigStartValue" SG_ 943 HU_RampDistance 1023;
BA_ "GenSigCycleTime" SG_ 943 HU_NavSpeedLimitType 100;
BA_ "GenSigInvalidValue" SG_ 943 HU_NavSpeedLimitType "0";
BA_ "GenSigCycleTime" SG_ 943 HU_CurveDistance 100;
BA_ "GenSigInvalidValue" SG_ 943 HU_CurveDistance "63";
BA_ "GenSigStartValue" SG_ 943 HU_CurveDistance 63;
BA_ "GenSigCycleTime" SG_ 943 HU_EnterCurveInfo 100;
BA_ "GenSigInvalidValue" SG_ 943 HU_EnterCurveInfo "0";
BA_ "GenSigCycleTime" SG_ 943 HU_NavCurrentRoadType 100;
BA_ "GenSigInvalidValue" SG_ 943 HU_NavCurrentRoadType "0";
BA_ "GenSigCycleTime" SG_ 943 HU_EnterRampInfo 100;
BA_ "GenSigInvalidValue" SG_ 943 HU_EnterRampInfo "0";
BA_ "GenSigCycleTime" SG_ 943 HU_RampInfo 100;
BA_ "GenSigInvalidValue" SG_ 943 HU_RampInfo "0";
BA_ "GenSigCycleTime" SG_ 943 HU_NavCountryCode 100;
BA_ "GenSigInvalidValue" SG_ 943 HU_NavCountryCode "0";
BA_ "GenSigCycleTime" SG_ 943 HU_NavStatus 100;
BA_ "GenSigInvalidValue" SG_ 943 HU_NavStatus "1";
BA_ "GenSigCycleTime" SG_ 943 HU_NavSpeedLimitUnits 100;
BA_ "GenSigInvalidValue" SG_ 943 HU_NavSpeedLimitUnits "0";
BA_ "GenSigCycleTime" SG_ 943 HU_NavSpeedLimitStatus 100;
BA_ "GenSigInvalidValue" SG_ 943 HU_NavSpeedLimitStatus "1";
BA_ "GenSigCycleTime" SG_ 943 HU_NavSpeedLimit 100;
BA_ "GenSigInvalidValue" SG_ 943 HU_NavSpeedLimit "255";
BA_ "GenSigStartValue" SG_ 943 HU_NavSpeedLimit 254;
BA_ "GenSigCycleTime" SG_ 943 HU_CRCCheck_3BB 100;
BA_ "GenSigCycleTime" SG_ 943 HU_RollingCounter_3BB 100;
BA_ "GenSigCycleTime" SG_ 943 HU_SlopeGradientFar 100;
BA_ "GenSigInvalidValue" SG_ 943 HU_SlopeGradientFar "1023";
BA_ "GenSigStartValue" SG_ 943 HU_SlopeGradientFar 1023;
BA_ "GenSigCycleTime" SG_ 943 HU_SlopeGradient 100;
BA_ "GenSigInvalidValue" SG_ 943 HU_SlopeGradient "1023";
BA_ "GenSigStartValue" SG_ 943 HU_SlopeGradient 1023;
BA_ "GenSigCycleTime" SG_ 943 HU_SpeedLimitDistance 100;
BA_ "GenSigInvalidValue" SG_ 943 HU_SpeedLimitDistance "63";
BA_ "GenSigStartValue" SG_ 943 HU_SpeedLimitDistance 63;
BA_ "GenSigCycleTime" SG_ 957 HU_CSLAEnable 100;
BA_ "GenSigInvalidValue" SG_ 957 HU_CSLAEnable "3";
BA_ "GenSigStartValue" SG_ 957 HU_CSLAEnable 3;
BA_ "GenSigCycleTime" SG_ 957 HU_ELKEnable 100;
BA_ "GenSigInvalidValue" SG_ 957 HU_ELKEnable "0";
BA_ "GenSigCycleTime" SG_ 957 HU_TLAEnable 100;
BA_ "GenSigInvalidValue" SG_ 957 HU_TLAEnable "0";
BA_ "GenSigCycleTime" SG_ 964 HU_CRCCheck_3C7 100;
BA_ "GenSigCycleTime" SG_ 964 HU_RollingCounter_3C7 100;
BA_ "GenSigCycleTime" SG_ 964 HU_CRCCheck_3C6 100;
BA_ "GenSigCycleTime" SG_ 964 HU_RollingCounter_3C6 100;
BA_ "GenSigCycleTime" SG_ 964 HU_CRCCheck_3C4 100;
BA_ "GenSigCycleTime" SG_ 964 HU_RollingCounter_3C4 100;
BA_ "GenSigCycleTime" SG_ 964 HU_CRCCheck_3C2 100;
BA_ "GenSigCycleTime" SG_ 964 HU_RollingCounter_3C2 100;
BA_ "GenSigCycleTime" SG_ 964 HU_MapMatchStatus 100;
BA_ "GenSigInvalidValue" SG_ 964 HU_MapMatchStatus "3";
BA_ "GenSigCycleTime" SG_ 964 HU_MapDataUpdateStatus 100;
BA_ "GenSigInvalidValue" SG_ 964 HU_MapDataUpdateStatus "7";
BA_ "GenSigCycleTime" SG_ 964 HU_SlopeGradient_300m 100;
BA_ "GenSigInvalidValue" SG_ 964 HU_SlopeGradient_300m "1023";
BA_ "GenSigStartValue" SG_ 964 HU_SlopeGradient_300m 1023;
BA_ "GenSigCycleTime" SG_ 964 HU_RoadCurvature_600m 100;
BA_ "GenSigInvalidValue" SG_ 964 HU_RoadCurvature_600m "1023";
BA_ "GenSigStartValue" SG_ 964 HU_RoadCurvature_600m 511;
BA_ "GenSigCycleTime" SG_ 964 HU_RoadCurvature_400m 100;
BA_ "GenSigInvalidValue" SG_ 964 HU_RoadCurvature_400m "1023";
BA_ "GenSigStartValue" SG_ 964 HU_RoadCurvature_400m 511;
BA_ "GenSigCycleTime" SG_ 964 HU_RoadCurvature_300m 100;
BA_ "GenSigInvalidValue" SG_ 964 HU_RoadCurvature_300m "1023";
BA_ "GenSigStartValue" SG_ 964 HU_RoadCurvature_300m 511;
BA_ "GenSigCycleTime" SG_ 964 HU_RoadCurvature_100m 100;
BA_ "GenSigInvalidValue" SG_ 964 HU_RoadCurvature_100m "1023";
BA_ "GenSigStartValue" SG_ 964 HU_RoadCurvature_100m 511;
BA_ "GenSigCycleTime" SG_ 964 HU_RoadCurvature_90m 100;
BA_ "GenSigInvalidValue" SG_ 964 HU_RoadCurvature_90m "1023";
BA_ "GenSigStartValue" SG_ 964 HU_RoadCurvature_90m 511;
BA_ "GenSigCycleTime" SG_ 964 HU_RoadCurvature_80m 100;
BA_ "GenSigInvalidValue" SG_ 964 HU_RoadCurvature_80m "1023";
BA_ "GenSigStartValue" SG_ 964 HU_RoadCurvature_80m 511;
BA_ "GenSigCycleTime" SG_ 964 HU_RoadCurvature_70m 100;
BA_ "GenSigInvalidValue" SG_ 964 HU_RoadCurvature_70m "1023";
BA_ "GenSigStartValue" SG_ 964 HU_RoadCurvature_70m 511;
BA_ "GenSigCycleTime" SG_ 964 HU_RoadCurvature_60m 100;
BA_ "GenSigInvalidValue" SG_ 964 HU_RoadCurvature_60m "1023";
BA_ "GenSigStartValue" SG_ 964 HU_RoadCurvature_60m 511;
BA_ "GenSigCycleTime" SG_ 964 HU_RoadCurvature_50m 100;
BA_ "GenSigInvalidValue" SG_ 964 HU_RoadCurvature_50m "1023";
BA_ "GenSigStartValue" SG_ 964 HU_RoadCurvature_50m 511;
BA_ "GenSigCycleTime" SG_ 964 HU_RoadCurvature_40m 100;
BA_ "GenSigInvalidValue" SG_ 964 HU_RoadCurvature_40m "1023";
BA_ "GenSigStartValue" SG_ 964 HU_RoadCurvature_40m 511;
BA_ "GenSigCycleTime" SG_ 964 HU_RoadCurvature_30m 100;
BA_ "GenSigInvalidValue" SG_ 964 HU_RoadCurvature_30m "1023";
BA_ "GenSigStartValue" SG_ 964 HU_RoadCurvature_30m 511;
BA_ "GenSigCycleTime" SG_ 964 HU_RoadCurvature_20m 100;
BA_ "GenSigInvalidValue" SG_ 964 HU_RoadCurvature_20m "1023";
BA_ "GenSigStartValue" SG_ 964 HU_RoadCurvature_20m 511;
BA_ "GenSigCycleTime" SG_ 964 HU_RoadCurvature_10m 100;
BA_ "GenSigInvalidValue" SG_ 964 HU_RoadCurvature_10m "1023";
BA_ "GenSigStartValue" SG_ 964 HU_RoadCurvature_10m 511;
BA_ "GenSigCycleTime" SG_ 964 HU_Road_TrafficFlow 100;
BA_ "GenSigInvalidValue" SG_ 964 HU_Road_TrafficFlow "7";
BA_ "GenSigCycleTime" SG_ 964 HU_Lane_Changtype 100;
BA_ "GenSigInvalidValue" SG_ 964 HU_Lane_Changtype "3";
BA_ "GenSigStartValue" SG_ 964 HU_Lane_Changtype 3;
BA_ "GenSigCycleTime" SG_ 964 HU_To_NumchangeOfLanes_Dist 100;
BA_ "GenSigInvalidValue" SG_ 964 HU_To_NumchangeOfLanes_Dist "63";
BA_ "GenSigStartValue" SG_ 964 HU_To_NumchangeOfLanes_Dist 63;
BA_ "GenSigCycleTime" SG_ 964 HU_To_Branch_Dis 100;
BA_ "GenSigInvalidValue" SG_ 964 HU_To_Branch_Dis "63";
BA_ "GenSigStartValue" SG_ 964 HU_To_Branch_Dis 63;
BA_ "GenSigCycleTime" SG_ 964 HU_BranchInfo 100;
BA_ "GenSigInvalidValue" SG_ 964 HU_BranchInfo "0";
BA_ "GenSigCycleTime" SG_ 964 HU_To_TrafficAccident_Dis 100;
BA_ "GenSigInvalidValue" SG_ 964 HU_To_TrafficAccident_Dis "63";
BA_ "GenSigStartValue" SG_ 964 HU_To_TrafficAccident_Dis 63;
BA_ "GenSigCycleTime" SG_ 964 HU_TrafficAccident_Info 100;
BA_ "GenSigInvalidValue" SG_ 964 HU_TrafficAccident_Info "3";
BA_ "GenSigStartValue" SG_ 964 HU_TrafficAccident_Info 3;
BA_ "GenSigCycleTime" SG_ 964 HU_To_Construction_Dis 100;
BA_ "GenSigInvalidValue" SG_ 964 HU_To_Construction_Dis "63";
BA_ "GenSigStartValue" SG_ 964 HU_To_Construction_Dis 63;
BA_ "GenSigCycleTime" SG_ 964 HU_Construction_Info 100;
BA_ "GenSigInvalidValue" SG_ 964 HU_Construction_Info "3";
BA_ "GenSigStartValue" SG_ 964 HU_Construction_Info 3;
BA_ "GenSigCycleTime" SG_ 964 HU_TollDis 100;
BA_ "GenSigInvalidValue" SG_ 964 HU_TollDis "63";
BA_ "GenSigStartValue" SG_ 964 HU_TollDis 63;
BA_ "GenSigCycleTime" SG_ 964 HU_TollInfo 100;
BA_ "GenSigInvalidValue" SG_ 964 HU_TollInfo "3";
BA_ "GenSigStartValue" SG_ 964 HU_TollInfo 3;
BA_ "GenSigCycleTime" SG_ 964 HU_FallingRockDi 100;
BA_ "GenSigInvalidValue" SG_ 964 HU_FallingRockDi "63";
BA_ "GenSigStartValue" SG_ 964 HU_FallingRockDi 63;
BA_ "GenSigCycleTime" SG_ 964 HU_FallingRockInfo 100;
BA_ "GenSigInvalidValue" SG_ 964 HU_FallingRockInfo "3";
BA_ "GenSigStartValue" SG_ 964 HU_FallingRockInfo 3;
BA_ "GenSigCycleTime" SG_ 964 HU_LaneCnt 100;
BA_ "GenSigInvalidValue" SG_ 964 HU_LaneCnt "0";
BA_ "GenSigCycleTime" SG_ 964 HU_ForwardRoadType 100;
BA_ "GenSigInvalidValue" SG_ 964 HU_ForwardRoadType "0";
BA_ "GenSigCycleTime" SG_ 964 HU_RampSide 100;
BA_ "GenSigInvalidValue" SG_ 964 HU_RampSide "0";
BA_ "GenSigCycleTime" SG_ 964 HU_CRCCheck_3B8 100;
BA_ "GenSigCycleTime" SG_ 964 HU_RollingCounter_3B8 100;
BA_ "GenSigCycleTime" SG_ 964 HU_NavGuiganceStatus 100;
BA_ "GenSigInvalidValue" SG_ 964 HU_NavGuiganceStatus "3";
BA_ "GenSigCycleTime" SG_ 964 HU_SlopeDistance 100;
BA_ "GenSigInvalidValue" SG_ 964 HU_SlopeDistance "63";
BA_ "GenSigStartValue" SG_ 964 HU_SlopeDistance 63;
BA_ "GenSigCycleTime" SG_ 964 HU_Byroad 100;
BA_ "GenSigInvalidValue" SG_ 964 HU_Byroad "3";
BA_ "GenSigCycleTime" SG_ 964 HU_TunnelLength 100;
BA_ "GenSigInvalidValue" SG_ 964 HU_TunnelLength "63";
BA_ "GenSigStartValue" SG_ 964 HU_TunnelLength 63;
BA_ "GenSigCycleTime" SG_ 964 HU_RoadCurvatureFar 100;
BA_ "GenSigInvalidValue" SG_ 964 HU_RoadCurvatureFar "1023";
BA_ "GenSigStartValue" SG_ 964 HU_RoadCurvatureFar 511;
BA_ "GenSigCycleTime" SG_ 964 HU_TunnelDistance 100;
BA_ "GenSigInvalidValue" SG_ 964 HU_TunnelDistance "63";
BA_ "GenSigStartValue" SG_ 964 HU_TunnelDistance 63;
BA_ "GenSigCycleTime" SG_ 964 HU_RoadCurvature 100;
BA_ "GenSigInvalidValue" SG_ 964 HU_RoadCurvature "1023";
BA_ "GenSigStartValue" SG_ 964 HU_RoadCurvature 511;
BA_ "GenSigCycleTime" SG_ 964 HU_EnterSlopeInfo 100;
BA_ "GenSigInvalidValue" SG_ 964 HU_EnterSlopeInfo "0";
BA_ "GenSigCycleTime" SG_ 964 HU_EnterTunnelInfo 100;
BA_ "GenSigInvalidValue" SG_ 964 HU_EnterTunnelInfo "0";
VAL_ 368 EPS_fault_state 0 "No Fault" 1 "Thermal Protection Fault " 2 "Power Limit Fault   " 3 "IMC Result error" 4 "Torque Sensor Fault(recoverable with assist)" 5 "Angle Sensor Fault(recoverable with assist)" 6 "Sensorless Angle Fault(Non recoverable without assist)" 7 "Power Supply Fault(Non recoverable)" 8 "Motor Sensor Fault(Non recoverable)" 9 "Flash/RAM/NVM Fault(Non recoverable)" 10 "Battery Voltage Fault(Recoverable)" 11 "ECU ID Fault(Non recoverable)" 12 "Other Fault(Non recoverable)" ;
VAL_ 368 EPS_ActualTorsionBarTorq 2047 "" ;
VAL_ 368 EPS_MinSafetyTorsionBarTorq 2047 "" ;
VAL_ 368 EPS_MaxSafetyTorsionBarTorq 2047 "" ;
VAL_ 392 TCU_ShiftinProgressValid 0 "Valid" 1 "Invalid" ;
VAL_ 392 TCU_ShiftinProgress 0 "Noshift" 1 "Shift" ;
VAL_ 580 ADS_EOMTOReq 0 "无请求" 1 "1级接管请求" 2 "2级接管请求" 3 "3级接管请求" ;
VAL_ 580 ACC_HandsOnReq 0 "no request" 1 "level 1 request" 2 "level 2 request" 3 "level 3 request" 4 "level 4 request" 5 "reserved" ;
VAL_ 580 ACC_DynamicWarningLevel 0 "no request" 1 "level 1 request" 2 "level 2 request" 3 "level 3 request" 4 "reserved" ;
VAL_ 580 ACC_SafetyNotice 0 "无信息" 1 "道路天气环境较差" 2 "前方道路变化" 3 "超出坡度或曲率范围" 4 "前方交通事故" 5 "前方道路施工" 6 "前方经过环岛" 7 "前方经过服务区" 8 "前方经过隧道" 9 "前方经过匝道" 10 "超出电子围栏或无法定位" 11 "道路颠簸" 12 "前方存在行人" 13 "脱眼报警" 14 "未检测到头部" 15 "请手握方向盘，注意前方路况" 16 "道路天气环境较差，请手握方向盘" 17 "前方道路变化，请手握方向盘" 18 "超出坡度或曲率范围，请手握方向盘" 19 "前方交通事故，请手握方向盘" 20 "前方道路施工，请手握方向盘" 21 "前方经过环岛，请手握方向盘" 22 "前方经过服务区，请手握方向盘" 23 "前方经过隧道，请手握方向盘" 24 "前方经过匝道，请手握方向盘" 25 "超出电子围栏或无法定位，请手握方向盘" 26 "道路颠簸，请手握方向盘" 27 "前方存在行人，请手握方向盘" 28 "系统异常，请手握方向盘" 29 "油门超越，请手握方向盘" 30 "请保持ESP功能开启" 31 "请保持挡位为D挡或S挡" 32 "请求系好安全带" 33 "雨刮故障，请立即接管" 34 "灯光故障，请立即接管" 35 "动力系统异常，请立即接管" 36 "传感系统异常，请立即接管" 37 "转向系统异常，请立即接管" 38 "制动系统异常，请立即接管" 39 "交互系统异常，请立即接管" 40 "驻车系统异常，请立即接管" 41 "系统异常，请立即接管" 42 "胎压异常，请立即接管" 43 "胎温异常，请立即接管" 44 "数据记录异常，请立即接管" 45 "道路天气环境较差，请立即接管" 46 "超出坡度或曲率范围，请立即接管" 47 "前方道路施工，请立即接管" 48 "道路颠簸，请立即接管" 49 "道路湿滑，请立即接管" 50 "危险目标，请立即接管" 51 "前方存在行人，请立即接管" 52 "请求系好安全带，并立即接管" 53 "（接管报警中）油门超越，请手握方向盘，注意前方路况" 54 "即将在本车道停车，请立即接管" 55 "即将靠边停车，请立即接管" 56 "正在停车，请立即接管" 57 "停车已完成，请立即接管" ;
VAL_ 580 ACC_LatTakeoverReq 0 "no request" 1 "level 1 request" 2 "level 2 request" 3 "reserved" ;
VAL_ 580 ACC_LngTakeOverReq 0 "no request" 1 "level 1 request" 2 "level 2 request" 3 "reserved" ;
VAL_ 580 ACC_TakeOverReq 0 "无请求" 1 "1级接管请求" 2 "2级接管请求" 3 "3级接管请求" ;
VAL_ 580 ACC_ADCNotice 1 "ACC:ACC is OFF" 2 "ACC:ACC system error" 3 "ACC:ACC Error by EMS/VCU/TCU" 4 "ACC:ACC Error by EPBi" 5 "ACC:SAS Error" 6 "ACC:Button Error" 7 "ACC:IP Fail" 8 "ACC:ACC temporary unavailable by others" 9 "ACC:ACC error by Front Camera" 10 "ACC:ACC error by Front Radar" 11 "ACC:Engine No Running" 12 "ACC:door is open" 13 "ACC:bonnet is Open" 14 "ACC:Trunk is Open" 15 "ACC:Tire Status is abnormal" 16 "ACC:Bad weather" 17 "ACC:Seatbelt unbuckled" 18 "ACC:ESP off" 19 "ACC:No forward gear" 20 "ACC:APA  is on" 21 "ACC:EPB activate" 22 "ACC:ACC cannot active by snow mode" 23 "ACC:SteeringAngle is over" 24 "ACC:brake pedal is applied" 25 "ACC:Speed over 150kph" 26 "ACC:caution about driving safty" 27 "ACC:Road wet and slippery" 28 "ACC:Road bumpy" 29 "ACC:Have Pedestrain or Riders" 30 "ACC:Out of slope or curvature range " 31 "ACC:ACC active control is cancelled" 32 "ACC:ACC cannot active by Race mode" 33 "ACC:ACC unintended exit warning" 34 "ACC:emergency brake suddenly" 35 "ACC:speed reduce by condition" 36 "ACC:speed reduce by ramp" 37 "ACC:speed reduce by SpdLimited" 38 "ACC:speed reduce by Tollstation" 39 "ACC:speed reduce by tunnel" 40 "ACC:unable to activate ACC" 41 "ACC:车辆起步提醒（前车驶离）" 42 "ACC:激活成功提醒" 43 "ACC:前方红绿灯-智能限速" 44 "ACC:前方人行横道-请注意减速慢行" 45 "ACC:前方人行横道-智能限速" 46 "ACC:前方收费站-请注意减速慢行" 47 "ACC:前方收费站-智能限速" 48 "ACC:前方弯道-智能限速" 49 "ACC:前雷达不可用-ACC退出" 50 "ACC:前摄像头不可用-ACC退出" 51 "ACC:推荐调节巡航车速-避让并行车辆" 52 "ACC:巡航驻车提醒" 53 "ACC:雨天道路湿滑-自动增加跟车时距" 54 "ACC:智能加速避让并行车辆" 55 "ACC:智能减速避让并行车辆" 56 "ACC:主动提速提醒" 57 "ACC:主动退出提醒（稍强）" 58 "ACC:自适应巡航已恢复" 59 "ACC:操作反馈-设定车速达到上限
0x3C=ACC:操作反馈-设定车速达到下限
0x3D=ACC:操作反馈-设定车速达到限速值
0x3E=ACC:操作反馈-超速接近纵向控制极限，即将退出
0x3F-0x64预留" 101 "IACC:IACC not available by EPS" 102 "IACC:longitudinal control not available" 103 "IACC:ADR/DVR Status not Match" 104 "IACC:other system error" 105 "IACC:prohibition request for safestop" 106 "IACC:Please turn on IACC in incall " 107 "IACC:Driver Drowsy or Distracted" 108 "IACC:SteeringAngle is over" 109 "IACC:exceed speed limit" 110 "IACC:turn light switch on" 111 "IACC:turn light switch on" 112 "IACC:driver overrides steering" 113 "IACC:caution about driving safty" 114 "IACC:unable to active for not in lane/crossing lane" 115 "IACC:lane condition not available" 116 "IACC:unable to active in curve" 117 "IACC:unable to active in Bad weather" 118 "IACC:system error" 119 "IACC:LKA Takeover Req" 120 "IACC:ELK active" 121 "IACC:HeadingAngle is over" 122 "IACC:LAT invalid" 123 "IACC:LAT invalid（in safety stargy)" 124 "IACC:Hands on plz" 125 "IACC:IACC active" 126 "IACC:IACC Cancel" 127 "IACC:IACC deactivate" 128 "IACC:iacc override" 129 "IACC:IACC unintended exit" 130 "IACC:Lights on please" 131 "IACC:Longitude Exit" 132 "IACC:Prohibition request for rdf" 133 "IACC:takeover request with safety stop completed" 134 "IACC:takeover request with safety stoping" 135 "IACC:unable to activate IACC" 136 "IACC:未认证用户使用智能驾驶功能提醒
0x89=IACC:超速接近横向控制的极限即将退出
0x8A=IACC:车辆临时靠左行驶，避让并行车辆
0x8B=IACC:车辆临时靠右行驶，避让并行车辆
0x8C=IACC:车辆临时靠左行驶，避让护栏
0x8D=IACC:车辆临时靠右行驶，避让护栏
0x8E-0xC8预留" 201 "UDLC:UDLC exit，触发式换道已退出，（UDLC不再等待换道并且不再主导控制）" 202 "UDLC:UDLC return，触发式换道回退原车道（驾驶员取消换道而回退）" 203 "UDLC:UDLC finished，请拨回转向灯（换道完成或回退对中完成时）" 204 "UDLC:前方道路汇流，推荐换道行驶" 205 "UDLC:change lane  to both sides for the  traffic jam,两边车道均可支持变道" 206 "UDLC:Lane change request by ramp" 207 "UDLC:change lane  to left side for the  traffic jam,左边车道可支持变道" 208 "UDLC:change lane  to right side for the  traffic jam,右边车道可支持变道" 209 "UDLC:out of ODD暂时不满足换道条件，不尝试换道" 210 "UDLC:Please turn on the UDLC in HU请在主机中打开主动换道设置开关" 211 "UDLC:speed out of range车速超出范围，自动换道条件不满足" 212 "UDLC:UDLC System Error自动换道系统故障" 213 "UDLC:雨量过大，自动换道条件不满足" 214 "UDLC:wait over time,换道尝试超时中止" 215 "UDLC:推荐向左换道-道路更畅通" 216 "UDLC:推荐向左换道-超越前车" 217 "UDLC:推荐向左换道-避让前方障碍物" 218 "UDLC:推荐向左换道-避让前方异常车辆" 219 "UDLC:推荐向左换道-道路前方有道路施工" 220 "UDLC:推荐向左换道-提前避让右侧汇入车辆" 221 "UDLC:推荐向左换道-避让右侧汇入车辆" 222 "UDLC:推荐向左换道-前方道路即将向左合并" 223 "UDLC:推荐向左换道-避让右侧大型车辆" 224 "UDLC:推荐向左换道-避让后方大型车辆" 225 "UDLC:推荐向右换道-道路更畅通" 226 "UDLC:推荐向右换道-超越前车" 227 "UDLC:推荐向右换道-道路前方有障碍物" 228 "UDLC:推荐向右换道-道路前方有异常车辆" 229 "UDLC:推荐向右换道-道路前方有道路施工" 230 "UDLC:推荐向右换道-提前避让左侧汇入车辆" 231 "UDLC:推荐向右换道-避让左侧汇入车辆" 232 "UDLC:推荐向右换道-前方道路即将向右合并" 233 "UDLC:推荐向右换道-避让左侧大型车辆" 234 "UDLC:推荐向右换道-避让后方大型车辆" 235 "UDLC:避让侧后方来车，返回原车道" 236 "UDLC:避让危险车辆，返回原车道" 237 "UDLC:避让行人，返回原车道" 238 "UDLC:避让障碍物，返回原车道" 239 "UDLC:非驾驶员操作通用原因，返回原车道" 240 "" 301 "ALC:LaneChangeToLeftForPathThroughRamp前方接近匝道，即将向左换道" 302 "ALC:LaneChangeToRightForPathThroughRamp前方接近匝道，即将向右换道" 303 "ALC:LaneChangeForQuickRoad,即将汇入主路" 304 "ALC:LaneChangeToLeft即将向左换道" 305 "ALC:LaneChangeToRight即将向右换道" 306 "ALC:LaneChangeToLeftForSurpassTheCar,即将向左超车" 307 "ALC:LaneChangeToRightForSurpassTheCar,即将向右超车" 308 "ALC:向左自动换道-道路更畅通" 309 "ALC:向左自动换道-超越前车" 310 "ALC:向左自动换道-避让前方障碍物" 311 "ALC:向左自动换道-避让前方异常车辆" 312 "ALC:向左自动换道-道路前方有道路施工" 313 "ALC:向左自动换道-提前避让右侧汇入车辆" 314 "ALC:向左自动换道-避让右侧汇入车辆" 315 "ALC:向左自动换道-前方道路即将向左合并" 316 "ALC:向左自动换道-避让右侧大型车辆" 317 "ALC:向左自动换道-避让后方大型车辆" 318 "ALC:向右自动换道-道路更畅通" 319 "ALC:向右自动换道-超越前车" 320 "ALC:向右自动换道-道路前方有障碍物" 321 "ALC:向右自动换道-道路前方有异常车辆" 322 "ALC:向右自动换道-道路前方有道路施工" 323 "ALC:向右自动换道-提前避让左侧汇入车辆" 324 "ALC:向右自动换道-避让左侧汇入车辆" 325 "ALC:向右自动换道-前方道路即将向右合并" 326 "ALC:向右自动换道-避让左侧大型车辆" 327 "ALC:向右自动换道-避让后方大型车辆" 328 "ALC:自动换道已取消（主动）" 329 "ALC:避让侧后方来车，取消自动换道" 330 "ALC:避让危险车辆，取消自动换道" 331 "ALC:避让行人，取消自动换道" 332 "ALC:避让障碍物，取消自动换道" 333 "ALC:非驾驶员操作通用原因，取消自动换道" 334 "" ;
VAL_ 580 ACC_RWU_Parking_Request_Valid 0 "Valid" 1 "Invalid" ;
VAL_ 580 ACC_RWU_Parking_Request 0 "no request" 1 "  request" ;
VAL_ 580 ACC_CDP_Parking_Request_Valid 0 "Valid" 1 "Invalid" ;
VAL_ 580 ACC_CDP_Parking_Request 0 "no request" 1 "  request" ;
VAL_ 580 ACC_LDWShakeLevStatus 0 "reserved" 1 "low" 2 "normal" 3 "high" ;
VAL_ 580 ACC_TextInfoForDriver 0 "no display" 1 "unable to activate ACC" 2 "ACC active control is cancelled" 3 "ACC error by Front Radar" 4 "ACC temporary unavailable by others" 5 "EPB activate" 6 "No forward gear" 7 "Seatbelt unbuckled" 8 "Engine No Running" 9 "ESP off" 10 "bonnet is Open" 11 "Speed over 150kph" 12 "ACC Error by EMS/VCU/TCU" 14 "ACC Error by EPBI" 15 "ACC unintended exit warning" 16 "door is open" 17 "brake pedal is applied" 18 "speed reduce by ramp" 19 "speed reduce by tunnel" 20 "ACC error by Front Camera" 21 "speed reduce by condition" 22 "speed reduce by SpdLimited" 23 "ACC cannot active by Race mode" 24 "speed reduce by Tollstation" 25 "ACC cannot active by snow mode" 26 "SteeringAngle is over" 27 "emergency brake suddenly" 28 "前雷达不可用，ACC退出" 29 "前摄像头不可用，ACC退出" 30 "Bad weather" 31 "设定车速达到上限" 32 "设定车速达到下限" 33 "设定车速达到限速值" ;
VAL_ 580 ACC_AEBCtrlType 0 "no request" 1 "AEB C&U（AEB车辆）" 2 "AEB VRU（AEB行人）" 3 "AEB Cyclist（AEB骑行者）" 4 "EBA（制动辅助）" 5 "FCTB（前向横向AEB）" 6 "RCTB(后向横向AEB)" 7 "Reserved" ;
VAL_ 580 ACC_FuelCutOffPrevention 0 "no request" 1 "request" ;
VAL_ 580 ACC_AccTrqReqActive 0 " not Active" 1 " Active." ;
VAL_ 580 ACC_AEBVehilceHoldReq 0 " No hold" 1 " hold" ;
VAL_ 580 ACC_FCWPreWarning 0 " no warning" 1 " warning" ;
VAL_ 580 ACC_FCWLatentWarning 0 " no warning" 1 " warning" ;
VAL_ 580 ACC_FCWActive 0 " not Active" 1 " Active" ;
VAL_ 580 ACC_PrefillActive 0 " not Active" 1 " Active" ;
VAL_ 580 ACC_AWBActive 0 " not Active" 1 " Active" ;
VAL_ 580 ACC_AWBlevel 0 "  no level" 1 "  level 1" 2 "  level 2" 3 "  level 3" 4 "  level 4" 5 " reserved" ;
VAL_ 580 ACC_ABAActive 0 " not Active" 1 " Active" ;
VAL_ 580 ACC_ABAlevel 0 " level 0" 1 "level 1" 2 " level 2" 3 " level 3" ;
VAL_ 580 ACC_AEBActive 0 " not Active" 1 " Active." ;
VAL_ 580 ACC_EmergencyDataRrdReq 0 "no request" 1 "Event 1 Request" 2 "Event 2 Request" 3 "Image Record" ;
VAL_ 580 ACC_Driveoff_Request 0 " No request" 1 " request" ;
VAL_ 580 ACC_ACCMode 0 "OFF mode" 1 "Passive mode" 2 "StandBy mode" 3 " Active Control mode" 4 " Brake Only mode" 5 " Override" 6 " Stand Wait mode" 7 " Failure mode" ;
VAL_ 580 ACC_CCMode 0 "OFF mode" 1 "Passive mode" 2 "Stand-By mode" 3 "Active-Control mode" 4 "Override" 5 "Reserved" 6 "Reserved" 7 "Failure mode" ;
VAL_ 580 ACC_CDDActive 0 " not active" 1 " Active" ;
VAL_ 580 ACC_LimitSwitchArbitration 0 "invalid" 1 "Off" 2 "On" 3 "reserved" ;
VAL_ 580 ACC_EngineStartStopRequest 0 "No request" 1 "EngineAutoStopRequest" 2 "EngineAutoStartRequest" 3 "reserved" ;
VAL_ 580 ACC_DecToStop 0 "no demand" 1 " demand" ;
VAL_ 580 ACC_TCUCreepProhibition 0 "no request" 1 "request" ;
VAL_ 580 ACC_LKAStatus 0 "Off" 1 "Standby" 2 "Active" 3 "Failure" ;
VAL_ 580 ACC_LDWVibrationWarningReq 0 " No Warning不报警" 1 " Left Warning左报警" 2 "Right Warning右报警" 3 " reserved" ;
VAL_ 580 ACC_LDWStatus 0 "Off" 1 "Standby" 2 "Active" 3 "Failure" ;
VAL_ 583 APA_APAOnOff 0 "OFF" 1 "ON" ;
VAL_ 664 BCM_DriverDoorLockStatus 0 "Lock" 1 "Unlock" 2 "Not used" 3 "Error" ;
VAL_ 664 BCM_LeftRearDoorStatus 0 "Close" 1 "Open" ;
VAL_ 775 AD_LatDeviationDis 0 "idle" 1 "0.1-0.5" 6 "Reserved" ;
VAL_ 775 AD_LatDeviationReason 0 "idle" 1 "靠近本车道目标" 2 "弯道" 3 "护栏" 4 "锥形筒" 5 "Reserved" 7 "其他原因" ;
VAL_ 775 AD_IACCSuspendReason 0 "idle" 1 "无控制信息（线、车、Freespace都不存在）" 2 "手拉方向盘" 3 "加速度过大" 4 "规划异常" 5 "转角或转速过大" 6 "Reserved" 7 "其他原因" ;
VAL_ 775 ACC_IACCProhibitionTime 0 " no prohibition" 1 " 0 ~ 99" 101 "Reserve" ;
VAL_ 775 ACC_RRLanecolor 0 "Not Detected" 1 "white" 2 "yellow" 3 "white plus yellow" 4 "unknown" 5 "reserved" 6 "reserved" 7 "Invalid" ;
VAL_ 775 ACC_RLanecolor 0 "Not Detected" 1 "white" 2 "yellow" 3 "white plus yellow" 4 "unknown" 5 "reserved" 6 "reserved" 7 "Invalid" ;
VAL_ 775 ACC_LLLanecolor 0 "Not Detected" 1 "white" 2 "yellow" 3 "white plus yellow" 4 "unknown" 5 "reserved" 6 "reserved" 7 "Invalid" ;
VAL_ 775 ACC_LLanecolor 0 "Not Detected" 1 "white" 2 "yellow" 3 "white plus yellow" 4 "unknown" 5 "reserved" 6 "reserved" 7 "Invalid" ;
VAL_ 775 ACC_VehicleStartRemindSts 0 "off" 1 "passive" 2 "standby" 3 "active" ;
VAL_ 775 ADS_ResetSts 0 "Valid" 1 "GW请求复位" 2 "自身判断复位" 3 "不满足复位条件" 4 "Reserve" 7 "Invalid" ;
VAL_ 775 ADS_IRLCEnable 0 "Inactive" 1 "OFF" 2 "ON" 3 "Reserved" ;
VAL_ 775 ADS_AutoDriveState 0 "OFF" 1 "ACC" 2 "IACC" 3 "HWA" 4 "TJP" 5 "reserved" ;
VAL_ 775 ACC_CSLAEnableStatus 0 "OFF" 1 "All Speed-Limit" 2 "Road Camera" 3 "invalid" ;
VAL_ 775 ACC_CSLSetReq 0 "no request" 1 "request" ;
VAL_ 775 ACC_HostPotentialTargetDirection 0 "Forward" 1 "OnComing" 2 "Left" 3 "Right" 4 "unknown" 5 "no display" 6 "reserved" ;
VAL_ 775 ACC_HostPotentialTargetType 0 "no display" 1 "sedan" 2 "motorcycle" 3 "pedestrian" 4 "Bicycle" 5 "Bus" 6 "van" 7 "truck" 8 "reserved" 15 "other" ;
VAL_ 775 ACC_HostPotentialTargetLatRange 0 "-50-50m" 1001 "reserved" ;
VAL_ 775 ACC_HostPotentialTargetLngRange 0 "-70~180" 501 "reserved" 511 "no display" ;
VAL_ 775 ACC_HostPotentialTargetDetection 0 "not dectected" 1 "IP display" 2 "Front target" 3 "IACC target" 4 "AEB target" 5 "dangerous target（ELK、UDLC、RCW, etc）" 6 "reserved" ;
VAL_ 775 ACC_FLTarget2Type 0 "no display" 1 "sedan" 2 "motorcycle" 3 "pedestrian" 4 "Bicycle" 5 "Bus" 6 "van" 7 "truck" 8 "reserved" 15 "other" ;
VAL_ 775 ACC_FLTarget2LngRange 0 "-70~180" 501 "reserved" 511 "no display" ;
VAL_ 775 ACC_FLTarget2Detection 0 "not dectected" 1 "IP display" 2 "Front Target" 3 "IACC target" 4 "AEB target" 5 "dangerous target（ELK、UDLC、RCW, etc）" 6 "reserved" ;
VAL_ 775 ACC_FLTarget2Direction 0 "Forward" 1 "OnComing" 2 "Left" 3 "Right" 4 "unknown" 5 "no display" 6 "reserved" ;
VAL_ 775 ACC_FLTarget1Direction 0 "Forward" 1 "OnComing" 2 "Left" 3 "Right" 4 "unknown" 5 "no display" 6 "reserved" ;
VAL_ 775 ACC_FLTarget1Type 0 "no display" 1 "sedan" 2 "motorcycle" 3 "pedestrian" 4 "Bicycle" 5 "Bus" 6 "van" 7 "truck" 8 "reserved" 15 "other" ;
VAL_ 775 ACC_FLTarget1LatRange 0 "" 1001 "" ;
VAL_ 775 ACC_FLTarget1LngRange 0 "-70~180" 501 "reserved" 511 "no display" ;
VAL_ 775 ACC_FLTarget1Detection 0 "not dectected" 1 "IP display" 2 "Front Target" 3 "IACC target" 4 "AEB target" 5 "dangerous target（ELK、UDLC、RCW, etc）" 6 "reserved" ;
VAL_ 775 ACC_HostTargetDetection 0 "not dectected" 1 "IP display" 2 "Front target" 3 "IACC target" 4 "AEB target" 5 "dangerous target（ELK、UDLC、RCW, etc）" 6 "reserved" ;
VAL_ 775 ACC_ACCTargetDirection 0 "Forward" 1 "OnComing" 2 "Left" 3 "Right" 4 "unknown" 5 "no display" 6 "reserved" ;
VAL_ 775 ACC_ACCTargetLatRange 0 "" 1001 "" ;
VAL_ 775 ACC_ACCTargetRelSpd 0 "" 501 "" ;
VAL_ 775 ACC_DistanceAlertLevel 0 "no display" 1 " Level 1" 2 "Level 2" 3 " Level 3" 4 " reverved" 5 " reverved" 6 " reverved" 7 " reverved" ;
VAL_ 775 ACC_ACCTargetType 0 "no display" 1 "sedan" 2 "motorcycle" 3 "pedestrian" 4 "Bicycle" 5 "Bus" 6 "van" 7 "truck" 8 "reserved" 15 "other" ;
VAL_ 775 ACC_FRadarCalibrationStatus 0 " Calibration is ok" 1 " Calibration In Process" 2 " Calibration never done" 3 "  Calibration Failed" ;
VAL_ 775 ACC_ACCTargetLngRange 0 "-70~180" 501 "reserved" 511 "no display" ;
VAL_ 775 ACC_SaftyBeltVibrationReq 0 "No Request" 1 "Request" ;
VAL_ 775 ACC_SaftyBelt_Tightened 0 "level0" 1 "level 1" 2 "level 2" 3 "Reserved" ;
VAL_ 775 ACC_CruiseSetStatus 0 "reserved" 1 "ACC" 2 "CC" 3 "IACC（预留）" 4 "HWA（预留）" 5 "reserved" 7 "off" ;
VAL_ 775 ACC_ACCObjSoundEnable 0 "no voice" 1 "Reserved" 3 "both voice" ;
VAL_ 775 ACC_FCWSettingStatus 0 "early" 1 "normal" 2 "late" 3 "Off" 4 "Reserved" ;
VAL_ 775 ACC_AEBEnable 0 "off" 1 "on" ;
VAL_ 775 ACC_ACCEPBrequest 0 " no request" 1 "  request" ;
VAL_ 775 ACC_ObjValid 0 " no object" 1 " target object detected" ;
VAL_ 775 ACC_TimeGapSet 0 "no display" 1 " 1.0S" 2 " 1.4S" 3 " 1.8S" 4 " 2.4S" 5 "3s" 6 "reserved" ;
VAL_ 775 ACC_DistanceLevel 0 "no display" 1 " Level 1" 2 "Level 2" 3 " Level 3" 4 "reserved" ;
VAL_ 786 ACC_Selflearning_status 0 "int" 1 "earning" 2 "completed" 3 "rsvrd" ;
VAL_ 786 ADS_ADSVoiceRequest 0 "no display" 1 "TakeOver" 2 "saft parking" 3 "deactivate" 4 "handsoff0" 5 "drowsiness" 6 "IACC Cancel" 7 "IACC active" 8 "IACC suspend" 9 "IACCorACC Override" 10 "ACC Cancel" 11 "ACC Active" 12 "TJP active" 13 "SeatPostureRectify" 14 "vehicle distance" 19 "speed out of range" 20 "lanechange to leftpath" 21 " lanechange to rightpath" 22 "lane change return" 23 "lanechange to left side soon" 24 "lanechange to right side soon" 25 "plz lanechange for PathThroughRamp in right side" 26 "plz lanechange for PathThroughRamp in left side" 31 "lanechange condition not support" 32 "waiting lanechange timeout" 33 "Be careful of complex road condition" 34 "Be careful of confluence ahead" 35 "frequent accidents" 36 "Congestion ahead" 37 " plz override for PathThroughRamp" 38 " plz override because of toll station ahead" 39 "recommend TJP" 40 "SpdLimit" 41 "NID cancle" 42 "NID active" 43 "NID out" 44 "Bad weather lead to NID out" 45 "sharp turn lead to NID out" 46 "Toll Station lead to NID out" 47 "accidents lead to NID out" 48 "roadworks lead to NID out" 49 " NID out after 300m" 50 " NID out after 200m" 51 " NID out after 100m" 52 "concetrate
0x35=concetrate to see road" 54 "NID out after 1000m" 55 "sharp turn Plz watch out" 56 "leaving out current road plz watch out" 57 "merge in main road plz watch out" 58 "ramp ahead to turn left" 59 "ramp ahead to turn right" 60 "merge in main road" 61 "turn left right now" 62 "turn right right now" 63 "overtakeing left" 64 "overtaking right" 65 "heavy braking" 66 "over speed" 67 "前方红绿灯，智能限速" 68 "前方人行横道，请注意减速慢行" 69 "前方人行横道，智能限速" 70 "前方收费站，请注意减速慢行" 71 "前方收费站，智能限速" 72 "前方弯道，智能限速" 73 "智能加速避让并行车辆" 74 "智能减速避让并行车辆" 75 "主动加速提醒" 76 "您正处于弯道中，辅助驾驶IACC无法激活" 77 "激活失败，请先减速到120KM/H" 78 "" ;
VAL_ 786 ADS_ADSRoadVoiceEnableSts 0 "OFF" 1 "ON" ;
VAL_ 786 ADS_ADSLaneChangeVoiceEnableSts 0 "OFF" 1 "ON" ;
VAL_ 786 ADS_ADSSafeVoiceEnableSts 0 "OFF" 1 "ON" ;
VAL_ 786 ADS_NDANavEnableStatus 0 "OFF" 1 "ON" ;
VAL_ 786 ADS_NDAAudioWarEnableStatus 0 "OFF" 1 "ON" ;
VAL_ 786 ADS_NDAEnableStatus 0 "OFF" 1 "ON" ;
VAL_ 786 ADS_ALCDirection 0 "Invalid" 1 "LaneChangeToLeft" 2 "LaneChangeToRight" 3 "Reserved" ;
VAL_ 786 ADS_ALCTextInfoForDriver 0 "No Display" 1 "LaneChangeToLeftForPathThroughRamp前方接近匝道，即将向左换道" 2 "LaneChangeToRightForPathThroughRamp前方接近匝道，即将向右换道" 3 "LaneChangeForQuickRoad,即将汇入主路" 4 "LaneChangeToLeft即将向左换道" 5 "LaneChangeToRight即将向右换道" 6 "LaneChangeToLeftForSurpassTheCar,即将向左超车" 7 "LaneChangeToRightForSurpassTheCar,即将向右超车" 8 "Reserved" ;
VAL_ 786 ADS_LaneChangeStyle 0 "ComfortableStyle" 1 "SportStyle" ;
VAL_ 786 ADS_UDLCVoiceRecStatus 0 "No request" 1 "Left Lane Change Active（左换道激活）" 2 "Right Lane Change Active（右换道激活）" 3 "voice change lane  to left side for the  traffic jam（当前车道行驶缓慢，可向左变道）" 4 "voice change lane  to right side for the  traffic jam（当前车道行驶缓慢，可向右变道）" 5 "Unavailable（语音换道条件不满足)" 6 "Reserved" 7 "invalid" ;
VAL_ 786 ADS_EOMStatus 0 "关闭" 1 "待机" 2 "脱眼" 3 "故障" 4 "激活等待" 5 "Reserved" ;
VAL_ 786 ADS_EOMSeatSteeringAdjustReq 0 "No Request" 1 "Request" ;
VAL_ 786 ADS_EOMDriverHeadPos 0 "0" 1 "1" 2 "2" 3 "3" 4 "-1" 5 "-2" 6 "-3" 7 "Reserved" ;
VAL_ 786 ADS_EOMActiveReq 0 "No Request" 1 "Request" ;
VAL_ 786 ADS_SpdLimitedStatus 0 "未限速" 1 "基于限速牌限速" 2 "预留" ;
VAL_ 786 ACC_SunroofControl 0 "inactive" 1 " SunRoof 0%~100% " 102 " tilt" 103 " Sunshade0%~100%" 204 " Stop" 205 "Reserved" 254 "initialize" 255 "Reserved" ;
VAL_ 786 ACC_RightRearWindowControl 0 " No Request" 1 " 0%~100% (支持百分比形式)" 102 " Reserved" ;
VAL_ 786 ACC_LeftRearWindowControl 0 " No Request" 1 " 0%~100% (支持百分比形式)" 102 " Reserved" ;
VAL_ 786 ACC_PassengerWindowControl 0 " No Request" 1 " 0%~100% (支持百分比形式)" 102 " Reserved" ;
VAL_ 786 ACC_DriverWindowControl 0 " No Request" 1 " 0%~100% (支持百分比形式)" 102 " Reserved" ;
VAL_ 786 ADS_UDLCTextInfoForDriver 0 "no display" 1 "UDLC exit，触发式换道已退出，（UDLC不再等待换道并且不再主导控制）" 2 "UDLC return，触发式换道已退出并回退原车道（驾驶员取消转向灯回退或系统回退开始时）" 3 "UDLC finished，请拨回转向灯（换道完成或回退对中完成时）" 4 "Lane change request by merge" 5 "change lane  to both sides for the  traffic jam,两边车道均可支持变道" 6 "Lane change request by ramp" 7 "change lane  to left side for the  traffic jam,左边车道可支持变道" 8 "change lane  to right side for the  traffic jam,右边车道可支持变道" 9 " out of ODD暂时不满足换道条件，不尝试换道" 10 "Please turn on the UDLC in HU请在主机中打开主动换道设置开关" 11 "speed out of range车速超出范围，自动换道条件不满足" 12 "UDLC System Error自动换道系统故障" 13 "雨量过大，自动换道条件不满足" 14 "wait over time,换道尝试超时中止" 15 "reserved" ;
VAL_ 786 ADS_AutoWiperShift_Rqe 0 "Off" 1 "On" ;
VAL_ 786 ACC_HornCommand 0 "No Request" 1 "Long Honk" 2 "Interval Honk" 3 "Reserved" ;
VAL_ 786 ADS_AutoHeadlightshift_Req 0 "Off" 1 "On" ;
VAL_ 786 ADS_HighBeamLampOnRequest 0 "No Request" 1 "Light On" 2 "Light Off" 3 "Reserved" ;
VAL_ 786 ADS_LowBeamLampOnRequest 0 "No Request" 1 "Light On" 2 "Light Off" 3 "Reserved" ;
VAL_ 786 ADS_LightFrequencyRequest 0 "Off" 1 "Level1" 2 "Level2" 3 "Level3" 4 "Level4" 5 "Level5" 6 "Level6" 7 "Level7" ;
VAL_ 786 ADS_LightBrightRequest 0 "Off" 1 "Level1" 2 "Level2" 3 "Level3" 4 "Level4" 5 "Level5" 6 "Level6" 7 "Invalid" ;
VAL_ 786 ADS_LightFlashRequest 0 "No Request" 1 "Request" ;
VAL_ 786 ADS_LightColorRequest 0 "No Request" 1 "White" 2 "Green" 3 "Red" 4 "Reserved" 7 "Invalid" ;
VAL_ 786 ADS_LightingReq 0 "Off" 1 "On" ;
VAL_ 786 ADS_rescueReq 0 "No Request" 1 "Request" ;
VAL_ 786 ADS_SafeStopSts 0 "not active" 1 "Stopping" 2 "Warning" 3 "not available" ;
VAL_ 786 ADS_EyesOffWarningInhi 0 "no request" 1 "Request" ;
VAL_ 786 ADS_EOMWarnning 0 "no warnning" 1 "L1 warnning" 2 "L2 warnning" 3 "L3 warnning" 4 "Reserved" ;
VAL_ 786 ADS_ESSEnable 0 "OFF" 1 "ON" ;
VAL_ 786 ADS_RLaneColor 0 "No display" 1 "White" 2 "Blue(alc)" 3 "Red" 4 "Gray" 5 "Reserved" ;
VAL_ 786 ADS_LLaneColor 0 "No display" 1 "White" 2 "Blue(alc)" 3 "Red" 4 "Gray" 5 "Reserved" ;
VAL_ 786 ADS_UDLCTurnRightRequest 0 " no request" 1 "request" ;
VAL_ 786 ADS_UDLCRightStatus 0 "Not ready " 1 "Ready" 2 "Active_Wait_Right" 3 "Active_Delay_Right" 4 "Right lane change Active" 5 "Not Active by Obj" 6 "Reserved" ;
VAL_ 786 ADS_UDLCTurnLeftRequest 0 " no request" 1 "request" ;
VAL_ 786 ADS_UDLCTurnLightReq 0 " no request" 1 " Left Request OFF" 2 "  Right Request OFF" 3 "Left Request ON" 4 " Right Request ON" 5 "Reserved" 7 "Invalid" ;
VAL_ 786 ADS_UDLCLeftStatus 0 "Not ready " 1 "Ready" 2 "Active_Wait_Left" 3 "Active_Delay_Left" 4 "Left lane change Active" 5 "Not Active by Obj" 6 "Reserved" 15 "invalid" ;
VAL_ 786 ADS_UDLCStatus 0 "OFF" 1 "Passive" 2 "Active" 3 "Return to lane by driver" 4 "Return to lane by system " 5 "Maual Override" 6 "Failure" 7 "Lane Change Complete" 8 "Takeover" 9 "Reserved" ;
VAL_ 786 ADS_UDLCEnableStatus 0 "OFF" 1 "ON" ;
VAL_ 786 ADS_ESSMode 0 "off" 1 "passive" 2 " active" 3 "fault" 4 "reserved" ;
VAL_ 786 ACC_AEBTargetDirection 0 "Forward" 1 "OnComing" 2 "Left" 3 "Right" 4 "unknown" 5 "no display" 6 "reserved" ;
VAL_ 786 ACC_AEBTargetDetection 0 "no detected" 1 "detected" ;
VAL_ 786 ACC_AEBTargetType 0 "no display" 1 "sedan" 2 "motorcycle" 3 "pedestrian" 4 "Bicycle" 5 "Bus" 6 "van" 7 "truck" 8 "reserved" 15 "other" ;
VAL_ 786 ACC_RLaneDistanceFusion 0 "-1-5" 121 "reserved" ;
VAL_ 786 ACC_LLaneDistanceFusion 0 "-1-5" 121 "reserved" ;
VAL_ 786 ACC_HostPotentialTargetID 0 "1-15" 15 "no target" ;
VAL_ 786 ACC_FRTarget2ID 0 "1-15" 15 "no target" ;
VAL_ 786 ACC_FRTarget1ID 0 "1-15" 15 "no target" ;
VAL_ 786 ACC_FLTarget2ID 0 "1-15" 15 "no target" ;
VAL_ 786 ACC_FLTarget1ID 0 "1-15" 15 "no target" ;
VAL_ 786 ACC_ACCTargetID 0 "1-15" 15 "no target" ;
VAL_ 832 AC_FrBlowType 0 "blow face" 1 "blow face/blow feet" 2 "blow feet" 3 "blow fee/defroster" 4 "defroster" 5 "Reserved" 7 "Invalid." ;
VAL_ 839 TPMS_RRPressureWarning 0 "No warning" 1 "High pressure warning" 2 "Low pressure warning" 3 "Quik leakage" 4 "Lost Sensor" 5 "Sensor battery low" 6 "Sensor failure" 7 "Reserved" ;
VAL_ 839 TPMS_LRPressureWarning 0 "No warning" 1 "High pressure warning" 2 "Low pressure warning" 3 "Quik leakage" 4 "Lost Sensor" 5 "Sensor battery low" 6 "Sensor failure" 7 "Reserved" ;
VAL_ 839 TPMS_LFPressureWarning 0 "No warning" 1 "High pressure warning" 2 "Low pressure warning" 3 "Quik leakage" 4 "Lost Sensor" 5 "Sensor battery low" 6 "Sensor failure" 7 "Reserved" ;
VAL_ 839 TPMS_RFPressureWarning 0 "No warning" 1 "High pressure warning" 2 "Low pressure warning" 3 "Quik leakage" 4 "Lost Sensor" 5 "Sensor battery low" 6 "Sensor failure" 7 "Reserved" ;
VAL_ 869 IMS_HeadDetectSts_Yaw 0 "-75~75" 152 "Reserved" 255 "invalid" ;
VAL_ 869 IMS_HeadDetectSts_Roll 0 "-45~45" 92 "Reserved" 255 "invalid" ;
VAL_ 869 IMS_HeadDetectSts_Pitch 0 "-25~45" 72 "Reserved" 255 "invalid" ;
VAL_ 869 IMS_IMSStatus 0 " Off" 1 " Standby" 2 " Active" 3 " Camera Blocked" 4 " Failure" 5 " Reserved" 7 " Invalid" ;
VAL_ 869 IMS_EyeGazeStatus 0 "-75~75" 152 "Reserved" 255 "invalid" ;
VAL_ 869 IMS_EyeDetectSatus 0 "0~100%" 101 "Reserved" 255 "invalid   " ;
VAL_ 869 IMS_DrowsinessStatus 0 " Awake" 1 " Slightly Drowsy" 2 " Drowsy" 3 "Microsleep" 4 " Reserved" 5 " Unavailable" 6 "Unknown" 7 " Invalid" ;
VAL_ 869 IMS_DriverHeadDetect 0 "Invalid" 1 "Not detected" 2 "detected" 3 "Reserved" ;
VAL_ 869 IMS_DistractionStatus 0 " Not Distracted" 1 " Distracted" 2 "Unknown" 3 " Invalid" ;
VAL_ 870 AC_EnvironmentalTemp 0 "-40~87℃" 255 "Invalid" ;
VAL_ 870 AC_EnvironmentalTempVD 0 "Valid" 1 "Invalid" ;
VAL_ 903 BCM_RainfallLevel 0 "No rain" 1 "Level 1" 2 "Level 2" 3 "Level 3" 4 "Level 4" 5 "Level 5?" 6 "Level 6" 7 "Level 7" 8 "Level 8" 9 "Level 9" 10 "Level 10" 11 "Level 11" 12 "Level 12" 13 "level 13" 14 "init value" 15 "Invalid value" ;
VAL_ 903 BCM_FrontWiperStatus 0 "OFF" 1 "Low" 2 "High" 3 "Error" ;
VAL_ 912 BCM_SOH_LifePercent 0 "%0-100%" 101 "Reserved" 255 "invalid" ;
VAL_ 912 BCM_PMSLevel 0 "电量正常" 1 "电量低" 2 "电量消耗过多" 3 "预留Reserved" ;
VAL_ 918 BCM_SunroofStatus 0 "Close" 1 "Open" ;
VAL_ 1287 HU_NDAAudioWarEnable 0 "Inactive" 1 "Off" 2 "On" 3 " Reserved" ;
VAL_ 1287 HU_TJPEnable 0 "Inactive" 1 "Off" 2 "On" 3 " Reserved" ;
VAL_ 1287 HU_VC_CruiseSetSpeed 0 "No Request" 1 "1-250" 251 "Reserved" 255 "Invalid" ;
VAL_ 1287 HU_VC_CruiseSetDistance 0 "No Request" 1 "Level 1" 2 "Level 2" 3 "Level 3" 4 "Level 4" 5 "Level 5" 6 "reserved" 7 "Invalid" ;
VAL_ 1287 HU_VC_CruiseControl 0 "No Request" 1 "ACC Activate" 2 "ACC Resume" 3 "IACC Activate" 4 "IACC Resume" 5 "Cancel" 6 "Reserved" 7 "Invalid" ;
VAL_ 1287 HU_FCWSetting 0 "Early" 1 "Normal" 2 "Late" 3 "Off" 4 "Reserved" 7 "Invalid" ;
VAL_ 1287 HU_ACCObjEnable 0 "no voice" 1 " Reserved" 3 " both voice" ;
VAL_ 1287 HU_CruiseControlSet 0 "Inactive" 1 "ACC" 2 "CC" 3 "IACC（预留）" 4 "HWA（预留）" 5 "reserved" ;
VAL_ 1287 HU_AutoBrakeEnable 0 "off" 1 "on" ;
VAL_ 1287 HU_IACCEnable 0 "Inactive" 1 "Off" 2 "On" 3 "Reserved" ;
VAL_ 1287 HU_LDWShakeLev 0 "inactive" 1 "low" 2 "normal" 3 "high" ;
VAL_ 1287 HU_RCTAEnable 0 "inactive" 1 "Off" 2 "On" 3 " Reserved" ;
VAL_ 1287 HU_HMAEnable 0 "off" 1 "on" ;
VAL_ 1287 HU_TSRSwitch 0 "off" 1 "on" ;
VAL_ 1287 HU_LASWarningModeSelection 0 "inactive" 1 "visual" 2 "sound" 3 "vibration" 4 "sound and vibration" 5 "Reserved" ;
VAL_ 1287 HU_LASModeSelection 0 "Inactive" 1 "LDW" 2 "LKA" 3 "LCS" 4 "Reserved" 7 "OFF" ;
VAL_ 1287 HU_OverspeedWarningOffset 0 "-10~10km/h" 21 "Reserved" 31 "Invalid" ;
VAL_ 1287 HU_OverspeedWarningEnable 0 "Inactive" 1 "OFF" 2 "ON" 3 "Reserved" ;
VAL_ 1287 HU_OverspeedSoundWarEnable 0 "Inactive" 1 "Off" 2 "On" 3 " Reserved" ;
VAL_ 1302 HU_LocalTimeSystem 0 "24h" 1 "12h" 2 "Reserved" 3 "Invalid" ;
VAL_ 1302 HU_LocalTimeValid 0 "Valid" 1 "Not Valid" ;
VAL_ 1302 HU_CurrentLocationLatitude 134217727 "" ;
VAL_ 1302 HU_CurrentLocationLongitude 268435455 "" ;
VAL_ 1302 HU_CurrentLocationValid 0 "Valid" 1 "Not Valid" ;
VAL_ 1352 ADS_EventCode 0 "inactive" 1 "事件0~事件1023" ;
VAL_ 1352 ADS_EventAmount 0 "0~127" ;
VAL_ 1352 ADS_EventStartEndIdentify 0 "End" 1 "Start" ;
VAL_ 1352 ADS_EID 0 "0~255" ;
VAL_ 1352 ADS_ControllerCode 0 "inactive" 1 "ADS" 2 "APA" 3 "GW" 4 "HPP" 5 "Reserved" ;
VAL_ 1554 DVR_EmergencyRecordStatus 0 "invalid" 1 "Unsuccessful" 2 "Success" 3 "Saving" ;
VAL_ 1554 DVR_Error 0 "normal" 1 "error" ;
VAL_ 382 EPS_ADS_Abortfeedback 0 "No Fault" 1 "Adas Speed Invalid" 2 "Adas Signal Invalid " 3 "State Mismatch" 4 "APA Interrupt" 5 "BUS Off" 6 "Both Channels CAN down" 7 "Adas Chassis CAN Down " 8 "ADAS Internal Error" 9 "Speed out of range" 10 "AgAmpErr" 11 "AgGrdtFlt" 12 "Driver Interrupt" 13 "ADAS Req Mode Invld" ;
VAL_ 382 EPS_LatCtrlActive 0 "Not Actived" 1 "Actived" ;
VAL_ 382 EPS_LatCtrlAvailabilityStatus 0 "not Availability " 1 "Availability" 2 "failure" 3 "reserved" ;
VAL_ 382 EPS_MeasuredTorsionBarTorqValid 0 "可用" 1 "不可用" ;
VAL_ 382 EPS_MeasuredTorsionBarTorque 2048 "" ;
VAL_ 398 EMS_EngineStatus 0 "Stop" 1 "Crank" 2 "Running" 3 "Reserved" ;
VAL_ 398 EMS_EngineSpeed 0 "0~16383.5Rmp" 65535 "Invalid" ;
VAL_ 398 EMS_AccpedelError 0 "No error" 1 "Error" ;
VAL_ 398 EMS_EngineSpeedError 0 "No error" 1 "Error" ;
VAL_ 398 EMS_EngineFuelCutOff 0 "False" 1 "True" ;
VAL_ 398 EMS_BrakePedalStatus 0 "NotPressed" 1 "Pressed" 2 "Reserved" 3 "Error" ;
VAL_ 398 EMS_TorqFailure 1 "Failure" 0 "No Failure" ;
VAL_ 442 ACC_LatAngReqActive 0 "not Active" 1 "Active" ;
VAL_ 442 ACC_LatAngReq 14410 "Reserved" ;
VAL_ 442 ADS_ESSActive 0 "not active" 1 "active" ;
VAL_ 442 ACC_MotorTorqueMinLimitRequest 2047 " Reserved" ;
VAL_ 442 ACC_MotorTorqueMaxLimitRequest 2047 " Reserved" ;
VAL_ 591 EPS_ConcussAvailabilityStatus 0 "Concuss Availability 震动可用但是未震动" 1 "Concuss Active震动激活中" 2 "EPS Concuss failure  EPS震动故障不可用" 3 "reserved" ;
VAL_ 591 EPS_TorqueAssistMode 0 "Normal" 1 "light" 2 "heavy" 3 "unknow" ;
VAL_ 591 EPS_IACC_abortreason 0 "NO_DRIVING_INTERUPTION" 1 "DRIVER_RECOVERY(Over ride)" 2 "VEHICLE_SPEED ERROR" 3 "REQUEST ERROR" 4 "DAE_THERMAL_SECURITY" 5 "OTHER_DEFAULT" 6 "ADAS message Error（CD569项目0x6=Reserved）" 7 "Reserved" ;
VAL_ 618 EMS_EngineStatusWithSTT 0 "non-start/stop mode" 1 "Engine standby" 2 "Engine Stopped" 3 "Starter restart" 4 "Engine restart" 5 "Engine Operation" 6 "Engine auto-stopping" 7 "idle start not available" ;
VAL_ 618 EMS_AccReqPossible 0 "no error" 1 "error" ;
VAL_ 618 EMS_QECACC 3 "not defined" 2 "irreversible error" 1 "reversible error" 0 "no error" ;
VAL_ 618 EMS_ECGPOvrd 0 "no override" 1 "driver override" ;
VAL_ 651 BCM_TurnIndicatorLeft 0 "OFF" 1 "ON" 2 "Not used" 3 "Error" ;
VAL_ 651 BCM_TurnIndicatorRight 0 "OFF" 1 "ON" 2 "Not used" 3 "Error" ;
VAL_ 651 BCM_emergencylightstatus 0 "OFF" 1 "ON" 2 "Not used" 3 "Error（故障）" ;
VAL_ 651 BCM_PowerStatusFeedback 0 "OFF" 1 "ACC" 2 "ON" 3 "Start" ;
VAL_ 651 BCM_DriverDoorStatus 0 "Close" 1 "Open" ;
VAL_ 651 BCM_HoodStatus 0 "Close" 1 "Open" ;
VAL_ 651 BCM_LowBeamStatus 0 "OFF" 1 "ON" 2 "Not used" 3 "Reserved" ;
VAL_ 651 BCM_HighBeamStatus 0 "OFF" 1 "ON" 2 "Not used" 3 "Reserved" ;
VAL_ 651 BCM_TurnLightSwitchSts 0 "Not Actived" 1 "Left Actived" 2 "Right Actived" 3 "Invalid" ;
VAL_ 651 BCM_MirrorAdjustSts 0 "未调节
0x1=左外后视镜调节
0x2=右外后视镜调节
0x3=预留" ;
VAL_ 676 LCDAR_RCTBStatus 0 "OFF(关闭)" 1 "Inactive(未激活)" 2 "Active" 3 "Failure" ;
VAL_ 676 LCDAR_ELK_oAlert 0 "No warning" 1 "level 1" 2 "level 2" 3 "Reserved" ;
VAL_ 676 LCDAR_ELK_oStatus 0 "OFF(关闭)（预留）" 1 "Inactive(未激活)" 2 "Active" 3 "Failure" ;
VAL_ 676 LCDAR_Left_ELK_oAlert 0 "No warning" 1 "level 1" 2 "level 2" 3 "Reserved" ;
VAL_ 676 LCDAR_RCTBActive 0 " not Active" 1 " Active." ;
VAL_ 676 LCDAR_RCTBEnable 0 "off" 1 "on" ;
VAL_ 676 LCDAR_SystemStatus 0 "Reserved" 1 "StartUp" 2 "Running" 3 "Blocked" 4 "Calibration" 5 "ShutDown" 6 "Hot" 7 "Failure" ;
VAL_ 710 APA_vehicleFrontdetect 0 "No Detect" 1 "Detect" 2 "Reserved" 3 "Invalid" ;
VAL_ 721 BCM_TrunkDoorStatus 0 "Close" 1 "Open" ;
VAL_ 721 BCM_RightRearDoorStatus 0 "Close" 1 "Open" ;
VAL_ 721 BCM_PassengerDoorStatus 0 "Close" 1 "Open" ;
VAL_ 726 EMS_EngineLimpHome 0 "not LimpHome" 1 "LimpHome" ;
VAL_ 794 AD_HandsoffWarningExitReason 0 "idle" 1 "手握方向盘" 2 "手拉方向盘" 3 "按下方向盘按键" 4 "搬动操纵杆" 5 "功能退出" 6 "最小安全策略执行完成" 7 "其他原因" ;
VAL_ 794 ACC_LngTakeOverReqReason 0 "无报警" 1 "控制器、传感器故障" 2 "关联子系统故障" 3 "超过纵向控制能力限制" 4 "前方存在危险目标（如行人、锥形筒等障碍物）" 5 "车道线置信度低" 6 "超过车速、曲率、方向盘转角等阈值限制" 7 "非安全状态（ESP、TCS、AEB等触发）" 8 "触发风险减缓" 9 "超出ODD范围" 10 "预留" ;
VAL_ 794 ACC_ELKAlert 0 "No warning" 1 "left Warning" 2 "right Warning" 3 "reserved" ;
VAL_ 794 ADS_HWAEnableStatus 0 "OFF" 1 "ON" ;
VAL_ 794 ADS_IsInFence 0 "not inside geo-fence" 1 "inside geo-fence" 2 "reserved" ;
VAL_ 794 ADS_TJPEnableStatus 0 "OFF,0x1=ON" ;
VAL_ 794 ACC_ELKEnableStatus 0 "off" 1 "on" ;
VAL_ 794 ACC_ELKInterventionMode 0 " off" 1 " Road edge" 2 " Overtaking" 3 " Oncoming." ;
VAL_ 794 ACC_ELKMode 0 " off" 1 " passive" 2 "active" 3 " fault" 4 " reserved." ;
VAL_ 794 ACC_HostPedLatRange_1 0 "-25-25m" 251 "reserved" ;
VAL_ 794 ACC_HostPedLngRange_1 0 "0-62m" 63 "reserved" ;
VAL_ 794 ACC_HostPedDetection_1 0 "not dectected" 1 "dectected" 2 "reserved" ;
VAL_ 794 ACC_RRLaneDistance 0 "0-12" 61 "reserved" ;
VAL_ 794 ACC_RRLaneDetection 0 "not detected" 1 "Dashed" 2 "solid" 3 "fence/road edge" ;
VAL_ 794 ACC_LLLaneDistance 0 "0-12" 61 "reserved" ;
VAL_ 794 ACC_LLLaneDetection 0 "not detected" 1 "Dashed" 2 "solid" 3 "fence/road edge" ;
VAL_ 794 ACC_DoorCtrlReq 0 "no request" 1 "lock" 2 "unlock " 3 "reserved" ;
VAL_ 794 ACC_HighBeamControl 0 "No Request" 1 "Request" 2 "Reserved" ;
VAL_ 794 ACC_TargetBasedLateralControl 0 "no lateral control" 1 "around Based" 2 "lane based" 3 "target based" ;
VAL_ 794 ACC_IACCHWATextInfoForDriver 0 "no display" 1 "IACC Cancel" 2 "IACC deactivate" 3 "IACC unintended exit" 4 "unable to activate IACC" 5 "lane condition not available" 6 "ADR/DVR Status not Match" 7 "longitudinal control not available" 8 "IACC not available by EPS" 9 "exceed speed limit" 10 "driver overrides steering" 11 "caution about driving safty" 12 " system error" 13 " prohibition request for safestop" 14 "turn light switch on" 15 "Hands on plz" 16 " Please turn on IACC in incall " 17 " unable to active in curve" 18 " unable to active for not in lane/crossing lane" 19 "Longitude Exit" 20 "takeover request with safety stoping" 21 "takeover request with safety stop completed" 22 "other system error" 23 "unable to active in Bad weather" 24 "Prohibition request for rdf" 25 "Lights on please" 26 "智慧偏移，避让大型车辆" 27 " Driver Drowsy or Distracted" 28 "HWA recommend" 29 "lane missing" 30 "请注意侧方车辆，谨慎驾驶
0x1F=reserved" ;
VAL_ 794 ACC_EmergencyLightingRequest 0 "no request" 1 "Level1" 2 "Level2" 3 "OFF" ;
VAL_ 794 ACC_HandsoffFuncTextinfo 0 "no display（handson mode）" 1 "total handsoff mode" 2 "out of handsoff mode by out ODD" 3 " out of handsoff mode by Drowsiness" 4 " out of handsoff mode by Distraction" 5 " out of handsoff mode by IMS/Nav/HOD invalid" 6 " out of handsoff mode by dangerous" 7 "out of handsoff mode by control bad" 8 "out of handsoff mode by IACC suspend" 9 "limited by distraction" 10 "limiited by drowsiness" 11 "limited by roadtype" 12 "limited by control bad" 13 "limited by not driver suspend" 14 "Reserved" ;
VAL_ 794 ACC_HandsoffFuncStatus 0 "off" 1 "passive" 2 "standby" 3 "warning" 4 "total handsoff mode" 5 "handsoff with limit" 6 "reserved" 7 "failure" ;
VAL_ 794 ACC_DriverHandsOffStatus 0 "hands off" 1 "hands on Level1" 2 "hand on Level2" 3 "unkown" ;
VAL_ 794 ACC_IACCHWAMode 0 "off" 1 "standby" 2 "passive" 3 "active" 4 "suspend" 5 " prohibition" 6 "reserved" 7 "failure" ;
VAL_ 794 ACC_LaneChangeStatus 0 "未变道" 1 "向左变道中" 2 "向右变道中" 3 "变道结束" ;
VAL_ 794 ACC_RoadCurvatureFar 0 "-0.03-0.03" 121 "reserved" ;
VAL_ 794 ACC_RoadCurvatureNear 0 "-0.03-0.03" 121 "reserved" ;
VAL_ 794 ACC_RoadCurvature 0 "-0.03-0.03" 121 "reserved" ;
VAL_ 794 ACC_IACCHWAEnable 0 "OFF" 1 "ON" ;
VAL_ 794 ACC_RLaneMarkerType 0 "Dashed" 1 "solid" 2 "road edge" 3 "double lane mark" 4 "Virtual Boun" 5 "other" 6 "fence" 7 "no display" ;
VAL_ 794 ACC_LLaneMarkerType 0 "Dashed" 1 "solid" 2 "road edge" 3 "double lane mark" 4 "Virtual Boun" 5 "other" 6 "fence" 7 "no display" ;
VAL_ 794 ACC_HostLaneRightStatus 0 "No display" 1 "Tracking" 2 "Intervention" 3 "Warning" 4 "Centering" 5 "Crossing" 6 "UDLC Request Active" 7 "reserved" 8 "UDLC Not Active By Obj" 9 "reserved" ;
VAL_ 794 ACC_HostLaneLeftStatus 0 "No display" 1 "Tracking" 2 "Intervention" 3 "Warning" 4 "Centering" 5 "Crossing" 6 "UDLC Request Active" 7 "reserved" 8 "UDLC Not Active By Obj" 9 "reserved" ;
VAL_ 794 ACC_LASWarningModeSelectionSts 0 "Reserved" 1 "sound" 2 "vibration" 3 "sound and vibration" 4 "Reserved" ;
VAL_ 794 ACC_LASModeSelectionStatus 0 "Reserved" 1 "LDW" 2 "LKA" 3 "LCS" 4 "Reserved" 7 "OFF" ;
VAL_ 794 ACC_FRadarFailureStatus 0 " no failure" 1 "blind" 2 "reversible failure" 3 " irrversible failure" ;
VAL_ 794 ACC_AEBTargetLatRange 0 "" 1001 "" ;
VAL_ 794 ACC_AEBTargetRelSpeed 0 "" 501 "" ;
VAL_ 794 ACC_AEBTargetLngRange 0 "-70~180" 501 "reserved" 511 "no display" ;
VAL_ 794 ACC_Voiceinfo 0 "no voice" 1 "latentWarning voive" 2 "FCW/AEB voice" 3 "ACC object detect voice" 4 "ACC object disappeared voice" 5 "ACC/IACC takeover request voice" 6 "Lane Left dangerous warning  voice" 7 "Lane Right dangerous warning  voice" 8 "reserved" 9 "IACC Active voice" 10 "IACC exit voice" 11 "reserved" 12 "reserved" 13 "cruise unintended exit" 14 "TrafficWarning" 15 "reserved" ;
VAL_ 794 ACC_AEBTargetmode 0 "none" 1 "video only mode" 2 "rader only mode" 3 "fusion mode" ;
VAL_ 794 ACC_AEBTextInfo 0 "no display" 1 "AEB Error by camera" 2 "AEB Error by FR" 3 "AEB Error by Dasy" 4 "AEB Error by FCR" 5 "AEB Error by EPBi" 6 "AEB Error by SAS" 7 "AEB Error by SRS" 8 "AEB Error by EMS" 9 "AEB Error by TCU" 10 "AEB Error by other" 11 "reserved" ;
VAL_ 794 ACC_AEBStatus 0 "off" 1 "on" 2 " reserved" 3 "failure" ;
VAL_ 879 ADS_PathShow_Sts 0 "no display" 1 "跟车路径" 2 "导航路径" 3 "reserved" ;
VAL_ 879 ADS_NDAFenceTerminalDis 0 " 0~3000m" 301 "reserved" 1022 "Out of Range" 1023 "unknown" ;
VAL_ 879 ADS_NDATextInfo 0 "no display" 1 "Out of Road ODD" 2 "NDA Limit" 3 "Weather Limit" 4 "Turn Limit" 5 "System Limit" 6 "Toll Exit" 7 "TrafficAccident Exit" 8 "Construction Exit" 9 "Imminent" 10 "Handsoff And Eyesoff" 11 "Eyesoff level2" 12 "Eyesoff level1" 13 "About Exitt" 14 "Sharp Turn" 15 "Leave current road" 16 "Join to main road" 17 "Speed too high" 18 "NDA exit" 19 "NDA active" 20 "下匝道脱手提示1级" 21 "下匝道脱手提示2级" 22 "reserved" ;
VAL_ 879 ADS_NDAStatus 0 "OFF" 1 "Passive" 2 "StandBy" 3 "ALC Active" 4 "FIDA Active" 5 "Takeover" 6 "Prohibition" 7 "Reserved" ;
VAL_ 879 ADS_TunnelStatus 0 "no display" 1 "nearTunnel" 2 "inTunnel" 3 "reserved" ;
VAL_ 879 ADS_RampStatus 0 "no display" 1 "nearRamp" 2 "rampIn" 3 "inRamp" 4 "RampOut" 5 "reserved" ;
VAL_ 879 ADS_PathThroughRamp 0 "notThroughRamp" 1 "throughRamp" 2 "invalid" 3 "reserved" ;
VAL_ 879 ADS_RampSide 0 "invalid" 1 "onRightSide" 2 "onLeftSide" 3 "reserved" ;
VAL_ 879 ADS_EOMNotice 0 "无提示" 1 "超出电子围栏或无法定位" 2 "超出速度范围" 3 "超出坡度或曲率范围" 4 "前方施工区域" 5 "道路太窄或太宽" 6 "安全停车提示" 7 "系统即将退出" 8 "当前或前方即将道路合并" 9 "无车道线" 10 "拥堵解除" 11 "前方有行人或机动车辆" 12 "有危险目标" 13 "TJP系统错误或故障" 14 "胎压过低" 15 "摄像头被遮挡" 16 "雷达被遮挡" 17 "极端天气" 18 "前方交通事故" 19 "前方经过匝道" 20 "未及时响应系统请求" 21 "当前不可激活或激活失败" 22 "引导用户激活操作提示" 23 "刹车踩到底并调节座椅" 24 "Reserved" 30 "前方隧道，请注意" 31 "Invalid" ;
VAL_ 879 ADS_SeatPostureRectifyReq 0 "no request" 1 "level 1 request" 2 "level 2 request" 3 "level 3 request" 4 "reserved" ;
VAL_ 879 ADS_EOMDwgradingnotice 0 "无提示" 1 "提醒降级到HWA对注意力要求" 2 "提醒降级到IACC对注意力要求" 3 "提醒降级到IACC对手握方向盘要求" 4 "提醒降级到IACC对注意力及手握方向盘要求" 5 "reserved" ;
VAL_ 879 ADS_AutoDriveStateDisplay 0 "no display" 1 "ACC" 2 "IACC" 3 "HWA" 4 "NDA" 5 "共驾" 6 "1级提醒报警" 7 "2级提醒报警" 8 "3级提醒报警" 9 "4级提醒报警" 10 "1级立即接管报警" 11 "2级立即接管报警" 12 "3级立即接管报警" 13 "0xF=reserved" ;
VAL_ 879 ADS_PathShow_Status 0 "no display" 1 "LaneChangeTryPath，换道等待" 2 "NormalLaneChangePath，换道过程" 3 "LaneChangeReturnPath，换道回退" 4 "CanNotChangeLanePath，换道等待或保持本车道行驶" 5 "SmartBiasPath，智慧偏移路径" 6 "FollowVehicleDrivePath，跟车行驶路径" 7 "RecommendPath，推荐路径" ;
VAL_ 879 ADS_RoadSlopeFlag 0 "无效" 1 "有效" ;
VAL_ 879 ADS_RoadMergeFlag 0 "无效
0x1=有效" ;
VAL_ 879 ACC_TakeoverReqAtIPFail 0 "no request" 1 "level 1 request" 2 "level 2 request" 3 "reserved" ;
VAL_ 879 ADS_TSRHostNextSpdLimitDist 0 "0~400" 401 "reserved" 511 "no display" ;
VAL_ 879 ADS_TSRHostNextSpdLimit 0 "no speed limit detected" 1 "SL5" 2 "SL10" 3 "SL15" 4 "SL20" 5 "SL25" 6 "SL30" 7 "SL35" 8 "SL40" 9 "SL45" 10 "SL50" 11 "SL55" 12 "SL60" 13 "SL65" 14 "SL70" 15 "SL75" 16 "SL80" 17 "SL85" 18 "SL90" 19 "SL95" 20 "SL100" 21 "SL105" 22 "SL110" 23 "SL115" 24 "SL120" 25 "SL125" 26 "SL130" 27 "SL135" 28 "SL140" 29 "SL145" 30 "SL150" 31 "SL155" 32 "SL160" 33 " Reserved" 254 " Unlimited" 255 " SLEND" ;
VAL_ 879 ADS_RightPedWarnLevel 0 "no warning" 1 "lightly remind" 2 "moderate alram" 3 "collision warning" ;
VAL_ 879 ADS_RightPedDetection 0 "not dectected" 1 "one pedestrian dectected" 2 "multiple pedestrians dectected" 3 "invalid" ;
VAL_ 879 ADS_LeftPedWarnLevel 0 "no warning" 1 "lightly remind" 2 "moderate alram" 3 "collision warning" ;
VAL_ 879 ADS_LeftPedDetection 0 "not dectected" 1 "one pedestrian dectected" 2 "multiple pedestrians dectected" 3 "invalid" ;
VAL_ 879 ADS_HostPedWarnLevel_1 0 "no warning" 1 "lightly remind" 2 "moderate alram" 3 "collision warning" ;
VAL_ 922 LAS_TSRSpeedLimitType 0 "Unknown" 1 "Speed-Limit Sign" 2 "Road Camera" 3 "Interval Velocity" ;
VAL_ 922 LAS_TSRRightLaneStatus 0 " off" 1 " fusion mode" 2 " vision only mode" 3 " navigation only mode" 4 " reserved" 5 " reserved" 6 " reserved" 7 " Invalid" ;
VAL_ 922 LAS_TSRLeftLaneStatus 0 " off" 1 " fusion mode" 2 " vision only mode" 3 " navigation only mode" 4 " reserved" 5 " reserved" 6 " reserved" 7 " Invalid" ;
VAL_ 922 LAS_TSRRightLaneSpdLimit 0 "no speed limit detected" 1 "SL5" 2 "SL10" 3 "SL15" 4 "SL20" 5 "SL25" 6 "SL30" 7 "SL35" 8 "SL40" 9 "SL45" 10 "SL50" 11 "SL55" 12 "SL60" 13 "SL65" 14 "SL70" 15 "SL75" 16 "SL80" 17 "SL85" 18 "SL90" 19 "SL95" 20 "SL100" 21 "SL105" 22 "SL110" 23 "SL115" 24 "SL120" 25 "SL125" 26 "SL130" 27 "SL135" 28 "SL140" 29 "SL145" 30 "SL150" 31 "SL155" 32 "SL160" 33 " Reserved" 254 " Unlimited" 255 " SLEND" ;
VAL_ 922 LAS_TSRLeftLaneSpdLimit 0 "no speed limit detected" 1 "SL5" 2 "SL10" 3 "SL15" 4 "SL20" 5 "SL25" 6 "SL30" 7 "SL35" 8 "SL40" 9 "SL45" 10 "SL50" 11 "SL55" 12 "SL60" 13 "SL65" 14 "SL70" 15 "SL75" 16 "SL80" 17 "SL85" 18 "SL90" 19 "SL95" 20 "SL100" 21 "SL105" 22 "SL110" 23 "SL115" 24 "SL120" 25 "SL125" 26 "SL130" 27 "SL135" 28 "SL140" 29 "SL145" 30 "SL150" 31 "SL155" 32 "SL160" 33 " Reserved" 254 " Unlimited" 255 " SLEND" ;
VAL_ 922 LAS_TLAStopLine_HostLane 0 "0-250m" 251 "Reserved" 255 "Out of Range" ;
VAL_ 922 LAS_TLADistance_HostLane 0 "0-250m" 251 "Reserved" 255 "Out of Range" ;
VAL_ 922 LAS_TLACountDownTime_HostLane 0 "no display" 1 "1-120s倒计时" 121 "reserved" 127 "out of range" ;
VAL_ 922 LAS_TSRMandatorySign 0 "no display" 1 "单行路(直行)" 2 "步行" 3 "干路先行" 4 "会车先行" 5 "人行横道" 6 "公交线路专用车道" 7 "reserved" ;
VAL_ 922 LAS_TSRWarningSign 0 "no display" 1 "反向弯路" 2 "连续弯路" 3 "注意行人" 4 "注意儿童" 5 "易滑" 6 "隧道" 7 "慢行" 8 "施工" 9 "reserved" ;
VAL_ 922 LAS_TSRProhibitionSign 0 "no display" 1 "禁止通行" 2 "禁止驶入" 3 "禁止机动车通行" 4 "禁止向左转弯" 5 "禁止向右转弯" 6 "禁止直行" 7 "禁止掉头" 8 "禁止超车" 9 "解除禁止超车" 10 "禁止车辆临时或长时停放" 11 "禁止车辆长时停放" 12 "禁止鸣喇叭" 13 "停车让行" 14 "减速让行" 15 "会车让行" 16 "reserved" ;
VAL_ 922 LAS_OverspeedSoundWarningEnSt 0 "Off" 1 "On" ;
VAL_ 922 LAS_TSREnable 0 "off" 1 "on" ;
VAL_ 922 LAS_HMAEnableStatus 0 "off" 1 "on" ;
VAL_ 922 LAS_HMALightDistribution 0 " High beam not recommended" 1 " High beam recommended" ;
VAL_ 922 LAS_HMAStatus 0 " Off" 1 " Standby" 2 " Active" 3 " Failure" ;
VAL_ 922 LAS_TSRHostSpdLimitUnits 0 "no display" 1 "unit kph" 2 "unit mph" 3 "reserved" ;
VAL_ 922 LAS_TSRHostSpdLimit 0 "no speed limit detected" 1 "SL5" 2 "SL10" 3 "SL15" 4 "SL20" 5 "SL25" 6 "SL30" 7 "SL35" 8 "SL40" 9 "SL45" 10 "SL50" 11 "SL55" 12 "SL60" 13 "SL65" 14 "SL70" 15 "SL75" 16 "SL80" 17 "SL85" 18 "SL90" 19 "SL95" 20 "SL100" 21 "SL105" 22 "SL110" 23 "SL115" 24 "SL120" 25 "SL125" 26 "SL130" 27 "SL135" 28 "SL140" 29 "SL145" 30 "SL150" 31 "SL155" 32 "SL160" 33 " Reserved" 254 " Unlimited" 255 " SLEND" ;
VAL_ 922 LAS_TSRStatus 0 " off" 1 " fusion mode" 2 " vision only mode" 3 " navigation only mode" 4 " reserved" 5 " reserved" 6 " reserved" 7 " Invalid" ;
VAL_ 922 LAS_FrontCameraCalibrationStatus 0 " Calibration is ok" 1 " Calibration In Process" 2 " Calibration never done" 3 "  Calibration Failed" ;
VAL_ 922 LAS_FrontCameraFailureStatus 0 "No Error" 1 "camera blocked" 2 "temporary failure" 3 "permanent failure" ;
VAL_ 922 LAS_OverspeedWarningOffset 0 "-10~10km/h" 21 "Reserved" 31 "Invalid" ;
VAL_ 922 LAS_OverspeedWarningEnableStatus 0 "OFF" 1 "ON" ;
VAL_ 922 LAS_OverspeedSoundWarning 0 " No Warning" 1 " Warning" ;
VAL_ 922 LAS_OverspeedVisualWarning 0 " No Warning" 1 " Warning" ;
VAL_ 922 LAS_RoadSignCenterLatRange_Rlane 0 "(-8)+(0.05*X)" 321 "Reserved" ;
VAL_ 922 LAS_RoadSignCenterLngRange_RLane 0 "(0.1*X)m" 501 "Reserved" ;
VAL_ 922 LAS_RoadSignCenterLatRange_LLane 0 "(-8)+(0.05*X)" 321 "Reserved" ;
VAL_ 922 LAS_RoadSignCenterLngRange_LLane 0 "(0.1*X)m" 501 "Reserved" ;
VAL_ 922 LAS_RoadSignCenterLatRange_HLane 0 "(-8)+(0.05*X)" 321 "Reserved" ;
VAL_ 922 LAS_RoadSignCenterLngRange_HLane 0 "(0.1*X)m" 501 "Reserved" ;
VAL_ 922 LAS_CrosswalkLngRange_HLane 0 "0-250m" 251 "Reserved" 255 "Out of Range" ;
VAL_ 922 LAS_RoadSignType_RLane 0 "no detect" 1 "Forward" 2 "Left" 3 "Right" 4 "Turn Round to Left" 5 "Turn Round to Right" 6 "Forward +Left" 7 "Forward +Right" 8 "Forward +TurnRdToLeft" 9 "Forward +TurnRdToRight" 10 "TurnRd To Left or Right" 11 "Left +TurnRd to Left" 12 "Right +TurnRd to Right" 13 "Left +TurnRd to Right" 14 "Right +TurnRd to left" 15 "Left +Forward+Right" 16 "Left +Forward +TurnRd to Right" 17 "Right +Forward +TurnRd to Left" 18 "TurnRd to Rt+Forward +TurnRd to Lt" 19 "Reserved" 31 "invalid" ;
VAL_ 922 LAS_RoadSignType_LLane 0 "no detect" 1 "Forward" 2 "Left" 3 "Right" 4 "Turn Round to Left" 5 "Turn Round to Right" 6 "Forward +Left" 7 "Forward +Right" 8 "Forward +TurnRdToLeft" 9 "Forward +TurnRdToRight" 10 "TurnRd To Left or Right" 11 "Left +TurnRd to Left" 12 "Right +TurnRd to Right" 13 "Left +TurnRd to Right" 14 "Right +TurnRd to left" 15 "Left +Forward+Right" 16 "Left +Forward +TurnRd to Right" 17 "Right +Forward +TurnRd to Left" 18 "TurnRd to Rt+Forward +TurnRd to Lt" 19 "Reserved" 31 "invalid" ;
VAL_ 922 LAS_RoadSignType_HLane 0 "no detect" 1 "Forward" 2 "Left" 3 "Right" 4 "Turn Round to Left" 5 "Turn Round to Right" 6 "Forward +Left" 7 "Forward +Right" 8 "Forward +TurnRdToLeft" 9 "Forward +TurnRdToRight" 10 "TurnRd To Left or Right" 11 "Left +TurnRd to Left" 12 "Right +TurnRd to Right" 13 "Left +TurnRd to Right" 14 "Right +TurnRd to left" 15 "Left +Forward+Right" 16 "Left +Forward +TurnRd to Right" 17 "Right +Forward +TurnRd to Left" 18 "TurnRd to Rt+Forward +TurnRd to Lt" 19 "Reserved" 31 "invalid" ;
VAL_ 922 LAS_TLAArrowDirection_RightLane 0 "no display" 1 "Forward" 2 "Left" 3 " Forward +Left" 4 "Right" 5 " Forward +Right" 6 "Right+Left" 7 "Left+ Forward +Right" ;
VAL_ 922 LAS_TLAObjectType_RightLane 0 "no display" 1 "Round" 2 "Arrow" 3 "Turn Round" 4 "X-type" 5 "Arrow+Trun
0x6-0x7=reserved" ;
VAL_ 922 LAS_TLAObjectStatus_RightLane 0 "no display" 1 "Lighting" 2 "Flashing" 3 " Disappear" ;
VAL_ 922 LAS_TLAObjectColour_RightLane 0 "no display" 1 "Red" 2 "Yellow" 3 "Green" ;
VAL_ 922 LAS_TLAObjectDetection_RightLane 0 "Not Detected" 1 "Detected" ;
VAL_ 922 LAS_TLAArrowDirection_LeftLane 0 "no display" 1 "Forward" 2 "Left" 3 " Forward +Left" 4 "Right" 5 " Forward +Right" 6 "Right+Left" 7 "Left+ Forward +Right" ;
VAL_ 922 LAS_TLAObjectType_LeftLane 0 "no display" 1 "Round" 2 "Arrow" 3 "Turn Round" 4 "X-type" 5 "Arrow+Trun
0x6-0x7=reserved" ;
VAL_ 922 LAS_TLAObjectStatus_LeftLane 0 "no display" 1 "Lighting" 2 "Flashing" 3 " Disappear" ;
VAL_ 922 LAS_TLAObjectColour_LeftLane 0 "no display" 1 "Red" 2 "Yellow" 3 "Green" ;
VAL_ 922 LAS_TLAObjectDetection_LeftLane 0 "Not Detected" 1 "Detected" ;
VAL_ 922 LAS_TLAArrowDirection_HostLane 0 "no display" 1 "Forward" 2 "Left" 3 " Forward +Left" 4 "Right" 5 " Forward +Right" 6 "Right+Left" 7 "Left+ Forward +Right" ;
VAL_ 922 LAS_TLAObjectStatus_HostLane 0 "no display" 1 "Lighting" 2 "Flashing" 3 " Disappear" ;
VAL_ 922 LAS_TLAObjectType_HostLane 0 "no display" 1 "Round" 2 "Arrow" 3 "Turn Round" 4 "X-type" 5 "Arrow+Trun" 6 "reserved" ;
VAL_ 922 LAS_TLAObjectColour_HostLane 0 "no display" 1 "Red" 2 "Yellow" 3 "Green" ;
VAL_ 922 LAS_TLAObjectDetection_HostLane 0 "Not Detected" 1 "Detected" ;
VAL_ 922 LAS_TLAWarninglevel 0 " no warning" 1 " warning level 1" 2 " warning level 2" 3 " warning level 3." ;
VAL_ 922 LAS_TLAStatus 0 "OFF" 1 "Standby" 2 "Active" 3 "Failure" ;
VAL_ 922 LAS_TLAEnable 0 "OFF" 1 "ON" ;
VAL_ 853 EMS_CruiseDistance 0 "Inactive" 1 "Acitve" ;
VAL_ 853 EMS_CruiseSwitchSET 0 "Inactive" 1 "Acitve" ;
VAL_ 853 EMS_CruiseSwitchCANCEL 0 "Inactive" 1 "Acitve" ;
VAL_ 853 EMS_CruiseSwitchResume 0 "Inactive" 1 "Acitve" ;
VAL_ 853 EMS_CruiseSwitchOnOff 0 "Off" 1 "On" ;
VAL_ 941 DVR_SdcardErrorStatus 0 "no error（Sd卡无错误）" 1 "no sdcard（Sd卡未挂载）" 2 "sdcard error（Sd卡写错误）" 3 "sdcard format error（Sd卡格式错误）" 4 "sdcard insufficient（Sd卡容量不足）" 5 "sdcard speed low（Sd卡速度过低）" 6 "sdcard restoring(reserved)（Sd卡正在恢复文件）" 7 "sdcard too large(Sd卡容量过大)" ;
VAL_ 943 HU_LaneConfluenceDis 0 " 0~600m" 61 "Out of Range" 62 "reserved" 63 "unknown" ;
VAL_ 943 HU_LaneConfluence 0 "unknown" 1 "前方左侧合流" 2 "前方右侧合流
0x3=invalid" ;
VAL_ 943 HU_RampDistance 0 " 0~3000m" 301 "reserved" 1022 "Out of Range" 1023 "unknown" ;
VAL_ 943 HU_NavSpeedLimitType 0 "Unknown" 1 "Speed-Limit Sign" 2 "Road Camera" 3 "Interval Velocity" ;
VAL_ 943 HU_CurveDistance 0 " 0~600m" 61 "Out of Range" 62 "reserved" 63 "unknown" ;
VAL_ 943 HU_EnterCurveInfo 0 " unknown" 1 "弯道进口" 2 "弯道中" 3 "弯道出口" ;
VAL_ 943 HU_NavCurrentRoadType 0 "Road Type Unknown: Small road, Walking Street" 1 "Road Type Class 1: Secondary Roads" 2 "Road Type Class 2: Mainly Road in City" 3 "Road Type Class 3: Mainly Road in City, Normal Province Road, Mainly street" 4 "Road Type Class 4: Province Road, Mainly Road " 5 "Road Type Class 5: Highway, National Road, Speed road" 6 "Reserved

2.搭载ADAS:
0x0=未知" 1 "城市主要道路" 2 "城市快速路" 3 "省道，县道" 4 "国道" 5 "高速路" 6 "次要道路，普通道路，乡公路，县乡内部路" 7 "预留" ;
VAL_ 943 HU_EnterRampInfo 0 "Unknown" 1 "匝道进口" 2 "匝道中" 3 "匝道出口" ;
VAL_ 943 HU_RampInfo 0 "Unknown" 1 "有匝道，但本车不出高速" 2 "本车通过匝道进入高速" 3 "本车通过匝道出高速" ;
VAL_ 943 HU_NavStatus 0 "Normal" 1 "Error" ;
VAL_ 943 HU_NavSpeedLimitUnits 3 "reserved" 2 "unit mph" 1 "unit kph" 0 "unknown." ;
VAL_ 943 HU_NavSpeedLimitStatus 3 "reserved" 2 "reserved" 1 "invalid" 0 "valid" ;
VAL_ 943 HU_NavSpeedLimit 0 "Unlimited" 1 "SL 5" 2 "SL 10" 32 "SL 160" 254 "Unknown" 255 "Invalid" ;
VAL_ 943 HU_SlopeGradientFar 1023 " unknown" ;
VAL_ 943 HU_SlopeGradient 1023 " unknown" ;
VAL_ 943 HU_SpeedLimitDistance 0 " 0~600m" 61 "Out of Range" 62 "reserved" 63 "unknown" ;
VAL_ 957 HU_CSLAEnable 0 "OFF" 1 "All Speed-Limit" 2 "Road Camera" 3 "invalid" ;
VAL_ 957 HU_ELKEnable 0 "Inactive" 1 "OFF" 2 "ON" 3 "Reserved" ;
VAL_ 957 HU_TLAEnable 0 "Inactive" 1 "OFF" 2 "ON" 3 "Reserved" ;
VAL_ 964 HU_MapMatchStatus 0 "Successl" 1 "Fail" 2 "保留" 3 "无效" ;
VAL_ 964 HU_MapDataUpdateStatus 0 "未更新" 1 "1个月内更新" 2 "3个月内更新" 3 "6个月内更新" 4 "1年内更新" 5 " reserved" 7 "Invalid" ;
VAL_ 964 HU_SlopeGradient_300m 1023 " unknown" ;
VAL_ 964 HU_RoadCurvature_600m 0 " -0.16192 ~ -0.00001，负数代表向左的弯道曲率" 8191 " 0，代表曲率为0的直道" 512 " 0.00001 ~ 0.16192，正数代表向右的弯道曲率" 5631 " unknown" ;
VAL_ 964 HU_RoadCurvature_400m 0 " -0.16192 ~ -0.00001，负数代表向左的弯道曲率" 8191 " 0，代表曲率为0的直道" 512 " 0.00001 ~ 0.16192，正数代表向右的弯道曲率" 5375 " unknown" ;
VAL_ 964 HU_RoadCurvature_300m 0 " -0.16192 ~ -0.00001，负数代表向左的弯道曲率" 8191 " 0，代表曲率为0的直道" 512 " 0.00001 ~ 0.16192，正数代表向右的弯道曲率" 5119 " unknown" ;
VAL_ 964 HU_RoadCurvature_100m 0 " -0.16192 ~ -0.00001，负数代表向左的弯道曲率" 8191 " 0，代表曲率为0的直道" 512 " 0.00001 ~ 0.16192，正数代表向右的弯道曲率" 4863 " unknown" ;
VAL_ 964 HU_RoadCurvature_90m 0 " -0.16192 ~ -0.00001，负数代表向左的弯道曲率" 8191 " 0，代表曲率为0的直道" 512 " 0.00001 ~ 0.16192，正数代表向右的弯道曲率" 4607 " unknown" ;
VAL_ 964 HU_RoadCurvature_80m 0 " -0.16192 ~ -0.00001，负数代表向左的弯道曲率" 8191 " 0，代表曲率为0的直道" 512 " 0.00001 ~ 0.16192，正数代表向右的弯道曲率" 4351 " unknown" ;
VAL_ 964 HU_RoadCurvature_70m 0 " -0.16192 ~ -0.00001，负数代表向左的弯道曲率" 8191 " 0，代表曲率为0的直道" 512 " 0.00001 ~ 0.16192，正数代表向右的弯道曲率" 2559 " unknown" ;
VAL_ 964 HU_RoadCurvature_60m 0 " -0.16192 ~ -0.00001，负数代表向左的弯道曲率" 8191 " 0，代表曲率为0的直道" 512 " 0.00001 ~ 0.16192，正数代表向右的弯道曲率" 2303 " unknown" ;
VAL_ 964 HU_RoadCurvature_50m 0 " -0.16192 ~ -0.00001，负数代表向左的弯道曲率" 8191 " 0，代表曲率为0的直道" 512 " 0.00001 ~ 0.16192，正数代表向右的弯道曲率" 2047 " unknown" ;
VAL_ 964 HU_RoadCurvature_40m 0 " -0.16192 ~ -0.00001，负数代表向左的弯道曲率" 8191 " 0，代表曲率为0的直道" 512 " 0.00001 ~ 0.16192，正数代表向右的弯道曲率" 1791 " unknown" ;
VAL_ 964 HU_RoadCurvature_30m 0 " -0.16192 ~ -0.00001，负数代表向左的弯道曲率" 8191 " 0，代表曲率为0的直道" 512 " 0.00001 ~ 0.16192，正数代表向右的弯道曲率" 1535 " unknown" ;
VAL_ 964 HU_RoadCurvature_20m 0 " -0.16192 ~ -0.00001，负数代表向左的弯道曲率" 8191 " 0，代表曲率为0的直道" 512 " 0.00001 ~ 0.16192，正数代表向右的弯道曲率" 1279 " unknown" ;
VAL_ 964 HU_RoadCurvature_10m 0 " -0.16192 ~ -0.00001，负数代表向左的弯道曲率" 8191 " 0，代表曲率为0的直道" 512 " 0.00001 ~ 0.16192，正数代表向右的弯道曲率" 1023 " unknown" ;
VAL_ 964 HU_Road_TrafficFlow 0 "unknown" 1 "畅通" 2 "缓行" 3 " 拥堵，0x4=严重拥堵，0x5=无交通流,0x6=reserved.0x7=invalid" ;
VAL_ 964 HU_Lane_Changtype 0 "NO change，0x1=Merge" 2 "Separate，
0x3=invalid" ;
VAL_ 964 HU_To_NumchangeOfLanes_Dist 0 " 0~600m" 61 "Out of Range" 62 "reserved" 63 "unknown" ;
VAL_ 964 HU_To_Branch_Dis 0 " 0~600m" 61 "Out of Range" 62 "reserved" 63 "unknown" ;
VAL_ 964 HU_BranchInfo 0 "unknown" 1 "有岔道，但本车不通过岔道" 2 "有岔道，本车通过岔道
0x3=预留" ;
VAL_ 964 HU_To_TrafficAccident_Dis 0 " 0~600m" 61 "Out of Range" 62 "reserved" 63 "unknown" ;
VAL_ 964 HU_TrafficAccident_Info 0 "无交通事故" 1 "有交通事故
0x2=预留
0x3=invalid" ;
VAL_ 964 HU_To_Construction_Dis 0 " 0~600m" 61 "Out of Range" 62 "reserved" 63 "unknown" ;
VAL_ 964 HU_Construction_Info 0 "路径无施工区" 1 "路径有施工区" 2 "预留
0x3=invalid" ;
VAL_ 964 HU_TollDis 0 " 0~600m" 61 "Out of Range" 62 "reserved" 63 "unknown" ;
VAL_ 964 HU_TollInfo 0 "=路径无收费站
0x1=路径有收费站
0x2=预留
0x3=invalid" ;
VAL_ 964 HU_FallingRockDi 0 " 0~600m" 61 "Out of Range" 62 "reserved" 63 "unknown" ;
VAL_ 964 HU_FallingRockInfo 0 "=路径无落石
0x1=路径有落石
0x2=预留
0x3=invalid" ;
VAL_ 964 HU_LaneCnt 0 "unknown,0x1-0x5=当前道路车道数量，0x6=大于等于6,,0x7=当前道路单项行驶且车辆逆行" ;
VAL_ 964 HU_ForwardRoadType 0 "Road Type Unknown: Small road, Walking Street" 1 "Road Type Class 1: Secondary Roads" 2 "Road Type Class 2: Mainly Road in City" 3 "Road Type Class 3: Mainly Road in City, Normal Province Road, Mainly street" 4 "Road Type Class 4: Province Road, Mainly Road " 5 "Road Type Class 5: Highway, National Road, Speed road" 6 "Reserved

2.搭载ADAS:
0x0=未知" 1 "城市主要道路" 2 "城市快速路" 3 "省道，县道" 4 "国道" 5 "高速路" 6 "次要道路，普通道路，乡公路，县乡内部路" 7 "预留" ;
VAL_ 964 HU_RampSide 0 "Unknown" 1 "道路左边" 2 "道路右边" 3 "直线匝道" ;
VAL_ 964 HU_NavGuiganceStatus 0 "没有导航引导路径" 1 "有导航引导路径" 2 "Reserved" 3 "Reserved" ;
VAL_ 964 HU_SlopeDistance 0 " 0~600m" 61 "Out of Range" 62 "reserved" 63 "unknown" ;
VAL_ 964 HU_Byroad 0 "unknown" 1 "有岔路" 2 "无岔路" 3 "reserved" ;
VAL_ 964 HU_TunnelLength 0 " 0~600m" 61 "Out of Range" 62 "reserved" 63 "unknown" ;
VAL_ 964 HU_RoadCurvatureFar 0 " -0.16192 ~ -0.00001，负数代表向左的弯道曲率" 8191 " 0，代表曲率为0的直道" 512 " 0.00001 ~ 0.16192，正数代表向右的弯道曲率" 1023 " unknown" ;
VAL_ 964 HU_TunnelDistance 0 " 0~600m" 61 "Out of Range" 62 "reserved" 63 "unknown" ;
VAL_ 964 HU_RoadCurvature 0 " -0.16192 ~ -0.00001，负数代表向左的弯道曲率" 8191 " 0，代表曲率为0的直道" 512 " 0.00001 ~ 0.16192，正数代表向右的弯道曲率" 1023 " unknown" ;
VAL_ 964 HU_EnterSlopeInfo 0 "unknown" 1 "坡道入口" 2 "坡道中" 3 "坡道出口" ;
VAL_ 964 HU_EnterTunnelInfo 0 " unknown" 1 "隧道入口" 2 "隧道中" 3 "隧道出口" ;
